VERSION "HNNBNNNYNNNNNNNNNNNNNNNNNNNNNNNNNNNNNNNNNN/4/%%%/4/'%**4NNN///"

NS_ :

BS_:

BU_: BAP_Tester ELV Gateway_Max HUD Kombi

BO_ 988 Gateway_73: 8 Gateway_Max
 SG_ Motor_12_alt : 0|1@1+ (1.0,0.0) [0.0|1] ""  Vector__XXX
 SG_ ESP_07_alt : 1|1@1+ (1.0,0.0) [0.0|1] ""  Kombi
 SG_ Getriebe_11_alt : 2|1@1+ (1.0,0.0) [0.0|1] ""  Vector__XXX
 SG_ Getriebe_13_alt : 3|1@1+ (1.0,0.0) [0.0|1] ""  Vector__XXX
 SG_ Getriebe_17_alt : 4|1@1+ (1.0,0.0) [0.0|1] ""  Vector__XXX
 SG_ TSK_06_alt : 5|1@1+ (1.0,0.0) [0.0|1] ""  Kombi
 SG_ Getriebe_14_alt : 6|1@1+ (1.0,0.0) [0.0|1] ""  Vector__XXX
 SG_ ESP_50_alt : 7|1@1+ (1.0,0.0) [0.0|1] ""  Vector__XXX
 SG_ MO_QBit_Drehzahl_01 : 8|1@1+ (1.0,0.0) [0.0|1] ""  Vector__XXX
 SG_ MKE_Texte : 9|2@1+ (1.0,0.0) [0.0|3] ""  Vector__XXX
 SG_ MKE_Stufe : 11|3@1+ (1.0,0.0) [0.0|7] ""  Vector__XXX
 SG_ TSK_Hauptschalter_GRA_ACC : 14|2@1+ (1.0,0.0) [0.0|3] ""  Kombi
 SG_ MO_Drehzahl_01 : 16|16@1+ (0.25,0) [0.00|16383.00] "Unit_MinutInver"  Vector__XXX
 SG_ TSK_Status : 32|3@1+ (1.0,0.0) [0.0|7] ""  Vector__XXX
 SG_ EPB_Schalterposition : 35|2@1+ (1.0,0.0) [0.0|3] ""  Vector__XXX
 SG_ GE_LaunchControl : 37|1@1+ (1.0,0.0) [0.0|1] ""  Vector__XXX
 SG_ GE_Fahrstufe : 40|4@1+ (1.0,0.0) [0.0|15] ""  Vector__XXX
 SG_ GE_Ursache_Fahrstufe_N : 44|1@1+ (1.0,0.0) [0.0|1] ""  Vector__XXX
 SG_ GE_Notlauf : 45|1@1+ (1.0,0.0) [0.0|1] ""  Vector__XXX
 SG_ ESP_Rollenmodus_Deaktivieren : 46|1@1+ (1.0,0.0) [0.0|1] ""  Kombi
 SG_ GE_Freilauf_Status : 47|3@1+ (1.0,0.0) [0.0|7] ""  Vector__XXX
 SG_ GE_Sperr_Info_WFS : 50|1@1+ (1.0,0.0) [0.0|1] ""  Vector__XXX
 SG_ TSK_Limiter_ausgewaehlt : 51|1@1+ (1.0,0.0) [0.0|1] ""  Vector__XXX
 SG_ GE_Veto_Rollfaehigkeit : 52|1@1+ (1.0,0.0) [0.0|1] ""  Vector__XXX
 SG_ EPB_Status_02 : 53|3@1+ (1.0,0.0) [0.0|7] ""  Vector__XXX
 SG_ ACC_Status_ACC : 56|3@1+ (1.0,0.0) [0.0|7] ""  Vector__XXX
 SG_ ACC_18_alt : 59|1@1+ (1.0,0.0) [0.0|1] ""  Vector__XXX
 SG_ Bel_DiETa_Mode2 : 60|2@1+ (1.0,0.0) [0.0|3] ""  Vector__XXX

BO_ 1002 Gateway_77: 8 Gateway_Max
 SG_ ESP_05_alt : 0|1@1+ (1.0,0.0) [0.0|1] ""  Vector__XXX
 SG_ Getriebe_14_alt : 1|1@1+ (1.0,0.0) [0.0|1] ""  Kombi
 SG_ Motor_11_alt : 2|1@1+ (1.0,0.0) [0.0|1] ""  Vector__XXX
 SG_ Motor_20_alt : 3|1@1+ (1.0,0.0) [0.0|1] ""  Vector__XXX
 SG_ EBKV_03_alt : 4|1@1+ (1.0,0.0) [0.0|1] ""  Vector__XXX
 SG_ AWV_03_alt : 5|1@1+ (1.0,0.0) [0.0|1] ""  Vector__XXX
 SG_ AWV_Verz_Freigabe : 6|1@1+ (1.0,0.0) [0.0|1] ""  Vector__XXX
 SG_ AWV_Verz_Anf : 7|10@1+ (0.024,-20.016) [-20.016|4.512] "Unit_MeterPerSeconSquar"  Vector__XXX
 SG_ Bel_DiETa_Mode : 17|2@1+ (1.0,0.0) [0.0|3] ""  Vector__XXX
 SG_ PaCo_DiETa_LED : 19|2@1+ (1.0,0.0) [0.0|3] ""  Vector__XXX
 SG_ RTM_Warnstatus : 21|2@1+ (1.0,0.0) [0.0|3] ""  Vector__XXX
 SG_ EBKV_Fahrer_bremst : 23|1@1+ (1.0,0.0) [0.0|1] ""  Vector__XXX
 SG_ AWV_Zielobjekttyp : 24|4@1+ (1.0,0.0) [0.0|15] ""  Vector__XXX
 SG_ ESP_Bremsdruck : 28|10@1+ (0.3,-30) [-30.0|276.6] "Unit_Bar"  Vector__XXX
 SG_ MO_Mom_Ist_Summe : 38|10@1+ (1,-509) [-509|509] ""  Vector__XXX
 SG_ MO_Fahrpedalrohwert_01 : 48|8@1+ (0.4,0) [0.0|101.6] "Unit_PerCent"  Vector__XXX
 SG_ GE_Sumpftemperatur : 56|8@1+ (1,-58) [-58|196] "Unit_DegreCelsi"  Kombi

BO_ 1003 Gateway_78: 8 Gateway_Max
 SG_ LH_EPS_02_alt : 0|1@1+ (1.0,0.0) [0.0|1] ""  Vector__XXX
 SG_ LIN_2_alt : 1|1@1+ (1.0,0.0) [0.0|1] ""  Vector__XXX
 SG_ Parkhilfe_01_alt : 2|1@1+ (1.0,0.0) [0.0|1] ""  Vector__XXX
 SG_ Motor_20_alt : 3|1@1+ (1.0,0.0) [0.0|1] ""  Vector__XXX
 SG_ LR_HZG_01_alt : 4|1@1+ (1.0,0.0) [0.0|1] ""  Vector__XXX
 SG_ Areaview_01_alt : 5|1@1+ (1.0,0.0) [0.0|1] ""  Vector__XXX
 SG_ EBKV_03_alt : 6|1@1+ (1.0,0.0) [0.0|1] ""  Vector__XXX
 SG_ ESP_50_alt : 7|1@1+ (1.0,0.0) [0.0|1] ""  Vector__XXX
 SG_ EPS_Lastinfo : 8|8@1+ (1,0) [0|253] "Unit_Amper"  Vector__XXX
 SG_ EFF_Verbrauch_STH : 16|7@1+ (0.01,0) [0.00|1.26] "Unit_LiterPerHour"  Kombi
 SG_ LR_HZG_Taster_on_off : 23|1@1+ (1.0,0.0) [0.0|1] ""  Vector__XXX
 SG_ LR_HZG_Temp_Sensor : 24|8@1+ (1,-50) [-50|104] "Unit_DegreCelsi"  Vector__XXX
 SG_ MFL_Signalhorn : 32|1@1+ (1.0,0.0) [0.0|1] ""  Vector__XXX
 SG_ EBKV_Fahrer_bremst : 33|1@1+ (1.0,0.0) [0.0|1] ""  Vector__XXX
 SG_ PH_Stoermeldung : 34|4@1+ (1.0,0.0) [0.0|15] ""  Vector__XXX
 SG_ MO_temporaere_Fahrerabwesenheit : 38|1@1+ (1.0,0.0) [0.0|1] ""  Vector__XXX
 SG_ AV_Umfeldbeleuchtung_Anf : 39|1@1+ (1.0,0.0) [0.0|1] ""  Vector__XXX
 SG_ MO_Fahrpedalrohwert_01 : 40|8@1+ (0.4,0) [0.0|101.6] "Unit_PerCent"  Vector__XXX
 SG_ LR_HZG_Konfiguration : 48|3@1+ (1.0,0.0) [0.0|7] ""  Vector__XXX
 SG_ EBKV_QBit_Fahrer_bremst : 51|1@1+ (1.0,0.0) [0.0|1] ""  Vector__XXX
 SG_ MO_QBit_Fahrpedalwerte_01 : 52|1@1+ (1.0,0.0) [0.0|1] ""  Vector__XXX
 SG_ ESP_QBit_Bremsdruck : 53|1@1+ (1.0,0.0) [0.0|1] ""  Vector__XXX
 SG_ ESP_Bremsdruck : 54|10@1+ (0.3,-30) [-30.0|276.6] "Unit_Bar"  Vector__XXX

BO_ 2583695384 Gateway_AuthTime_Req: 8 Gateway_Max
 SG_ Gateway_AuthTime_Req_Data : 0|64@1+ (1.0,0.0) [0.0|18446744073709551615] ""  Kombi

BO_ 2583826456 Gateway_AuthTime_Resp: 8 Kombi
 SG_ Gateway_AuthTime_Resp_Data : 0|64@1+ (1.0,0.0) [0.0|18446744073709551615] ""  Gateway_Max

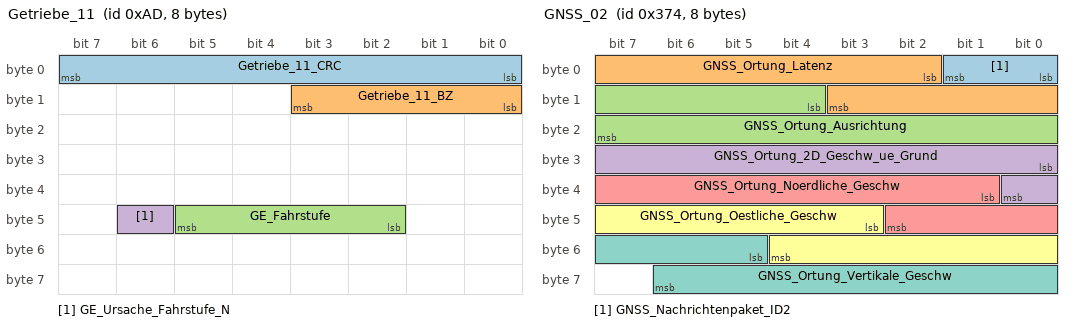
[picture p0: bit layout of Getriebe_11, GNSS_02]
BO_ 173 Getriebe_11: 8 Gateway_Max
 SG_ Getriebe_11_CRC : 0|8@1+ (1,0) [0|255] ""  Vector__XXX
 SG_ Getriebe_11_BZ : 8|4@1+ (1,0) [0|15] ""  Vector__XXX
 SG_ GE_Fahrstufe : 42|4@1+ (1.0,0.0) [0.0|15] ""  ELV
 SG_ GE_Ursache_Fahrstufe_N : 46|1@1+ (1.0,0.0) [0.0|1] ""  Vector__XXX

BO_ 884 GNSS_02: 8 Gateway_Max
 SG_ GNSS_Nachrichtenpaket_ID2 : 0|2@1+ (1,0) [0|3] "Unit_Bit"  Vector__XXX
 SG_ GNSS_Ortung_Latenz : 2|10@1+ (1,0) [0|1021] "Unit_MilliSecon"  Vector__XXX
 SG_ GNSS_Ortung_Ausrichtung : 12|12@1+ (0.1,0) [0.0|359.9] "Unit_DegreOfArc"  Vector__XXX
 SG_ GNSS_Ortung_2D_Geschw_ue_Grund : 24|9@1+ (0.25,0) [0.00|125.00] "Unit_MeterPerSecon"  Kombi
 SG_ GNSS_Ortung_Noerdliche_Geschw : 33|10@1+ (0.25,-125) [-125.00|125.00] "Unit_MeterPerSecon"  Vector__XXX
 SG_ GNSS_Ortung_Oestliche_Geschw : 43|10@1+ (0.25,-125) [-125.00|125.00] "Unit_MeterPerSecon"  Vector__XXX
 SG_ GNSS_Ortung_Vertikale_Geschw : 53|10@1+ (0.25,-125) [-125.00|125.00] "Unit_MeterPerSecon"  Vector__XXX

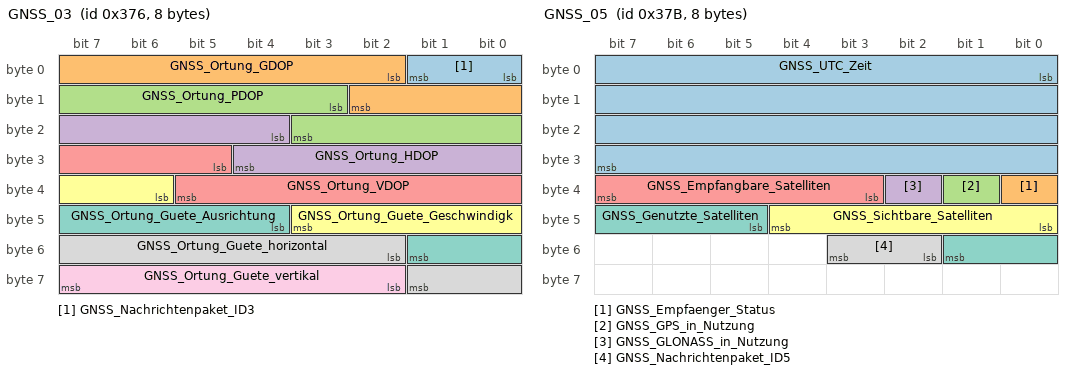
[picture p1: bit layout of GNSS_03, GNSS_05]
BO_ 886 GNSS_03: 8 Gateway_Max
 SG_ GNSS_Nachrichtenpaket_ID3 : 0|2@1+ (1,0) [0|3] "Unit_Bit"  Vector__XXX
 SG_ GNSS_Ortung_GDOP : 2|9@1+ (0.1,0) [0.0|50.0] "Unit_None"  Vector__XXX
 SG_ GNSS_Ortung_PDOP : 11|9@1+ (0.1,0) [0.0|50.0] "Unit_None"  Vector__XXX
 SG_ GNSS_Ortung_HDOP : 20|9@1+ (0.1,0) [0.0|50.0] "Unit_None"  Vector__XXX
 SG_ GNSS_Ortung_VDOP : 29|9@1+ (0.1,0) [0.0|50.0] "Unit_None"  Vector__XXX
 SG_ GNSS_Ortung_Guete_Geschwindigk : 38|6@1+ (0.05,0) [0.00|3.05] "Unit_MeterPerSecon"  Kombi
 SG_ GNSS_Ortung_Guete_Ausrichtung : 44|6@1+ (0.15,0) [0.00|9.15] "Unit_DegreOfArc"  Vector__XXX
 SG_ GNSS_Ortung_Guete_horizontal : 50|8@1+ (1,0) [0|250] "Unit_Meter"  Vector__XXX
 SG_ GNSS_Ortung_Guete_vertikal : 58|6@1+ (2,0) [0|122] "Unit_Meter"  Vector__XXX

BO_ 891 GNSS_05: 8 Gateway_Max
 SG_ GNSS_UTC_Zeit : 0|32@1+ (1,0) [1|4294967295] "Unit_Secon"  Kombi
 SG_ GNSS_Empfaenger_Status : 32|1@1+ (1.0,0.0) [0.0|1] ""  Vector__XXX
 SG_ GNSS_GPS_in_Nutzung : 33|1@1+ (1.0,0.0) [0.0|1] ""  Vector__XXX
 SG_ GNSS_GLONASS_in_Nutzung : 34|1@1+ (1.0,0.0) [0.0|1] ""  Vector__XXX
 SG_ GNSS_Empfangbare_Satelliten : 35|5@1+ (1,0) [1|30] "Unit_None"  Vector__XXX
 SG_ GNSS_Sichtbare_Satelliten : 40|5@1+ (1,0) [1|30] "Unit_None"  Vector__XXX
 SG_ GNSS_Genutzte_Satelliten : 45|5@1+ (1,0) [1|30] "Unit_None"  Vector__XXX
 SG_ GNSS_Nachrichtenpaket_ID5 : 50|2@1+ (1,0) [0|3] "Unit_Bit"  Kombi

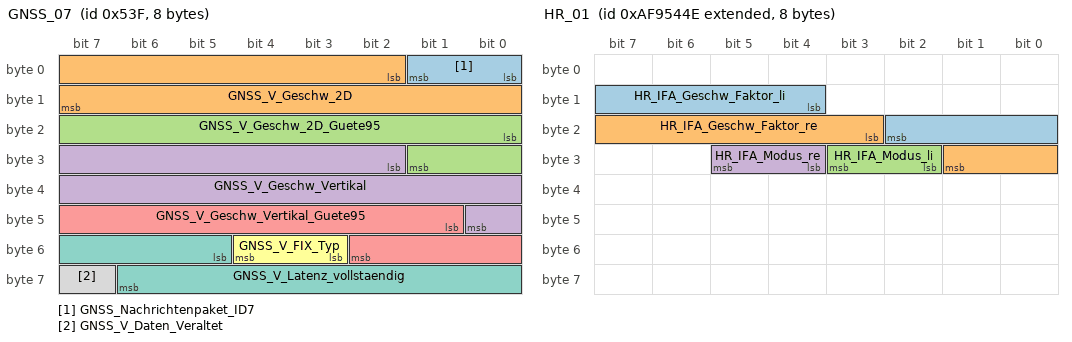
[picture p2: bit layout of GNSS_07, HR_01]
BO_ 1343 GNSS_07: 8 Gateway_Max
 SG_ GNSS_Nachrichtenpaket_ID7 : 0|2@1+ (1,0) [0|3] "Unit_None"  Kombi
 SG_ GNSS_V_Geschw_2D : 2|14@1+ (0.01,0) [0.00|163.00] "Unit_MeterPerSecon"  Kombi
 SG_ GNSS_V_Geschw_2D_Guete95 : 16|10@1+ (0.01,0) [0.00|10.00] "Unit_MeterPerSecon"  Kombi
 SG_ GNSS_V_Geschw_Vertikal : 26|15@1+ (0.01,-163) [-163.00|163.00] "Unit_MeterPerSecon"  Kombi
 SG_ GNSS_V_Geschw_Vertikal_Guete95 : 41|10@1+ (0.01,0) [0.00|10.00] "Unit_MeterPerSecon"  Kombi
 SG_ GNSS_V_FIX_Typ : 51|2@1+ (1.0,0.0) [0.0|3] ""  Kombi
 SG_ GNSS_V_Latenz_vollstaendig : 53|10@1+ (1,0) [0|1021] "Unit_MilliSecon"  Kombi
 SG_ GNSS_V_Daten_Veraltet : 63|1@1+ (1.0,0.0) [0.0|1] ""  Kombi

BO_ 299 GRA_ACC_01: 8 Gateway_Max
 SG_ GRA_ACC_01_CRC : 0|8@1+ (1,0) [0|255] ""  Vector__XXX
 SG_ GRA_ACC_01_BZ : 8|4@1+ (1,0) [0|15] ""  Vector__XXX
 SG_ GRA_Hauptschalter : 12|1@1+ (1.0,0.0) [0.0|1] ""  Vector__XXX
 SG_ GRA_Abbrechen : 13|1@1+ (1.0,0.0) [0.0|1] ""  Vector__XXX
 SG_ GRA_Typ_Hauptschalter : 14|1@1+ (1.0,0.0) [0.0|1] ""  Vector__XXX
 SG_ GRA_Limiter : 15|1@1+ (1.0,0.0) [0.0|1] ""  Vector__XXX
 SG_ GRA_Tip_Setzen : 16|1@1+ (1.0,0.0) [0.0|1] ""  HUD
 SG_ GRA_Tip_Hoch : 17|1@1+ (1.0,0.0) [0.0|1] ""  HUD
 SG_ GRA_Tip_Runter : 18|1@1+ (1.0,0.0) [0.0|1] ""  HUD
 SG_ GRA_Tip_Wiederaufnahme : 19|1@1+ (1.0,0.0) [0.0|1] ""  HUD
 SG_ GRA_Verstellung_Zeitluecke : 20|2@1+ (1.0,0.0) [0.0|3] ""  Vector__XXX
 SG_ GRA_Codierung : 22|2@1+ (1.0,0.0) [0.0|3] ""  Vector__XXX
 SG_ GRA_Fehler : 24|1@1+ (1.0,0.0) [0.0|1] ""  Vector__XXX
 SG_ GRA_LIM_Taste_verfuegbar : 25|1@1+ (1.0,0.0) [0.0|1] ""  Vector__XXX
 SG_ GRA_Tip_Stufe_2 : 26|1@1+ (1.0,0.0) [0.0|1] ""  Vector__XXX
 SG_ GRA_Typ_Bedienteil : 27|3@1+ (1.0,0.0) [0.0|7] ""  Vector__XXX
 SG_ GRA_TravelAssist : 30|1@1+ (1.0,0.0) [0.0|1] ""  Vector__XXX
 SG_ GRA_PIT_Limiter : 31|1@1+ (1.0,0.0) [0.0|1] ""  Vector__XXX
 SG_ GRA_reserveByte5 : 32|8@1+ (1.0,0.0) [0.0|255] ""  Vector__XXX
 SG_ GRA_reserveByte6 : 40|8@1+ (1.0,0.0) [0.0|255] ""  Vector__XXX
 SG_ GRA_reserveByte7 : 48|8@1+ (1.0,0.0) [0.0|255] ""  Vector__XXX
 SG_ GRA_reserveByte8 : 56|8@1+ (1.0,0.0) [0.0|255] ""  Vector__XXX

BO_ 1410 HDSG_01: 4 Gateway_Max
 SG_ HD_Endstellung_oben : 0|1@1+ (1.0,0.0) [0.0|1] ""  Vector__XXX
 SG_ HD_Endstellung_unten : 1|1@1+ (1.0,0.0) [0.0|1] ""  Vector__XXX
 SG_ HD_Bewegung_auf : 2|1@1+ (1.0,0.0) [0.0|1] ""  Vector__XXX
 SG_ HD_Bewegung_zu : 3|1@1+ (1.0,0.0) [0.0|1] ""  Vector__XXX
 SG_ HD_Innentaster_betaetigt : 4|1@1+ (1.0,0.0) [0.0|1] ""  Vector__XXX
 SG_ HD_Kupp_Ma_aktiv : 5|1@1+ (1.0,0.0) [0.0|1] ""  Vector__XXX
 SG_ HD_Kupp_Sl_aktiv : 6|1@1+ (1.0,0.0) [0.0|1] ""  Vector__XXX
 SG_ HD_UeKB_erkannt : 7|1@1+ (1.0,0.0) [0.0|1] ""  Vector__XXX
 SG_ HD_Position : 8|8@1+ (1,0) [0|100] "Unit_PerCent"  Vector__XXX
 SG_ HD_SG_MA_KD_Fehler : 16|1@1+ (1.0,0.0) [0.0|1] ""  Vector__XXX
 SG_ HD_SG_SL_KD_Fehler : 17|1@1+ (1.0,0.0) [0.0|1] ""  Vector__XXX
 SG_ HD_Taster_defekt : 18|1@1+ (1.0,0.0) [0.0|1] ""  Vector__XXX
 SG_ HD_Spannung : 19|1@1+ (1.0,0.0) [0.0|1] ""  Vector__XXX
 SG_ HD_Rueckmeld_prog : 20|1@1+ (1.0,0.0) [0.0|1] ""  Vector__XXX
 SG_ HD_Verriegelungstaster_betaetigt : 21|1@1+ (1.0,0.0) [0.0|1] ""  Vector__XXX
 SG_ HD_Verr_Taster_betaetigt_inv : 22|1@1+ (1.0,0.0) [0.0|1] ""  Vector__XXX
 SG_ HD_ZZH_Schalter_S3 : 23|1@1+ (1.0,0.0) [0.0|1] ""  Vector__XXX
 SG_ HDSG_Anf_Umluftklappe : 31|1@1+ (1.0,0.0) [0.0|1] ""  Vector__XXX

BO_ 588 Heckradar_01: 16 Gateway_Max
 SG_ SWA_LED_Hell_BFS : 12|7@1+ (1,0) [0|100] "Unit_PerCent"  Vector__XXX
 SG_ SWA_LED_Hell_FS : 19|7@1+ (1,0) [0|100] "Unit_PerCent"  Vector__XXX
 SG_ SWA_LED_Ausgabemodus_BFS : 26|3@1+ (1.0,0.0) [0.0|7] ""  Vector__XXX
 SG_ SWA_LED_Ausgabemodus_FS : 29|3@1+ (1.0,0.0) [0.0|7] ""  Vector__XXX
 SG_ SWA_Status : 32|2@1+ (1.0,0.0) [0.0|3] ""  Vector__XXX
 SG_ ASW_Ton_Richtung_VL : 34|1@1+ (1.0,0.0) [0.0|1] ""  Vector__XXX
 SG_ ASW_Ton_Richtung_VR : 35|1@1+ (1.0,0.0) [0.0|1] ""  Vector__XXX
 SG_ ASW_Ton_Richtung_HL : 36|1@1+ (1.0,0.0) [0.0|1] ""  HUD
 SG_ ASW_Ton_Richtung_HR : 37|1@1+ (1.0,0.0) [0.0|1] ""  HUD
 SG_ SWA_Status_System : 38|2@1+ (1.0,0.0) [0.0|3] ""  Vector__XXX
 SG_ SWA_Brightness_Mode_FPM : 40|4@1+ (1.0,0.0) [0.0|15] ""  Vector__XXX
 SG_ SWA_Status_KuFu : 44|2@1+ (1.0,0.0) [0.0|3] ""  Kombi
 SG_ SWA_Infostufe_Assist_li : 46|1@1+ (1.0,0.0) [0.0|1] ""  Vector__XXX
 SG_ SWA_Infostufe_Assist_re : 47|1@1+ (1.0,0.0) [0.0|1] ""  Vector__XXX
 SG_ SWA_Warnstufe_Assist_li : 48|1@1+ (1.0,0.0) [0.0|1] ""  Vector__XXX
 SG_ SWA_Warnstufe_Assist_re : 49|1@1+ (1.0,0.0) [0.0|1] ""  Vector__XXX
 SG_ SWA_Modus_System : 50|3@1+ (1.0,0.0) [0.0|7] ""  Vector__XXX
 SG_ SWA_Kombiausgabe : 53|3@1+ (1.0,0.0) [0.0|7] ""  Vector__XXX
 SG_ ASW_Kombiausgabe : 56|3@1+ (1.0,0.0) [0.0|7] ""  Vector__XXX
 SG_ SWA_Kombiwarnung : 59|1@1+ (1.0,0.0) [0.0|1] ""  Vector__XXX
 SG_ ASW_Ausgabemodus_HBFS : 64|3@1+ (1.0,0.0) [0.0|7] ""  Vector__XXX
 SG_ ASW_Ausgabemodus_HFS : 67|3@1+ (1.0,0.0) [0.0|7] ""  Vector__XXX
 SG_ ASW_Akustik_Einstellung : 70|1@1+ (1.0,0.0) [0.0|1] ""  Vector__XXX
 SG_ SWA_Anzeigen : 76|4@1+ (1.0,0.0) [0.0|15] ""  Kombi
 SG_ SWA_Blindheit_erkannt : 80|1@1+ (1.0,0.0) [0.0|1] ""  Vector__XXX
 SG_ SWA_rel_Nichtverf : 81|1@1+ (1.0,0.0) [0.0|1] ""  Vector__XXX
 SG_ SWA_rel_Fehler : 82|1@1+ (1.0,0.0) [0.0|1] ""  Vector__XXX
 SG_ SWA_Sta_aktiv : 83|1@1+ (1.0,0.0) [0.0|1] ""  Kombi
 SG_ SWA_Sta_passiv : 84|1@1+ (1.0,0.0) [0.0|1] ""  Kombi
 SG_ SWA_FT_RueckLED : 85|1@1+ (1.0,0.0) [0.0|1] ""  Vector__XXX
 SG_ ASW_Status : 86|2@1+ (1.0,0.0) [0.0|3] ""  Vector__XXX
 SG_ SWA_Standziele_li : 88|1@1+ (1.0,0.0) [0.0|1] ""  Vector__XXX
 SG_ ASW_Ausgabemodus_BFS : 89|3@1+ (1.0,0.0) [0.0|7] ""  Vector__XXX
 SG_ ASW_Warnung_FS : 92|1@1+ (1.0,0.0) [0.0|1] ""  Vector__XXX
 SG_ ASW_Warnung_BFS : 93|1@1+ (1.0,0.0) [0.0|1] ""  Vector__XXX
 SG_ ASW_Kombitexte : 94|3@1+ (1.0,0.0) [0.0|7] ""  Kombi
 SG_ ASW_Modus : 98|3@1+ (1.0,0.0) [0.0|7] ""  Vector__XXX
 SG_ SWA_Modus : 101|3@1+ (1.0,0.0) [0.0|7] ""  Vector__XXX
 SG_ SWA_Standziele_re : 104|1@1+ (1.0,0.0) [0.0|1] ""  Vector__XXX
 SG_ ASW_Ausgabemodus_FS : 105|3@1+ (1.0,0.0) [0.0|7] ""  Vector__XXX
 SG_ HRE_Anzeigetexte : 108|4@1+ (1.0,0.0) [0.0|15] ""  HUD,Kombi
 SG_ SWA_Gischtzaehler : 112|7@1+ (1,0) [0|100] "Unit_PerCent"  Vector__XXX
 SG_ SWA_Blindheitsverdacht : 119|1@1+ (1.0,0.0) [0.0|1] ""  Vector__XXX
 SG_ Heckradar_Kombitexte : 120|5@1+ (1.0,0.0) [0.0|31] ""  Kombi
 SG_ RCTA_Kombitexte : 125|3@1+ (1.0,0.0) [0.0|7] ""  Kombi

BO_ 589 Heckradar_02: 64 Gateway_Max
 SG_ SWA_StrukturLinks_querAbstand : 12|9@1+ (0.03125,0) [0.00000|15.93750] "Unit_Meter"  Vector__XXX
 SG_ SWA_StrukturLinks_Typ : 21|3@1+ (1.0,0.0) [0.0|7] ""  Vector__XXX
 SG_ SWA_Umfeld_Zeitstempel : 24|16@1+ (0.1,0) [0.0|6553.5] "Unit_MilliSecon"  Vector__XXX
 SG_ SWA_Umfeld_Zeitstempel_Status : 54|3@1+ (1.0,0.0) [0.0|7] ""  Vector__XXX
 SG_ SWA_Kolonne_li : 57|1@1+ (1.0,0.0) [0.0|1] ""  Vector__XXX
 SG_ SWA_Kolonne_mi : 58|1@1+ (1.0,0.0) [0.0|1] ""  Vector__XXX
 SG_ SWA_Kolonne_re : 59|1@1+ (1.0,0.0) [0.0|1] ""  Vector__XXX
 SG_ SWA_Infostufe_SWA_li : 60|1@1+ (1.0,0.0) [0.0|1] ""  Kombi
 SG_ SWA_Infostufe_SWA_re : 61|1@1+ (1.0,0.0) [0.0|1] ""  Kombi
 SG_ SWA_Warnung_SWA_li : 62|1@1+ (1.0,0.0) [0.0|1] ""  Kombi
 SG_ SWA_Warnung_SWA_re : 63|1@1+ (1.0,0.0) [0.0|1] ""  Kombi
 SG_ SWA_Obj_Kurvenradius : 64|16@1+ (1,-32767) [-32767|32767] "Unit_Meter"  Vector__XXX
 SG_ SWA_StrukturRechts_querAbstand : 80|9@1+ (0.03125,0) [0.00000|15.93750] "Unit_Meter"  Vector__XXX
 SG_ SWA_StrukturRechts_Typ : 89|3@1+ (1.0,0.0) [0.0|7] ""  Vector__XXX
 SG_ SWA_Obj_01_Gemessen : 92|1@1+ (1.0,0.0) [0.0|1] ""  Vector__XXX
 SG_ SWA_Obj_01_ID : 93|5@1+ (1,0) [1|30] ""  Vector__XXX
 SG_ SWA_Obj_02_Gemessen : 98|1@1+ (1.0,0.0) [0.0|1] ""  Vector__XXX
 SG_ SWA_Obj_02_ID : 99|5@1+ (1,0) [1|30] ""  Vector__XXX
 SG_ SWA_Obj_03_Gemessen : 104|1@1+ (1.0,0.0) [0.0|1] ""  Vector__XXX
 SG_ SWA_Obj_03_ID : 105|5@1+ (1,0) [1|30] ""  Vector__XXX
 SG_ SWA_Obj_04_Gemessen : 110|1@1+ (1.0,0.0) [0.0|1] ""  Vector__XXX
 SG_ SWA_Obj_04_ID : 111|5@1+ (1,0) [1|30] ""  Vector__XXX
 SG_ SWA_Obj_05_Gemessen : 116|1@1+ (1.0,0.0) [0.0|1] ""  Vector__XXX
 SG_ SWA_Obj_05_ID : 117|5@1+ (1,0) [1|30] ""  Vector__XXX
 SG_ SWA_Obj_06_Gemessen : 122|1@1+ (1.0,0.0) [0.0|1] ""  Vector__XXX
 SG_ SWA_Obj_06_ID : 123|5@1+ (1,0) [1|30] ""  Vector__XXX
 SG_ SWA_Obj_01_GeschwRelX : 128|9@1+ (0.25,-37.5) [-37.50|90.00] "Unit_MeterPerSecon"  Vector__XXX
 SG_ SWA_Obj_01_Breite : 137|7@1+ (0.03125,0) [0.00000|3.93750] "Unit_Meter"  Vector__XXX
 SG_ SWA_Obj_01_GeschwRelY : 144|9@1+ (0.03125,-7.9375) [-7.93750|8.00000] "Unit_MeterPerSecon"  Vector__XXX
 SG_ SWA_Obj_01_Existenzwahrsch : 153|7@1+ (1,0) [0|100] "Unit_PerCent"  Vector__XXX
 SG_ SWA_Obj_01_Objektklasse : 160|4@1+ (1.0,0.0) [0.0|15] ""  Vector__XXX
 SG_ SWA_Obj_01_ReferenzPkt : 164|4@1+ (1.0,0.0) [0.0|15] ""  Vector__XXX
 SG_ SWA_Obj_01_PositionX : 168|9@1+ (0.25,-102.5) [-102.50|25.00] "Unit_Meter"  Vector__XXX
 SG_ SWA_Obj_01_Laenge : 177|7@1+ (0.25,0) [0.00|31.50] "Unit_Meter"  Vector__XXX
 SG_ SWA_Obj_01_PositionY : 184|8@1+ (0.125,-16) [-16.000|15.750] "Unit_Meter"  Vector__XXX
 SG_ SWA_Obj_02_GeschwRelX : 192|9@1+ (0.25,-37.5) [-37.50|90.00] "Unit_MeterPerSecon"  Vector__XXX
 SG_ SWA_Obj_02_Breite : 201|7@1+ (0.03125,0) [0.00000|3.93750] "Unit_Meter"  Vector__XXX
 SG_ SWA_Obj_02_GeschwRelY : 208|9@1+ (0.03125,-7.9375) [-7.93750|8.00000] "Unit_MeterPerSecon"  Vector__XXX
 SG_ SWA_Obj_02_Existenzwahrsch : 217|7@1+ (1,0) [0|100] "Unit_PerCent"  Vector__XXX
 SG_ SWA_Obj_02_Objektklasse : 224|4@1+ (1.0,0.0) [0.0|15] ""  Vector__XXX
 SG_ SWA_Obj_02_ReferenzPkt : 228|4@1+ (1.0,0.0) [0.0|15] ""  Vector__XXX
 SG_ SWA_Obj_02_PositionX : 232|9@1+ (0.25,-102.5) [-102.50|25.00] "Unit_Meter"  Vector__XXX
 SG_ SWA_Obj_02_Laenge : 241|7@1+ (0.25,0) [0.00|31.50] "Unit_Meter"  Vector__XXX
 SG_ SWA_Obj_02_PositionY : 248|8@1+ (0.125,-16) [-16.000|15.750] "Unit_Meter"  Vector__XXX
 SG_ SWA_Obj_03_GeschwRelX : 256|9@1+ (0.25,-37.5) [-37.50|90.00] "Unit_MeterPerSecon"  Vector__XXX
 SG_ SWA_Obj_03_Breite : 265|7@1+ (0.03125,0) [0.00000|3.93750] "Unit_Meter"  Vector__XXX
 SG_ SWA_Obj_03_GeschwRelY : 272|9@1+ (0.03125,-7.9375) [-7.93750|8.00000] "Unit_MeterPerSecon"  Vector__XXX
 SG_ SWA_Obj_03_Existenzwahrsch : 281|7@1+ (1,0) [0|100] "Unit_PerCent"  Vector__XXX
 SG_ SWA_Obj_03_Objektklasse : 288|4@1+ (1.0,0.0) [0.0|15] ""  Vector__XXX
 SG_ SWA_Obj_03_ReferenzPkt : 292|4@1+ (1.0,0.0) [0.0|15] ""  Vector__XXX
 SG_ SWA_Obj_03_PositionX : 296|9@1+ (0.25,-102.5) [-102.50|25.00] "Unit_Meter"  Vector__XXX
 SG_ SWA_Obj_03_Laenge : 305|7@1+ (0.25,0) [0.00|31.50] "Unit_Meter"  Vector__XXX
 SG_ SWA_Obj_03_PositionY : 312|8@1+ (0.125,-16) [-16.000|15.750] "Unit_Meter"  Vector__XXX
 SG_ SWA_Obj_04_GeschwRelX : 320|9@1+ (0.25,-37.5) [-37.50|90.00] "Unit_MeterPerSecon"  Vector__XXX
 SG_ SWA_Obj_04_Breite : 329|7@1+ (0.03125,0) [0.00000|3.93750] "Unit_Meter"  Vector__XXX
 SG_ SWA_Obj_04_GeschwRelY : 336|9@1+ (0.03125,-7.9375) [-7.93750|8.00000] "Unit_MeterPerSecon"  Vector__XXX
 SG_ SWA_Obj_04_Existenzwahrsch : 345|7@1+ (1,0) [0|100] "Unit_PerCent"  Vector__XXX
 SG_ SWA_Obj_04_Objektklasse : 352|4@1+ (1.0,0.0) [0.0|15] ""  Vector__XXX
 SG_ SWA_Obj_04_ReferenzPkt : 356|4@1+ (1.0,0.0) [0.0|15] ""  Vector__XXX
 SG_ SWA_Obj_04_PositionX : 360|9@1+ (0.25,-102.5) [-102.50|25.00] "Unit_Meter"  Vector__XXX
 SG_ SWA_Obj_04_Laenge : 369|7@1+ (0.25,0) [0.00|31.50] "Unit_Meter"  Vector__XXX
 SG_ SWA_Obj_04_PositionY : 376|8@1+ (0.125,-16) [-16.000|15.750] "Unit_Meter"  Vector__XXX
 SG_ SWA_Obj_05_GeschwRelX : 384|9@1+ (0.25,-37.5) [-37.50|90.00] "Unit_MeterPerSecon"  Vector__XXX
 SG_ SWA_Obj_05_Breite : 393|7@1+ (0.03125,0) [0.00000|3.93750] "Unit_Meter"  Vector__XXX
 SG_ SWA_Obj_05_GeschwRelY : 400|9@1+ (0.03125,-7.9375) [-7.93750|8.00000] "Unit_MeterPerSecon"  Vector__XXX
 SG_ SWA_Obj_05_Existenzwahrsch : 409|7@1+ (1,0) [0|100] "Unit_PerCent"  Vector__XXX
 SG_ SWA_Obj_05_Objektklasse : 416|4@1+ (1.0,0.0) [0.0|15] ""  Vector__XXX
 SG_ SWA_Obj_05_ReferenzPkt : 420|4@1+ (1.0,0.0) [0.0|15] ""  Vector__XXX
 SG_ SWA_Obj_05_PositionX : 424|9@1+ (0.25,-102.5) [-102.50|25.00] "Unit_Meter"  Vector__XXX
 SG_ SWA_Obj_05_Laenge : 433|7@1+ (0.25,0) [0.00|31.50] "Unit_Meter"  Vector__XXX
 SG_ SWA_Obj_05_PositionY : 440|8@1+ (0.125,-16) [-16.000|15.750] "Unit_Meter"  Vector__XXX
 SG_ SWA_Obj_06_GeschwRelX : 448|9@1+ (0.25,-37.5) [-37.50|90.00] "Unit_MeterPerSecon"  Vector__XXX
 SG_ SWA_Obj_06_Breite : 457|7@1+ (0.03125,0) [0.00000|3.93750] "Unit_Meter"  Vector__XXX
 SG_ SWA_Obj_06_GeschwRelY : 464|9@1+ (0.03125,-7.9375) [-7.93750|8.00000] "Unit_MeterPerSecon"  Vector__XXX
 SG_ SWA_Obj_06_Existenzwahrsch : 473|7@1+ (1,0) [0|100] "Unit_PerCent"  Vector__XXX
 SG_ SWA_Obj_06_Objektklasse : 480|4@1+ (1.0,0.0) [0.0|15] ""  Vector__XXX
 SG_ SWA_Obj_06_ReferenzPkt : 484|4@1+ (1.0,0.0) [0.0|15] ""  Vector__XXX
 SG_ SWA_Obj_06_PositionX : 488|9@1+ (0.25,-102.5) [-102.50|25.00] "Unit_Meter"  Vector__XXX
 SG_ SWA_Obj_06_Laenge : 497|7@1+ (0.25,0) [0.00|31.50] "Unit_Meter"  Vector__XXX
 SG_ SWA_Obj_06_PositionY : 504|8@1+ (0.125,-16) [-16.000|15.750] "Unit_Meter"  Vector__XXX

BO_ 2331595854 HR_01: 8 Gateway_Max
 SG_ HR_IFA_Geschw_Faktor_li : 12|7@1+ (1,0) [0|100] "Unit_PerCent"  Kombi
 SG_ HR_IFA_Geschw_Faktor_re : 19|7@1+ (1,0) [0|100] "Unit_PerCent"  Kombi
 SG_ HR_IFA_Modus_li : 26|2@1+ (1.0,0.0) [0.0|3] ""  Kombi
 SG_ HR_IFA_Modus_re : 28|2@1+ (1.0,0.0) [0.0|3] ""  Kombi

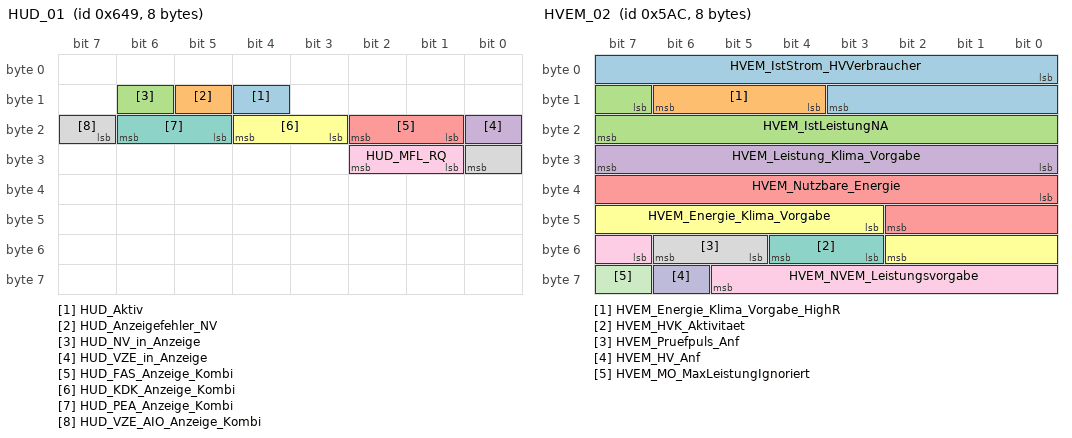
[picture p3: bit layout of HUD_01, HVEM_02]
BO_ 1609 HUD_01: 8 HUD
 SG_ HUD_Aktiv : 12|1@1+ (1.0,0.0) [0.0|1] ""  Vector__XXX
 SG_ HUD_Anzeigefehler_NV : 13|1@1+ (1.0,0.0) [0.0|1] ""  Vector__XXX
 SG_ HUD_NV_in_Anzeige : 14|1@1+ (1.0,0.0) [0.0|1] ""  Vector__XXX
 SG_ HUD_VZE_in_Anzeige : 16|1@1+ (1.0,0.0) [0.0|1] ""  Vector__XXX
 SG_ HUD_FAS_Anzeige_Kombi : 17|2@1+ (1.0,0.0) [0.0|3] ""  Vector__XXX
 SG_ HUD_KDK_Anzeige_Kombi : 19|2@1+ (1.0,0.0) [0.0|3] ""  Vector__XXX
 SG_ HUD_PEA_Anzeige_Kombi : 21|2@1+ (1.0,0.0) [0.0|3] ""  Vector__XXX
 SG_ HUD_VZE_AIO_Anzeige_Kombi : 23|2@1+ (1.0,0.0) [0.0|3] ""  Vector__XXX
 SG_ HUD_MFL_RQ : 25|2@1+ (1.0,0.0) [0.0|3] ""  Kombi

BO_ 1452 HVEM_02: 8 Gateway_Max
 SG_ HVEM_IstStrom_HVVerbraucher : 0|12@1+ (0.1,-204.7) [-204.7|204.6] "Unit_Amper"  Vector__XXX
 SG_ HVEM_Energie_Klima_Vorgabe_HighR : 12|3@1+ (10,0) [0|50] "Unit_WattHour"  Vector__XXX
 SG_ HVEM_IstLeistungNA : 15|9@1+ (50,0) [0|25450] "Unit_Watt"  Vector__XXX
 SG_ HVEM_Leistung_Klima_Vorgabe : 24|8@1+ (50,0) [0|12650] "Unit_Watt"  Vector__XXX
 SG_ HVEM_Nutzbare_Energie : 32|11@1+ (50,0) [0|102200] "Unit_WattHour"  Vector__XXX
 SG_ HVEM_Energie_Klima_Vorgabe : 43|8@1+ (50,0) [0|12650] "Unit_WattHour"  Vector__XXX
 SG_ HVEM_HVK_Aktivitaet : 51|2@1+ (1.0,0.0) [0.0|3] ""  Vector__XXX
 SG_ HVEM_Pruefpuls_Anf : 53|2@1+ (1.0,0.0) [0.0|3] ""  Vector__XXX
 SG_ HVEM_NVEM_Leistungsvorgabe : 55|7@1+ (50,0) [0|6250] "Unit_Watt"  Vector__XXX
 SG_ HVEM_HV_Anf : 62|1@1+ (1.0,0.0) [0.0|1] ""  Vector__XXX
 SG_ HVEM_MO_MaxLeistungIgnoriert : 63|1@1+ (1.0,0.0) [0.0|1] ""  Vector__XXX

BO_ 1283 HVK_01: 8 Gateway_Max
 SG_ HVK_01_CRC : 0|8@1+ (1,0) [0|255] ""  Vector__XXX
 SG_ HVK_01_BZ : 8|4@1+ (1,0) [0|15] ""  Vector__XXX
 SG_ HVK_Istmodus_Anf : 12|1@1+ (1.0,0.0) [0.0|1] ""  Vector__XXX
 SG_ HVK_TN1_Sollmodus : 13|2@1+ (1.0,0.0) [0.0|3] ""  Vector__XXX
 SG_ HVK_Vorladung_aktiv : 15|1@1+ (1.0,0.0) [0.0|1] ""  Vector__XXX
 SG_ HVK_BMS_Sollmodus : 24|3@1+ (1.0,0.0) [0.0|7] ""  Vector__XXX
 SG_ HVK_DCDC_Sollmodus : 27|3@1+ (1.0,0.0) [0.0|7] ""  Vector__XXX
 SG_ HVK_EKK_Sollmodus : 30|3@1+ (1.0,0.0) [0.0|7] ""  Vector__XXX
 SG_ HVK_HVPTC_Sollmodus : 33|3@1+ (1.0,0.0) [0.0|7] ""  Vector__XXX
 SG_ HVK_HVLM_Sollmodus : 36|3@1+ (1.0,0.0) [0.0|7] ""  Vector__XXX
 SG_ HVK_HV_Netz_Warnungen : 39|2@1+ (1.0,0.0) [0.0|3] ""  Kombi
 SG_ HV_Bordnetz_aktiv : 41|1@1+ (1.0,0.0) [0.0|1] ""  Vector__XXX
 SG_ HV_Bordnetz_Fehler : 42|1@1+ (1.0,0.0) [0.0|1] ""  Vector__XXX
 SG_ HVK_Gesamtst_Spgfreiheit : 43|2@1+ (1.0,0.0) [0.0|3] ""  Kombi
 SG_ HVK_AktiveEntladung_Anf : 45|1@1+ (1.0,0.0) [0.0|1] ""  Vector__XXX
 SG_ HVK_HVEM_Freigabe : 46|2@1+ (1.0,0.0) [0.0|3] ""  Vector__XXX
 SG_ HVK_Notabschaltung_Anf : 48|2@1+ (1.0,0.0) [0.0|3] ""  Vector__XXX
 SG_ HVK_Iso_Messung_Start : 50|3@1+ (1.0,0.0) [0.0|7] ""  Vector__XXX
 SG_ HVK_Ladebereit : 53|3@1+ (1.0,0.0) [0.0|7] ""  Vector__XXX
 SG_ HVK_PPulsFreigabe : 56|2@1+ (1.0,0.0) [0.0|3] ""  Vector__XXX

BO_ 1428 HVLM_05: 8 Gateway_Max
 SG_ HVLM_Warnmeldungen : 0|5@1+ (1.0,0.0) [0.0|31] ""  Kombi
 SG_ HVLM_Restladezeit_HV_Bat_02 : 12|9@1+ (5,0) [0|2545] "Unit_Minut"  Kombi
 SG_ HVLM_Lademodus_HV_Bat : 21|2@1+ (1.0,0.0) [0.0|3] ""  Vector__XXX
 SG_ HVLM_VK_STH_Einsatz : 23|3@1+ (1.0,0.0) [0.0|7] ""  Vector__XXX
 SG_ HVLM_Anzeigetexte : 26|3@1+ (1.0,0.0) [0.0|7] ""  Kombi
 SG_ HVLM_Bat_laden_aktiv : 29|1@1+ (1.0,0.0) [0.0|1] ""  Kombi
 SG_ HVLM_HVEM_MaxLeistung : 30|9@1+ (50,0) [0|25450] "Unit_Watt"  Vector__XXX
 SG_ HVLM_Standklima_Timer_Status : 39|1@1+ (1.0,0.0) [0.0|1] ""  Vector__XXX
 SG_ HVLM_Fehler_Ladestecker : 40|1@1+ (1.0,0.0) [0.0|1] ""  Vector__XXX
 SG_ HVLM_Fehler_Verriegelung : 41|1@1+ (1.0,0.0) [0.0|1] ""  Vector__XXX
 SG_ HVLM_Ladeart : 42|2@1+ (1.0,0.0) [0.0|3] ""  Kombi
 SG_ HVLM_Status_Netz : 44|1@1+ (1.0,0.0) [0.0|1] ""  Vector__XXX
 SG_ HVLM_HV_Anf : 45|2@1+ (1.0,0.0) [0.0|3] ""  Vector__XXX
 SG_ HVLM_VK_Anf : 47|1@1+ (1.0,0.0) [0.0|1] ""  Vector__XXX
 SG_ HVLM_Ladesystemhinweise : 48|2@1+ (1.0,0.0) [0.0|3] ""  Vector__XXX
 SG_ HVLM_VK_Modus : 50|2@1+ (1.0,0.0) [0.0|3] ""  Vector__XXX
 SG_ HVLM_Stecker_Status : 52|2@1+ (1.0,0.0) [0.0|3] ""  Kombi
 SG_ HVLM_Langzeit_Laden : 54|2@1+ (1.0,0.0) [0.0|3] ""  Vector__XXX
 SG_ HVLM_Klima_Temp : 56|5@1+ (0.5,15.5) [15.5|29.5] "Unit_DegreCelsi"  Vector__XXX
 SG_ HVLM_HSH_Anf : 61|1@1+ (1.0,0.0) [0.0|1] ""  Vector__XXX
 SG_ HVLM_Bat_Konditionierung_Anf : 62|1@1+ (1.0,0.0) [0.0|1] ""  Vector__XXX
 SG_ HVLM_FSH_Anf : 63|1@1+ (1.0,0.0) [0.0|1] ""  Vector__XXX

BO_ 27 IMMO_ELV_Antwort: 8 Gateway_Max
 SG_ WFS_IMMO_ELV_CRC : 0|32@1+ (1.0,0.0) [0.0|4294967295] ""  ELV
 SG_ WFS_IMMO_ELV_RND : 32|32@1+ (1.0,0.0) [0.0|4294967295] ""  ELV

BO_ 2583720728 Info_El_AuthTime_Req: 8 Gateway_Max
 SG_ Info_El_AuthTime_Req_Data : 0|64@1+ (1.0,0.0) [0.0|18446744073709551615] ""  Kombi

BO_ 2583851800 Info_El_AuthTime_Resp: 8 Kombi
 SG_ Info_El_AuthTime_Resp_Data : 0|64@1+ (1.0,0.0) [0.0|18446744073709551615] ""  Gateway_Max

BO_ 1524 Innenlicht_11: 8 Gateway_Max
 SG_ IL_Dimmung_V_Tuerkontur : 0|8@1+ (1,0) [0|100] "Unit_PerCent"  Vector__XXX
 SG_ IL_Dimmung_H_Tuerkontur : 8|8@1+ (1,0) [0|100] "Unit_PerCent"  Vector__XXX
 SG_ IL_Dimmung_Tuerinnengriff : 16|8@1+ (1,0) [0|100] "Unit_PerCent"  Vector__XXX
 SG_ IL_Dimmung_Umfeldbel : 24|8@1+ (1,0) [0|100] "Unit_PerCent"  Vector__XXX
 SG_ IL_Bel_FS_Ausstieg : 32|1@1+ (1.0,0.0) [0.0|1] ""  Vector__XXX
 SG_ IL_Bel_BFS_Ausstieg : 33|1@1+ (1.0,0.0) [0.0|1] ""  Vector__XXX
 SG_ IL_Bel_HFS_Ausstieg : 34|1@1+ (1.0,0.0) [0.0|1] ""  Vector__XXX
 SG_ IL_Bel_HBFS_Ausstieg : 35|1@1+ (1.0,0.0) [0.0|1] ""  Vector__XXX
 SG_ BCM1_Innenlicht_gedimmt_V : 36|1@1+ (1.0,0.0) [0.0|1] ""  Vector__XXX
 SG_ BCM1_Innenlicht_gedimmt_H : 37|1@1+ (1.0,0.0) [0.0|1] ""  Vector__XXX
 SG_ IL_Innenlicht_aktiv : 38|1@1+ (1.0,0.0) [0.0|1] ""  Vector__XXX
 SG_ IL_Klemme_30G_aktiv : 39|1@1+ (1.0,0.0) [0.0|1] ""  Vector__XXX
 SG_ BCM1_DI_Rampe_Innenlicht : 40|1@1+ (1.0,0.0) [0.0|1] ""  Vector__XXX
 SG_ BCM1_DI_Rampe_Leselicht : 41|1@1+ (1.0,0.0) [0.0|1] ""  Vector__XXX
 SG_ BCM1_Innenlicht_H : 42|1@1+ (1.0,0.0) [0.0|1] ""  Vector__XXX
 SG_ BCM1_Innenlicht_V : 43|1@1+ (1.0,0.0) [0.0|1] ""  Vector__XXX
 SG_ BCM1_Leselicht_Anf_hl : 44|1@1+ (1.0,0.0) [0.0|1] ""  Vector__XXX
 SG_ BCM1_Leselicht_Anf_hr : 45|1@1+ (1.0,0.0) [0.0|1] ""  Vector__XXX
 SG_ BCM1_Leselicht_Anf_vl : 46|1@1+ (1.0,0.0) [0.0|1] ""  Vector__XXX
 SG_ BCM1_Leselicht_Anf_vr : 47|1@1+ (1.0,0.0) [0.0|1] ""  Vector__XXX
 SG_ BCM1_Leuchten_Aus : 48|1@1+ (1.0,0.0) [0.0|1] ""  Vector__XXX
 SG_ AMB_Charisma_FahrPr : 49|4@1+ (1.0,0.0) [0.0|15] ""  Vector__XXX
 SG_ AMB_Charisma_Status : 53|2@1+ (1.0,0.0) [0.0|3] ""  Vector__XXX
 SG_ IL_Dimmung_Lautspr : 56|8@1+ (1,0) [0|100] "Unit_PerCent"  Vector__XXX

BO_ 2527679583 IPA_02: 8 Gateway_Max
 SG_ IPA_02_CRC : 0|8@1+ (1,0) [0|255] ""  Vector__XXX
 SG_ IPA_02_BZ : 8|4@1+ (1,0) [0|15] ""  Vector__XXX
 SG_ IPA_PL_Anzeige_links : 12|2@1+ (1.0,0.0) [0.0|3] ""  HUD,Kombi
 SG_ IPA_PL_Anzeige_rechts : 14|2@1+ (1.0,0.0) [0.0|3] ""  HUD,Kombi
 SG_ Parken_Seitenspiegel_Anf : 20|2@1+ (1.0,0.0) [0.0|3] ""  Vector__XXX
 SG_ Parken_ZV_Schliessen : 22|2@1+ (1.0,0.0) [0.0|3] ""  Vector__XXX
 SG_ Parken_aktives_System_02 : 24|5@1+ (1.0,0.0) [0.0|31] ""  Kombi
 SG_ Parken_ZR_Sondermodus_Anf : 29|2@1+ (1.0,0.0) [0.0|3] ""  Vector__XXX
 SG_ Parken_Schluesselsuche_Anf : 31|1@1+ (1.0,0.0) [0.0|1] ""  Vector__XXX
 SG_ Parken_FFB_LED_Anf : 32|2@1+ (1.0,0.0) [0.0|3] ""  Vector__XXX
 SG_ Parken_Wegfahrsperren_Anf : 34|2@1+ (1.0,0.0) [0.0|3] ""  Vector__XXX
 SG_ Parken_Aktivierungslicht_Anf : 36|1@1+ (1.0,0.0) [0.0|1] ""  Vector__XXX
 SG_ Parken_Fahrtrichtungslicht_Anf : 37|2@1+ (1.0,0.0) [0.0|3] ""  Vector__XXX
 SG_ Parken_Lichtnachlauf_Anf : 39|1@1+ (1.0,0.0) [0.0|1] ""  Vector__XXX
 SG_ IPA_Akustik_PL_gefunden : 45|1@1+ (1.0,0.0) [0.0|1] ""  Kombi
 SG_ Parken_Blinker_li_Anf : 46|1@1+ (1.0,0.0) [0.0|1] ""  Vector__XXX
 SG_ Parken_Blinker_re_Anf : 47|1@1+ (1.0,0.0) [0.0|1] ""  Vector__XXX
 SG_ Parken_Fahrerhinweise_Anf : 51|1@1+ (1.0,0.0) [0.0|1] ""  Vector__XXX
 SG_ Parken_Bestaetigungsblinken_Anf : 52|2@1+ (1.0,0.0) [0.0|3] ""  Vector__XXX
 SG_ Parken_Fahrbereitschaftlicht_Anf : 54|1@1+ (1.0,0.0) [0.0|1] ""  Vector__XXX
 SG_ Parken_Lichtsteuerung_Anf : 55|1@1+ (1.0,0.0) [0.0|1] ""  Vector__XXX
 SG_ IPA_Anf_Meldungen : 56|8@1+ (1.0,0.0) [0.0|255] ""  Kombi

BO_ 1841 ISO_ELV_Req: 8 Gateway_Max
 SG_ ISO_ELV_Req_Data : 0|64@1+ (1.0,0.0) [0.0|18446744073709551615] ""  ELV

BO_ 1947 ISO_ELV_Resp: 8 ELV
 SG_ ISO_ELV_Resp_Data : 0|64@1+ (1.0,0.0) [0.0|18446744073709551615] ""  Gateway_Max

BO_ 1792 ISO_Funktionaler_Req_All: 8 Gateway_Max
 SG_ ISO_ALL_01_Req_Data : 0|64@1+ (1.0,0.0) [0.0|18446744073709551615] ""  ELV,HUD,Kombi

BO_ 1819 ISO_HUD_Req: 8 Gateway_Max
 SG_ ISO_HUD_Req_Data : 0|64@1+ (1.0,0.0) [0.0|18446744073709551615] ""  HUD

BO_ 1925 ISO_HUD_Resp: 8 HUD
 SG_ ISO_HUD_Resp_Data : 0|64@1+ (1.0,0.0) [0.0|18446744073709551615] ""  Gateway_Max

BO_ 1812 ISO_Kombi_Req: 8 Gateway_Max
 SG_ ISO_Kombi_Req_Data : 0|64@1+ (1.0,0.0) [0.0|18446744073709551615] ""  Kombi

BO_ 1918 ISO_Kombi_Resp: 8 Kombi
 SG_ ISO_Kombi_Resp_Data : 0|64@1+ (1.0,0.0) [0.0|18446744073709551615] ""  Gateway_Max

BO_ 1836 ISO_MFG_Req: 8 Gateway_Max
 SG_ ISO_MFG_Req_Data : 0|64@1+ (1.0,0.0) [0.0|18446744073709551615] ""  Vector__XXX

BO_ 1942 ISO_MFG_Resp: 8 Vector__XXX
 SG_ ISO_MFG_Resp_Data : 0|64@1+ (1.0,0.0) [0.0|18446744073709551615] ""  Gateway_Max

BO_ 1839 ISO_SFA_Req: 8 Gateway_Max
 SG_ ISO_SFA_Req_Data : 0|64@1+ (1.0,0.0) [0.0|18446744073709551615] ""  Vector__XXX

BO_ 1945 ISO_SFA_Resp: 8 Vector__XXX
 SG_ ISO_SFA_Resp_Data : 0|64@1+ (1.0,0.0) [0.0|18446744073709551615] ""  Gateway_Max

BO_ 1905 ISO_TCO_Req: 8 Gateway_Max
 SG_ ISO_TCO_Req_Data : 0|64@1+ (1.0,0.0) [0.0|18446744073709551615] ""  Vector__XXX

BO_ 2011 ISO_TCO_Resp: 8 Vector__XXX
 SG_ ISO_TCO_Resp_Data : 0|64@1+ (1.0,0.0) [0.0|18446744073709551615] ""  Gateway_Max

BO_ 2549874849 ISOx_Bedienteil_Req: 8 Gateway_Max
 SG_ ISOx_Bedienteil_Req_Data : 0|64@1+ (1.0,0.0) [0.0|18446744073709551615] ""  Vector__XXX

BO_ 2550005921 ISOx_Bedienteil_Resp: 8 Vector__XXX
 SG_ ISOx_Bedienteil_Resp_Data : 0|64@1+ (1.0,0.0) [0.0|18446744073709551615] ""  Gateway_Max

BO_ 2621440049 ISOx_ELV_Req_FD: 64 Gateway_Max
 SG_ ISOx_ELV_Req_FD_Data : 0|512@1+ (1.0,0.0) [0.0|13407807929942597099574024998205846127479365820592393377723561443721764030073546976801874298166903427690031858186486050853753882811946569946433649006084095] ""  ELV

BO_ 2621571121 ISOx_ELV_Resp_FD: 64 ELV
 SG_ ISOx_ELV_Resp_FD_Data : 0|512@1+ (1.0,0.0) [0.0|13407807929942597099574024998205846127479365820592393377723561443721764030073546976801874298166903427690031858186486050853753882811946569946433649006084095] ""  Gateway_Max

BO_ 2621505536 ISOx_Funkt_Req_All_FD: 64 Gateway_Max
 SG_ ISOx_Funkt_Req_All_FD_Data : 0|512@1+ (1.0,0.0) [0.0|13407807929942597099574024998205846127479365820592393377723561443721764030073546976801874298166903427690031858186486050853753882811946569946433649006084095] ""  ELV,HUD,Kombi

BO_ 2621440027 ISOx_HUD_Req_FD: 64 Gateway_Max
 SG_ ISOx_HUD_Req_FD_Data : 0|512@1+ (1.0,0.0) [0.0|13407807929942597099574024998205846127479365820592393377723561443721764030073546976801874298166903427690031858186486050853753882811946569946433649006084095] ""  HUD

BO_ 2621571099 ISOx_HUD_Resp_FD: 64 HUD
 SG_ ISOx_HUD_Resp_FD_Data : 0|512@1+ (1.0,0.0) [0.0|13407807929942597099574024998205846127479365820592393377723561443721764030073546976801874298166903427690031858186486050853753882811946569946433649006084095] ""  Gateway_Max

BO_ 2621440020 ISOx_Kombi_Req_FD: 64 Gateway_Max
 SG_ ISOx_Kombi_Req_FD_Data : 0|512@1+ (1.0,0.0) [0.0|13407807929942597099574024998205846127479365820592393377723561443721764030073546976801874298166903427690031858186486050853753882811946569946433649006084095] ""  Kombi

BO_ 2621571092 ISOx_Kombi_Resp_FD: 64 Kombi
 SG_ ISOx_Kombi_Resp_FD_Data : 0|512@1+ (1.0,0.0) [0.0|13407807929942597099574024998205846127479365820592393377723561443721764030073546976801874298166903427690031858186486050853753882811946569946433649006084095] ""  Gateway_Max

BO_ 2549874852 ISOx_LSH_Req: 8 Gateway_Max
 SG_ ISOx_LSH_Req_Data : 0|64@1+ (1.0,0.0) [0.0|18446744073709551615] ""  Vector__XXX

BO_ 2550005924 ISOx_LSH_Resp: 8 Vector__XXX
 SG_ ISOx_LSH_Resp_Data : 0|64@1+ (1.0,0.0) [0.0|18446744073709551615] ""  Gateway_Max

BO_ 2621440044 ISOx_MFG_Req_FD: 64 Gateway_Max
 SG_ ISOx_MFG_Req_FD_Data : 0|512@1+ (1.0,0.0) [0.0|13407807929942597099574024998205846127479365820592393377723561443721764030073546976801874298166903427690031858186486050853753882811946569946433649006084095] ""  Vector__XXX

BO_ 2621571116 ISOx_MFG_Resp_FD: 64 Vector__XXX
 SG_ ISOx_MFG_Resp_FD_Data : 0|512@1+ (1.0,0.0) [0.0|13407807929942597099574024998205846127479365820592393377723561443721764030073546976801874298166903427690031858186486050853753882811946569946433649006084095] ""  Gateway_Max

BO_ 2621440113 ISOx_TCO_Req_FD: 64 Gateway_Max
 SG_ ISOx_TCO_Req_FD_Data : 0|512@1+ (1.0,0.0) [0.0|13407807929942597099574024998205846127479365820592393377723561443721764030073546976801874298166903427690031858186486050853753882811946569946433649006084095] ""  Vector__XXX

BO_ 2621571185 ISOx_TCO_Resp_FD: 64 Vector__XXX
 SG_ ISOx_TCO_Resp_FD_Data : 0|512@1+ (1.0,0.0) [0.0|13407807929942597099574024998205846127479365820592393377723561443721764030073546976801874298166903427690031858186486050853753882811946569946433649006084095] ""  Gateway_Max

BO_ 2550398990 ISOx_TRE_2_Req: 8 Gateway_Max
 SG_ ISOx_TRE_2_Req_Data : 0|64@1+ (1.0,0.0) [0.0|18446744073709551615] ""  Vector__XXX

BO_ 2550530062 ISOx_TRE_2_Resp: 8 Vector__XXX
 SG_ ISOx_TRE_2_Resp_Data : 0|64@1+ (1.0,0.0) [0.0|18446744073709551615] ""  Gateway_Max

CM_ BO_ 988 "Antrieb, Fahrwerk -> Extended, Infotainment, Komfort";
CM_ BO_ 1002 "ACAN, FCAN --> ICAN";
CM_ BO_ 1003 "Fahrwerk -> Komfort";
CM_ BO_ 884 "Nachricht 2 für Ortung:
Latenz, Geschwindigkeit und Richtung.";
CM_ BO_ 886 "Nachricht 3 für Ortung:
Qualität der Ortung.";
CM_ BO_ 891 "Nachricht 5:
Empfängerstatus und UTC.";
CM_ BO_ 1343 "Nachricht 7:
Ermittlung genaue Geschwindigkeiten EURO/NCAP";
CM_ BO_ 1609 "MLB_Evo ohne KD-Bit";
CM_ BO_ 2527679583 "ehemals ZFAS_01";
CM_ BO_ 2621505536 "VWAG Diagnose funktionaler Request auf CANFD";

CM_ SG_ 988 ACC_18_alt "Veraltet-Bit";
CM_ SG_ 988 ACC_Status_ACC "'ACC OFF' bedeutet ACC-Hauptschalter ist 'Gerastet Aus

'ACC Reversibler Fehler' bedeutet, daß das ACC aktuell einen 
reversiblen Fehler im ACC-SG selbst oder in einem zum 
ACC-System gehörenden SG erkennt.

'ACC irreversibler Fehler' bedeutet, daß ";
CM_ SG_ 988 Bel_DiETa_Mode2 "Statusanzeige FPA-Mode2 in den Direkteinstiegstasten (GTE-Taster im VW380 PHEV)";
CM_ SG_ 988 EPB_Schalterposition "Spiegelt die Schalterstellung wieder.

0x3 = Schalterfehler ";
CM_ SG_ 988 EPB_Status_02 "Erweiterung der Zustände um ein genaueres Bild des aktuellen Zustandes zu erhalten für weitergehende Funktionen ( Stillstandsmanager)
";
CM_ SG_ 988 ESP_50_alt "Veraltet-Bit";
CM_ SG_ 988 ESP_Rollenmodus_Deaktivieren "Zwang zum Abbruch des Rollenmodus mit anschließender ESP-Vollfunktion.
MQB: Zwang zum Abbruch des Rollenmodus in allen Funktionsteilnehmern (Empfänger) mit anschließender ESP-Vollfunktion (Sender).
Signal wird vom ESP dauerhaft mit gültigen Werten bedat";
CM_ SG_ 988 GE_Fahrstufe "Fahrprogramm des Getriebes

Hinweis: Zwischenstellung '0x0' darf nur für Zustandswechsel P/R, R/N, N/D ausgegeben werden, nicht für D/S oder D/Tippgasse wegen Abschaltkriterium GRA/ACC";
CM_ SG_ 988 GE_Freilauf_Status "Freilauf-Status-Signal vom Frailauf-Master an aktive Freilauf-Teilnehmer. In diesem Signal zeigt der Freilauf-Master an, welchen aktuellen Status die Freilauf-Betriebsstrategie hat.";
CM_ SG_ 988 GE_LaunchControl "Während einer LaunchControl-Anfahrt sendet das Getriebesteuergerät das Bit LaunchControl aktiv.
Die Bremse wertet dieses Bit aus, um während einer solchen Anfahrt die Regelgrenzen der Schlupfregelung zu erweitern.
Im Motor Nutzung zur Verbesserung des A";
CM_ SG_ 988 GE_Notlauf "AL/DL: Signalisiert wenn sich das Getriebe (bei DL ein Teilgetriebe) im Notlauf befindet.
VL: Wird gesetzt wenn kein Kraftschluss möglich ist.";
CM_ SG_ 988 GE_Sperr_Info_WFS "WFS-Sperrinformation";
CM_ SG_ 988 GE_Ursache_Fahrstufe_N "Zeigt an, warum Fahrstufe N angenommen wurde. So kann z.B. die Rollsicherung im Verlassenskonzept aktiv bleiben, wenn das Schalten nach N ohne Fahrerwunsch erfolgte (z.B. Fehlerreaktion).

ACHTUNG: Das Signal darf nur ausgewertet werden, wenn GE_Fahrstu";
CM_ SG_ 988 GE_Veto_Rollfaehigkeit "Der Schaltbetätigungsmaster kann mit diesem Signal die Rollfähigkeit bei Zündung aus ('N-Haltephase'/'Waschstraßenfunktion') situationsabhängig verhindern, z.B. bei einem Defekt der P-Taste.";
CM_ SG_ 988 MKE_Stufe "Das Signal bildet die Müdigkeitsstufe im Kombi ab:
0 - deaktiviert
1 - nicht_verfügbar
2 - Stufe_1
3 - Stufe_2
4 - Stufe_3
5 - Stufe_4
6 - reserviert
7 - reserviert";
CM_ SG_ 988 MKE_Texte "Systemhinweis und Sicherheitshinweis für Anzeige im Kombi";
CM_ SG_ 988 MO_Drehzahl_01 "Im Fehlerfall wird die Motordrehzahl über die Nockenwellendrehzahl als Ersatzgrösse ausgegeben

Bei Parallelhybrid: Getriebeeingangsdrehzahl (=E-Maschinen Drehzahl)

Hinweis: 
Ehemaliger Fehlerwert 0xFFFF wird senderseitig nicht unterstützt. 
Diesen";
CM_ SG_ 988 MO_QBit_Drehzahl_01 "AUDI D4: Zykluszeit: 10ms (siehe Zykluszeit schnell/Cycletime Fast)

Achtung:
Reduktion der Zykluszeit Motor_03 auf 10ms geplant.
Projektabhängig soll künftig mit 10ms gesendet werden.
Empfänger die in weiteren Konzern-Projekten eingesetzt werden müs";
CM_ SG_ 988 TSK_06_alt "Veraltet-Bit für die BotschaftTSK_06_alt";
CM_ SG_ 988 TSK_Hauptschalter_GRA_ACC "Stellung des GRA/ACC Hauptschalters. Das Signal wird auch bei Fehlerabschaltungen von GRA/ACC weiterhin bedient und ermöglicht für ACC die Steuerung der ACC-Anzeige auch in Fehlerfällen.";
CM_ SG_ 988 TSK_Limiter_ausgewaehlt "ACC/GRA-Betrieb nur bei nicht ausgewähltem Limiter möglich";
CM_ SG_ 988 TSK_Status "Betriebszustand des TSK-Reglers";

CM_ SG_ 1002 AWV_03_alt "Veraltet-Bit für die Signale:

Botschaft Gateway_77:
AWV_Zielobjekt";
CM_ SG_ 1002 AWV_Verz_Anf "Verzögerungsanforderung der Funktionen Zielbremsung und Teilbremsung an das VZM";
CM_ SG_ 1002 AWV_Verz_Freigabe "Freigabe-Bit der AWV Verzögerung an das VZM";
CM_ SG_ 1002 AWV_Zielobjekttyp "Definiert den Zielobjekttyp an VZM";
CM_ SG_ 1002 Bel_DiETa_Mode "Statusanzeige FPA-Mode in den Direkteinstiegstasten";
CM_ SG_ 1002 EBKV_03_alt "Veraltet Bit";
CM_ SG_ 1002 EBKV_Fahrer_bremst "Fahrer will bremsen (Eintreterkennung).
Wird benötigt, um ACC oder GRA abzuschalten.";
CM_ SG_ 1002 ESP_Bremsdruck "Rohwert des Bremsdrucks
Für Fahrzeuge mit elektrischem Bremskraftverstärker gilt: Aus dem Signal ESP_Bremsdruck lässt sich kein Fahrerbremswunsch ableiten. Das Signal bildet lediglich den hydraulischen Anteil der Fahrzeugverzögerung ab. Der Rohwert des S";
CM_ SG_ 1002 GE_Sumpftemperatur "Getriebesumpftemperatur wird über den Temperatursensor auf der Getriebeplatine ermittelt. Die absolute Sumpftemperatur wird vom Motor empfangen, um entsprechende Kühlleistung für das Getriebe einzustellen.";
CM_ SG_ 1002 MO_Fahrpedalrohwert_01 "AUDI D4: Zykluszeit: 10ms (siehe Zykluszeit schnell/Cycletime Fast)

Stellung des Fahrpedales (Rohwert, ohne Überlagerung durch GRA-Eingriffe etc.)

Die Funktionen zur Berechung des Fahrpedalrohwerts laufen im 10ms Raster. Der Fahrpedalwert berechnet ";
CM_ SG_ 1002 MO_Mom_Ist_Summe "Einheitenloser Wert! Faktor in MO_Faktor_Momente_02 in Motor_Code_01 beachten!

Ist-Moment als Summe aus Verbrennungsmotor und E-Motor (bei Hybrid-Konzepten) incl. allen Eingriffen und Korrekturen

In Fahrzeugen mit einer Antriebsachse bzw. mit mechan";
CM_ SG_ 1002 PaCo_DiETa_LED "Ansteuerung der Funktionsbeleuchtung im Direkteinstiegstaster ('DiETa') durch den Parking Coordinator ('PaCo').

0 LED_Inactive: Die Funktionsbeleuchtung im DiETa_Parken muss leuchten
1 LED_Active: Die Funktionsbeleuchtung im DiETa_Parken darf nicht le";
CM_ SG_ 1002 RTM_Warnstatus "Signalisiert die RTM-Warnstufe.";

CM_ SG_ 1003 AV_Umfeldbeleuchtung_Anf "Anforderung für die Aktivierung einer Umfeldbeleuchtung zur Unterstützung des Umfeldkamerasystems bei Dunkelheit";
CM_ SG_ 1003 EBKV_03_alt "Veraltet Bit";
CM_ SG_ 1003 EBKV_Fahrer_bremst "Fahrer will bremsen (Eintreterkennung).
Wird benötigt, um ACC oder GRA abzuschalten.";
CM_ SG_ 1003 EBKV_QBit_Fahrer_bremst "
";
CM_ SG_ 1003 EFF_Verbrauch_STH "Verbrauchsanteil der Standheizung im Komfortverbrauch (siehe EFF_Verbraucher_Balken)";
CM_ SG_ 1003 EPS_Lastinfo "entspricht Stromaufnahme des Lenkhilfe-SG, Auflösung = 1A";
CM_ SG_ 1003 ESP_50_alt "Veraltet-Bit";
CM_ SG_ 1003 ESP_Bremsdruck "Rohwert des Bremsdrucks
Für Fahrzeuge mit elektrischem Bremskraftverstärker gilt: Aus dem Signal ESP_Bremsdruck lässt sich kein Fahrerbremswunsch ableiten. Das Signal bildet lediglich den hydraulischen Anteil der Fahrzeugverzögerung ab. Der Rohwert des S";
CM_ SG_ 1003 ESP_QBit_Bremsdruck "QBit des Bremsdrucks. Gesetzt bei Ersatzwert, Init oder Fehler.";
CM_ SG_ 1003 LR_HZG_Konfiguration "Konfiguration der Heizmatte der Lenkradheizung";
CM_ SG_ 1003 LR_HZG_Taster_on_off "Anforderung des Schalters am MFL: Lenkradheizung aus/ein
(Regelung der LR_HZG ist im SMLS)";
CM_ SG_ 1003 LR_HZG_Temp_Sensor "Temperaturwert Lenkradheizung";
CM_ SG_ 1003 MFL_Signalhorn "Signalhorn nicht betaetigt/betaetigt";
CM_ SG_ 1003 MO_Fahrpedalrohwert_01 "AUDI D4: Zykluszeit: 10ms (siehe Zykluszeit schnell/Cycletime Fast)

Stellung des Fahrpedales (Rohwert, ohne Überlagerung durch GRA-Eingriffe etc.)

Die Funktionen zur Berechung des Fahrpedalrohwerts laufen im 10ms Raster. Der Fahrpedalwert berechnet ";
CM_ SG_ 1003 MO_QBit_Fahrpedalwerte_01 "AUDI D4: Zykluszeit: 10ms (siehe Zykluszeit schnell/Cycletime Fast)

QBit für beide Fahrpedalwerte des Motors (Fahrpedalrohsignal für ESP, EPB, ACC; Fahrpedalwert für Getriebe)

Achtung:
Reduktion der Zykluszeit Motor_03 auf 10ms geplant.
Projektabh";
CM_ SG_ 1003 MO_temporaere_Fahrerabwesenheit "Das Signal dient zur Signalisierung einer temporären Abwesenheit des Fahrers. In dieser Zeit ist es ihm möglich, sich durch gewisse ¿ im Verlassenskonzept definierte ¿ Fahreraktionen im aktuellen Fahrzyklus zurückzumelden.
Das Signal wird gesetzt, sobald";
CM_ SG_ 1003 PH_Stoermeldung "Meldung einer Störung der PDC an das Kombi";

CM_ SG_ 2583695384 Gateway_AuthTime_Req_Data "AuthTime - Authentische Zeit
ISO-TP Datenkanal - NA2FID
Request Knoten 0x10 Gateway

Gateway an Funktion Authentische Zeit (Request)";

CM_ SG_ 2583826456 Gateway_AuthTime_Resp_Data "AuthTime - Authentische Zeit
ISO-TP Datenkanal - NA2FID
Response Funktion 0x18 AuthTime

Funktion Authentische Zeit an Gateway (Response)";

CM_ SG_ 173 GE_Fahrstufe "Fahrprogramm des Getriebes

Hinweis: Zwischenstellung '0x0' darf nur für Zustandswechsel P/R, R/N, N/D ausgegeben werden, nicht für D/S oder D/Tippgasse wegen Abschaltkriterium GRA/ACC";
CM_ SG_ 173 GE_Ursache_Fahrstufe_N "Zeigt an, warum Fahrstufe N angenommen wurde. So kann z.B. die Rollsicherung im Verlassenskonzept aktiv bleiben, wenn das Schalten nach N ohne Fahrerwunsch erfolgte (z.B. Fehlerreaktion).

ACHTUNG: Das Signal darf nur ausgewertet werden, wenn GE_Fahrstu";
CM_ SG_ 173 Getriebe_11_BZ "Botschaftszähler";
CM_ SG_ 173 Getriebe_11_CRC "Für MLB:
'Berechnung siehe Lastenheft 'Kommunikationsabsicherung für FlexRay und CAN''

Ab MQB und MLBevo:
'Berechnung siehe Lastenheft 'End-to-End Kommunikationsabsicherung''

Endwerte siehe Begleitdokument 'S-PDU Kennungsfolgen'";

CM_ SG_ 884 GNSS_Nachrichtenpaket_ID2 "+1 für jedes neue Paket. Zyklische ID-Vergabe (Zähler). Zur Identifizierung zusammenhängender Nachrichten, die die Daten derselben GNSS-Ortung enthalten und somit zum selben Zyklus gehören. D.h. Daten in den Nachrichten wurden zur selben Zeit erzeugt. Der";
CM_ SG_ 884 GNSS_Ortung_2D_Geschw_ue_Grund "Geschwindigkeit in m pro Sekunde entsprechend dem GNSS-Empfänger";
CM_ SG_ 884 GNSS_Ortung_Ausrichtung "Ausrichtung (Kurswinkel) der GNSS-Messung";
CM_ SG_ 884 GNSS_Ortung_Latenz "Latenz zwischen GNSS-Messung und aktueller Verteilung über CAN-Bus.
Hinweis: Zur Stabilisierung der Latenz soll die GNSS-Zeit für die Bestimmung der CAN-Zyklendauer verwendet werden.";
CM_ SG_ 884 GNSS_Ortung_Noerdliche_Geschw "Geschwindigkeit in m pro Sekunde in Nordrichtung entsprechend dem GNSS-Empfänger";
CM_ SG_ 884 GNSS_Ortung_Oestliche_Geschw "Geschwindigkeit in m pro Sekunde in Ostrichtung entsprechend dem GNSS-Empfänger";
CM_ SG_ 884 GNSS_Ortung_Vertikale_Geschw "Geschwindigkeit  in m pro Sekunde in vertikaler Richtung (aufwärts) entsprechend dem GNSS-Empfänger";

CM_ SG_ 886 GNSS_Nachrichtenpaket_ID3 "+1 für jedes neue Paket. Zyklische ID-Vergabe (Zähler). Zur Identifizierung zusammenhängender Nachrichten, die die Daten derselben GNSS-Ortung enthalten und somit zum selben Zyklus gehören. D.h. Daten in den Nachrichten wurden zur selben Zeit erzeugt. Der";
CM_ SG_ 886 GNSS_Ortung_GDOP "Synthetischer Wert für den Verlust an Präzision der Postions- und Zeitmessung auf Grund der Satellitenkonstellation";
CM_ SG_ 886 GNSS_Ortung_Guete_Ausrichtung "Gesamtgenauigkeit bezüglich der Ausrichtung (Kurswinkel)";
CM_ SG_ 886 GNSS_Ortung_Guete_Geschwindigk "Gesamtgenauigkeit bezüglich Geschwindigkeit am Erdboden";
CM_ SG_ 886 GNSS_Ortung_Guete_horizontal "Gesamtgenauigkeit bezüglich der 2D-Position (horzontal)";
CM_ SG_ 886 GNSS_Ortung_Guete_vertikal "Gesamtgenauigkeit bezüglich der 1D-Position (vertikal)";
CM_ SG_ 886 GNSS_Ortung_HDOP "Synthetischer Wert für den Verlust an Präzision der 2D-Postionsmessung (horizontal) auf Grund der Satellitenkonstellation";
CM_ SG_ 886 GNSS_Ortung_PDOP "Synthetischer Wert für den Verlust an Präzision der Postionsmessung auf Grund der Satellitenkonstellation";
CM_ SG_ 886 GNSS_Ortung_VDOP "Synthetischer Wert für den Verlust an Präzision der 1D-Postionsmessung (vertikal) auf Grund der Satellitenkonstellation";

CM_ SG_ 891 GNSS_Empfaenger_Status "Im 'Backup Mode' wird z.B. die UTC Zeit durch eine gepufferte 'Realtime Clock' bereitgestellt.
Im 'Live Mode' wird die UTC Zeit durch das GNSS Modul bereitgestellt. ";
CM_ SG_ 891 GNSS_Empfangbare_Satelliten "Anzahl der Satelliten, welche bei der aktuellen Satellitenkonfiguration ptentiell verfügbar sind";
CM_ SG_ 891 GNSS_Genutzte_Satelliten "Anzahl der Satelliten, welche für die aktuelle Ortung verwendet werden";
CM_ SG_ 891 GNSS_GLONASS_in_Nutzung "1: das genannte GNSS wurde für die Ortung verwendet";
CM_ SG_ 891 GNSS_GPS_in_Nutzung "1: das genannte GNSS wurde für die Ortung verwendet";
CM_ SG_ 891 GNSS_Nachrichtenpaket_ID5 "+1 für jedes neue Paket. Zyklische ID-Vergabe (Zähler). Zur Identifizierung zusammenhängender Nachrichten, die die Daten derselben GNSS-Ortung enthalten und somit zum selben Zyklus gehören. D.h. Daten in den Nachrichten wurden zur selben Zeit erzeugt. Der";
CM_ SG_ 891 GNSS_Sichtbare_Satelliten "Anzahl der Satelliten, welche aktuell empfangen werden";
CM_ SG_ 891 GNSS_UTC_Zeit "UTC-Zeit, Sekunden seit dem 01.01.1970 00:00";

CM_ SG_ 1343 GNSS_Nachrichtenpaket_ID7 "+1 für jedes neue Paket. Zyklische ID-Vergabe (Zähler). Zur Identifizierung zusammenhängender Nachrichten, die die Daten derselben GNSS-Ortung enthalten und somit zum selben Zyklus gehören. D.h. Daten in den Nachrichten wurden zur selben Zeit erzeugt. Der";
CM_ SG_ 1343 GNSS_V_Daten_Veraltet "Gibt an, ob der Sendezyklus einen neuen Datensatz vom GNSS-Chip enthält. Das heißt, der Datensatz wurde noch nicht in einem Zyklus zuvor verwendet.
Veraltet = Datensatz ist veraltet
Neu = Datensatz ist neu";
CM_ SG_ 1343 GNSS_V_FIX_Typ "Art des 'GNSS-Fix' für die aktuelle Position.";
CM_ SG_ 1343 GNSS_V_Geschw_2D "2D-Geschwindigkeit in m pro Sekunde entsprechend dem GNSS-Empfänger (= 2D-Geschwindigkeit bzgl. WGS-Oberfläche, WGS Geschwindigkeit über Grund)";
CM_ SG_ 1343 GNSS_V_Geschw_2D_Guete95 "Geschätzte Genauigkeit der 2D-Geschwindigkeit vom GNSS-Empfänger
Geforderte Konfidenz = 95%.";
CM_ SG_ 1343 GNSS_V_Geschw_Vertikal "Geschwindigkeit  in m pro Sekunde in vertikaler Richtung (aufwärts, vertikal bzgl. WGS-Oberfläche) entsprechend dem GNSS-Empfänger";
CM_ SG_ 1343 GNSS_V_Geschw_Vertikal_Guete95 "Geschätzte Genauigkeit der vertikalen GNSS-Geschwindigkeit (vertikal bzgl. WGS-Oberfläche). 
Geforderte Konfidenz = 95%.";
CM_ SG_ 1343 GNSS_V_Latenz_vollstaendig "Vollständige Latenz zwischen GNSS-Messung und aktueller Verteilung über CAN-Bus.
Wert = Latenz 1 + Latenz2; 
Latenz1 = interne Chip-Latenz (Zeidbedarf der GNSS-Messung; =Alter des GNSS-Zeitstempels beim Empfang am GNSS-Chip); 
Latenz2 =  Restzeit (Zeit";

CM_ SG_ 299 GRA_Abbrechen "GRA : aus mit speichern
ACC : Soft aus";
CM_ SG_ 299 GRA_ACC_01_BZ "4bit Botschaftszaehler, wird mit jeder Sendebotschaft inkrementiert";
CM_ SG_ 299 GRA_ACC_01_CRC "Für MLB:
'Berechnung siehe Lastenheft 'Kommunikationsabsicherung für FlexRay und CAN''

Ab MQB und MLBevo:
'Berechnung siehe Lastenheft 'End-to-End Kommunikationsabsicherung''

Endwerte siehe Begleitdokument 'S-PDU Kennungsfolgen'";
CM_ SG_ 299 GRA_Codierung "Das Signal zeigt an, ob das Sende-SG (SMLS/MFL) auf GRA- oder ACC-Bedienteil codiert ist:
0: kein GRA- oder ACC Bedienteil
1: GRA-Bedienteil
2: ACC-Bedienteil
3: Limiter_Only-Bedienteil";
CM_ SG_ 299 GRA_Fehler "Das Signal zeigt an, dass das Sende-SG (SMLS/MFG) einen Defekt des GRA-Bedienteils erkannt hat und hierzu ein FSPE abgelegt wurde.";
CM_ SG_ 299 GRA_Hauptschalter "Stellung des GRA/ACC-Hauptschalters: 
Bei gerastetem Hauptschalter:
0: Hauptschalter aus
1: Hauptschalter ein
Bei getastetem Hauptschalter:
0: Taster nicht betätigt
1: Taster betätigt";
CM_ SG_ 299 GRA_LIM_Taste_verfuegbar "Das Signal zeigt an, ob eine Limiter-Umschalttaste am jeweiligen GRA/ACC-Bedienelement vorhanden ist.";
CM_ SG_ 299 GRA_Limiter "Stellung des Limiter-Tasters";
CM_ SG_ 299 GRA_PIT_Limiter "Stellung der Taste PIT-Speed-Limiter";
CM_ SG_ 299 GRA_reserveByte5 "Zweck: Befüllen der reservierten Bitpositionen mit 0 (wg. LIN-Teilnehmer MFL)";
CM_ SG_ 299 GRA_reserveByte6 "Zweck: Befüllen der reservierten Bitpositionen mit 0 (wg. LIN-Teilnehmer MFL)";
CM_ SG_ 299 GRA_reserveByte7 "Zweck: Befüllen der reservierten Bitpositionen mit 0 (wg. LIN-Teilnehmer MFL)";
CM_ SG_ 299 GRA_reserveByte8 "Zweck: Befüllen der reservierten Bitpositionen mit 0 (wg. LIN-Teilnehmer MFL)";
CM_ SG_ 299 GRA_Tip_Hoch "Tippschalter Tip Up / Geschwindigkeit erhöhen";
CM_ SG_ 299 GRA_Tip_Runter "Tippschalter Tip Down / Geschwindigkeit reduzieren";
CM_ SG_ 299 GRA_Tip_Setzen "Tippschalter Set";
CM_ SG_ 299 GRA_Tip_Stufe_2 "Signal zeigt an, dass der zweistufige GRA/ACC-Hebel (8_Positions_Bedienteil) in der 2. Tip-Stufe betätigt wird. Das Signal wird nur gleichzeitig mit dem Signal GRA_Tip_Hoch oder GRA_Tip_Runter gesetzt, wobei die Bits GRA_Tip_Hoch bzw. GRA_Tip_Runter die R";
CM_ SG_ 299 GRA_Tip_Wiederaufnahme "Tippschalter Wiederaufnahme";
CM_ SG_ 299 GRA_TravelAssist "Taste für TravelAssist";
CM_ SG_ 299 GRA_Typ_Bedienteil "Das Signal kennzeichnet die Variante des GRA/ACC-Bedienteils:
0: Init
1: 4-Positionen-Bedienteil (z.B. GRA im Blinkerhebel)
2: 6-Positionen-Bedienteil (GRA/ACC-Bedienteil mit separaten Stellungen für Set/Resume/TipUp/TipDown) 
3: 8-Positionen-Bediente";
CM_ SG_ 299 GRA_Typ_Hauptschalter "Variante des GRA/ACC-Hauptschalters:
0: gerasteter Hauptschalter (bzw. Taster mit Speicherung des Status im SMLS (PAG))
1: getasteter Hauptschalter, keine Speicherung des Status im SMLS";
CM_ SG_ 299 GRA_Verstellung_Zeitluecke "Verstellung der Zeitlücke für ACC

DIST -1 = Zeitluecke um 1 Stufe kleiner
DIST +1 = Zeitluecke um 1 Stufe groeßer
DIST Toggle = Zeitlücke um 1 Stufe kleiner, von kleinster Stufe auf größte Stufe";

CM_ SG_ 1410 HD_Bewegung_auf "Bewegung HD (öffnen)";
CM_ SG_ 1410 HD_Bewegung_zu "Bewegung HD (schließen)";
CM_ SG_ 1410 HD_Endstellung_oben "obere Endstellung HD
";
CM_ SG_ 1410 HD_Endstellung_unten "untere Endstellung HD";
CM_ SG_ 1410 HD_Innentaster_betaetigt "Betätigung Innentaster HD
";
CM_ SG_ 1410 HD_Position "HD Position von 0 bis 100 %";
CM_ SG_ 1410 HD_Rueckmeld_prog "Programmierung Endstellung HD 
";
CM_ SG_ 1410 HD_Taster_defekt "Anzeige ob Heckdeckeltaster defekt ist";
CM_ SG_ 1410 HD_UeKB_erkannt "Erkennung Einklemmschutz";
CM_ SG_ 1410 HD_Verr_Taster_betaetigt_inv "Inverses Bit (Fusi-Anforderung) Betätigung des Verriegelungstaster für Heckdeckel";
CM_ SG_ 1410 HD_Verriegelungstaster_betaetigt "Betätigung des Verriegelungstaster für Heckdeckel";
CM_ SG_ 1410 HD_ZZH_Schalter_S3 "Teilt den Zustand des Statusschalters in einer unidirektionalen ZZH mit.";
CM_ SG_ 1410 HDSG_Anf_Umluftklappe "Signal zur Ansteuerung der Umluftklappe Klima.";

CM_ SG_ 588 ASW_Akustik_Einstellung "Einstellung der Akustik der Funktion ASW.";
CM_ SG_ 588 ASW_Ausgabemodus_BFS "Ansteuerinformationen der ASW Aktoren";
CM_ SG_ 588 ASW_Ausgabemodus_FS "Ansteuerinformationen der ASW Aktoren";
CM_ SG_ 588 ASW_Ausgabemodus_HBFS "Ansteuerinformationen der ASW Aktoren";
CM_ SG_ 588 ASW_Ausgabemodus_HFS "Ansteuerinformationen der ASW Aktoren";
CM_ SG_ 588 ASW_Kombiausgabe "ASW_Kombiausgabe bestimmt, welcher Text im Kombi angezeigt wird. Darüber hinaus werden auch Kombi-Akkustik durch dieses Signal ausgelöst.";
CM_ SG_ 588 ASW_Kombitexte "ASW_Kombitexte bestimmt welcher Text im Kombi angezeigt wird. Darüber hinaus werden auch Kombi-Akkustik durch dieses Signal ausgelöst.

Dieses Signal ersetzt SWA_Anzeigen für den ASW-Anteil. Der SWA-Anteil des alten Signals findet sich in SWA-Kombitexte";
CM_ SG_ 588 ASW_Modus "gibt die Verfügbarkeit der ASW Modus an";
CM_ SG_ 588 ASW_Status "Funktionsstatus Ausstiegswarnung (ASW)";
CM_ SG_ 588 ASW_Ton_Richtung_HL "ASW-Warntonausgabe hinten links";
CM_ SG_ 588 ASW_Ton_Richtung_HR "ASW_Warntonausgabe hinten rechts";
CM_ SG_ 588 ASW_Ton_Richtung_VL "ASW-Warntonausgabe vorne links";
CM_ SG_ 588 ASW_Ton_Richtung_VR "ASW-Warntonausgabe vorne rechts";
CM_ SG_ 588 ASW_Warnung_BFS "Modus Beifahrerseite der Funktion Ausstiegswarnung (ASW)";
CM_ SG_ 588 ASW_Warnung_FS "Modus Beifahrerseite der Funktion Ausstiegswarnung (ASW)";
CM_ SG_ 588 Heckradar_Kombitexte "Heckradar_Kombitexte bestimmt welcher Text im Kombi angezeigt wird. Darüber hinaus werden auch Kombi-Akkustik durch dieses Signal ausgelöst.

Dieses Signal ersetzt SWA_Anzeigen und deckt alle Kombinationsmöglichkeiten der Heckradarfunktionen ab. Die Fun";
CM_ SG_ 588 HRE_Anzeigetexte "HRE-Texte und -Akustik zur Anzeige im Kombiinstrument";
CM_ SG_ 588 RCTA_Kombitexte "RCTA_Kombitexte bestimmt welcher Text im Kombi angezeigt wird. Darüber hinaus werden auch Kombi-Akkustik durch dieses Signal ausgelöst.";
CM_ SG_ 588 SWA_Anzeigen "SWA- Texte und -Akustik zur Anzeige im Kombiinstrument
0x7-0xF = reserviert";
CM_ SG_ 588 SWA_Blindheit_erkannt "SWA erkennt selbständig eigene Blindheit durch äußere Einflüsse.";
CM_ SG_ 588 SWA_Blindheitsverdacht "Signalwert wird auf Blindheitsverdacht_erkannt gesetzt, wenn ein im Datensatz parametrierbarer Schwellwert überschritten wurde.
Das Signal dient als Vorstufe zur SWA Blindheit und schaltet nicht die SWA Funktion ab.";
CM_ SG_ 588 SWA_Brightness_Mode_FPM "Actual mode for brightness settings of function Spurwechselassistent";
CM_ SG_ 588 SWA_FT_RueckLED "SWA/ASW Rückmelde-LED. Zeigt den Aktivierungszustand der Funktionen SWA/ASW";
CM_ SG_ 588 SWA_Gischtzaehler "Zähler, der die eigene Gischt bei nasser Fahrbahn misst (Kennwert)";
CM_ SG_ 588 SWA_Infostufe_Assist_li "Aktion der SWA-Funktion auf der entsprechenden Fahrzeugseite";
CM_ SG_ 588 SWA_Infostufe_Assist_re "Aktion der SWA-Funktion auf der entsprechenden Fahrzeugseite";
CM_ SG_ 588 SWA_Kombiausgabe "SWA_Kombiausgabe bestimmt, welcher Text im Kombi angezeigt wird.";
CM_ SG_ 588 SWA_Kombiwarnung "SWA_Kombiwarnung löst (akustische) Warnungen an den Fahrer aus";
CM_ SG_ 588 SWA_LED_Ausgabemodus_BFS "Ansteuerung SWA LED Beifahrerseite";
CM_ SG_ 588 SWA_LED_Ausgabemodus_FS "Ansteuerung SWA LED Fahrerseite";
CM_ SG_ 588 SWA_LED_Hell_BFS "Helligkeitswert SWA LED Beifahrerseite";
CM_ SG_ 588 SWA_LED_Hell_FS "Helligkeitswert SWA LED Fahrerseite";
CM_ SG_ 588 SWA_Modus "gibt die Verfügbarkeit der SWA Modus an";
CM_ SG_ 588 SWA_Modus_System "Gibt Zusatzinformationen zum SWA System Status an";
CM_ SG_ 588 SWA_rel_Fehler "Hinweis: In Zukunft das Signal SWA_Modus anstatt SWA_rel_Fehler verwenden!

SWA erkennt einen Fehler, die Objektdetektion betreffend, mit FSP-Eintrag.";
CM_ SG_ 588 SWA_rel_Nichtverf "Hinweis: In Zukunft das Signal SWA_Modus anstatt SWA_rel_Nichtverf verwenden!

SWA erkennt eine Nichtverfuegbarkeit, die Objektdetektion betreffend, ohne FSP-Eintrag";
CM_ SG_ 588 SWA_Sta_aktiv "SWA Status aktiv; Lampenansteuerung im Kombi";
CM_ SG_ 588 SWA_Sta_passiv "Hinweis: In Zukunft das Signal SWA_Status anstatt SWA_Sta_passiv verwenden!

SWA Status passiv; Lampenansteuerung im Kombi";
CM_ SG_ 588 SWA_Standziele_li "Hinweis: In Zukunft das Signal SWA_StrukturLinks_querAbstand anstatt SWA_Standziele_li verwenden!

Abstand zwischen Fahrzeug und Standziele links geringer als ein applizierbarer Wert.";
CM_ SG_ 588 SWA_Standziele_re "Hinweis: In Zukunft das Signal SWA_StrukturRechts_querAbstand anstatt SWA_Standziele_re verwenden!

Abstand zwischen Fahrzeug und Standziele links geringer als ein applizierbarer Wert.";
CM_ SG_ 588 SWA_Status "gibt die Verfügbarkeit der SWA_Status an";
CM_ SG_ 588 SWA_Status_KuFu "Gibt den Status der Kundenfunktion SWA an";
CM_ SG_ 588 SWA_Status_System "Gibt den Status des Systems SWA an";
CM_ SG_ 588 SWA_Warnstufe_Assist_li "Aktion der SWA-Funktion auf der entsprechenden Fahrzeugseite";
CM_ SG_ 588 SWA_Warnstufe_Assist_re "Aktion der SWA-Funktion auf der entsprechenden Fahrzeugseite";

CM_ SG_ 589 SWA_Infostufe_SWA_li "Aktion der SWA-Funktion auf der entsprechenden Fahrzeugseite";
CM_ SG_ 589 SWA_Infostufe_SWA_re "Aktion der SWA-Funktion auf der entsprechenden Fahrzeugseite";
CM_ SG_ 589 SWA_Kolonne_li "Info, dass auf der entspr. Spur mehr als zwei Fahrzeuge zu finden sind. ";
CM_ SG_ 589 SWA_Kolonne_mi "Info, dass auf der entspr. Spur mehr als zwei Fahrzeuge zu finden sind. ";
CM_ SG_ 589 SWA_Kolonne_re "Info, dass auf der entspr. Spur mehr als zwei Fahrzeuge zu finden sind. ";
CM_ SG_ 589 SWA_Obj_01_Breite "Breite des Objektes in Metern";
CM_ SG_ 589 SWA_Obj_01_Existenzwahrsch "Existenzwahrscheinlichkeit des Objektes in Prozent";
CM_ SG_ 589 SWA_Obj_01_Gemessen "Status Objekt gemessen/getrackt";
CM_ SG_ 589 SWA_Obj_01_GeschwRelX "Relative Geschwindigkeit in x (m/s)
Geschwindigkeiten beziehen sich immer auf den Objektmittelpunkt
Messung in Radialrichtung";
CM_ SG_ 589 SWA_Obj_01_GeschwRelY "Relative Geschwindigkeit in y (m/s)
Geschwindigkeiten beziehen sich immer auf den Objektmittelpunkt";
CM_ SG_ 589 SWA_Obj_01_ID "ID des Objektes";
CM_ SG_ 589 SWA_Obj_01_Laenge "Länge des Objektes in Metern";
CM_ SG_ 589 SWA_Obj_01_Objektklasse "Gibt die Objektklasse an.
Unbekannt: dynamisches oder statisches Objekt; alle nicht zu klassifizierenden nicht über- oder unterfahrbaren Objekte, wie Spielzeug (z.B. Trettraktor) oder Sonderfahrzeuge (u.a. Trike, Quad, Straßenbahn, Rikschas, Kutschen)
D";
CM_ SG_ 589 SWA_Obj_01_PositionX "Position des Objektes in x-Richtung (Referenzpunkt der 3D-Objektbox)";
CM_ SG_ 589 SWA_Obj_01_PositionY "Position des Objektes in y-Richtung (Referenzpunkt der 3D-Objektbox)";
CM_ SG_ 589 SWA_Obj_01_ReferenzPkt "Der Bezugspunkt eines detektierten Objektes zeigt den kürzesten direkten Abstand zur Mitte der EGO-Vorderkante";
CM_ SG_ 589 SWA_Obj_02_Breite "Breite des Objektes in Metern";
CM_ SG_ 589 SWA_Obj_02_Existenzwahrsch "Existenzwahrscheinlichkeit des Objektes in Prozent";
CM_ SG_ 589 SWA_Obj_02_Gemessen "Status der PositionY des Objektes 
0 - ObjektpositionY_geschaetzt (Kalibrierung nicht abgeschlossen, hohe Entfernung, etc.)
1 - ObjektpositionY_bestaetigt (Messung hinreichend genau)";
CM_ SG_ 589 SWA_Obj_02_GeschwRelX "Relative Geschwindigkeit in x (m/s)
Geschwindigkeiten beziehen sich immer auf den Objektmittelpunkt
Messung in Radialrichtung";
CM_ SG_ 589 SWA_Obj_02_GeschwRelY "Relative Geschwindigkeit in y (m/s)
Geschwindigkeiten beziehen sich immer auf den Objektmittelpunkt";
CM_ SG_ 589 SWA_Obj_02_ID "ID des Objektes";
CM_ SG_ 589 SWA_Obj_02_Laenge "Länge des Objektes in Metern";
CM_ SG_ 589 SWA_Obj_02_Objektklasse "Gibt die Objektklasse an.
Unbekannt: dynamisches oder statisches Objekt; alle nicht zu klassifizierenden nicht über- oder unterfahrbaren Objekte, wie Spielzeug (z.B. Trettraktor) oder Sonderfahrzeuge (u.a. Trike, Quad, Straßenbahn, Rikschas, Kutschen)
D";
CM_ SG_ 589 SWA_Obj_02_PositionX "Position des Objektes in x-Richtung (Referenzpunkt der 3D-Objektbox)";
CM_ SG_ 589 SWA_Obj_02_PositionY "Position des Objektes in y-Richtung (Referenzpunkt der 3D-Objektbox)";
CM_ SG_ 589 SWA_Obj_02_ReferenzPkt "Der Bezugspunkt eines detektierten Objektes zeigt den kürzesten direkten Abstand zur Mitte der EGO-Vorderkante";
CM_ SG_ 589 SWA_Obj_03_Breite "Breite des Objektes in Metern";
CM_ SG_ 589 SWA_Obj_03_Existenzwahrsch "Existenzwahrscheinlichkeit des Objektes in Prozent";
CM_ SG_ 589 SWA_Obj_03_Gemessen "Status der PositionY des Objektes 
0 - ObjektpositionY_geschaetzt (Kalibrierung nicht abgeschlossen, hohe Entfernung, etc.)
1 - ObjektpositionY_bestaetigt (Messung hinreichend genau)";
CM_ SG_ 589 SWA_Obj_03_GeschwRelX "Relative Geschwindigkeit in x (m/s)
Geschwindigkeiten beziehen sich immer auf den Objektmittelpunkt
Messung in Radialrichtung";
CM_ SG_ 589 SWA_Obj_03_GeschwRelY "Relative Geschwindigkeit in y (m/s)
Geschwindigkeiten beziehen sich immer auf den Objektmittelpunkt";
CM_ SG_ 589 SWA_Obj_03_ID "ID des Objektes";
CM_ SG_ 589 SWA_Obj_03_Laenge "Länge des Objektes in Metern";
CM_ SG_ 589 SWA_Obj_03_Objektklasse "Gibt die Objektklasse an.
Unbekannt: dynamisches oder statisches Objekt; alle nicht zu klassifizierenden nicht über- oder unterfahrbaren Objekte, wie Spielzeug (z.B. Trettraktor) oder Sonderfahrzeuge (u.a. Trike, Quad, Straßenbahn, Rikschas, Kutschen)
D";
CM_ SG_ 589 SWA_Obj_03_PositionX "Position des Objektes in x-Richtung (Referenzpunkt der 3D-Objektbox)";
CM_ SG_ 589 SWA_Obj_03_PositionY "Position des Objektes in y-Richtung (Referenzpunkt der 3D-Objektbox)";
CM_ SG_ 589 SWA_Obj_03_ReferenzPkt "Der Bezugspunkt eines detektierten Objektes zeigt den kürzesten direkten Abstand zur Mitte der EGO-Vorderkante";
CM_ SG_ 589 SWA_Obj_04_Breite "Breite des Objektes in Metern";
CM_ SG_ 589 SWA_Obj_04_Existenzwahrsch "Existenzwahrscheinlichkeit des Objektes in Prozent";
CM_ SG_ 589 SWA_Obj_04_Gemessen "Status der PositionY des Objektes 
0 - ObjektpositionY_geschaetzt (Kalibrierung nicht abgeschlossen, hohe Entfernung, etc.)
1 - ObjektpositionY_bestaetigt (Messung hinreichend genau)";
CM_ SG_ 589 SWA_Obj_04_GeschwRelX "Relative Geschwindigkeit in x (m/s)
Geschwindigkeiten beziehen sich immer auf den Objektmittelpunkt
Messung in Radialrichtung";
CM_ SG_ 589 SWA_Obj_04_GeschwRelY "Relative Geschwindigkeit in y (m/s)
Geschwindigkeiten beziehen sich immer auf den Objektmittelpunkt";
CM_ SG_ 589 SWA_Obj_04_ID "ID des Objektes";
CM_ SG_ 589 SWA_Obj_04_Laenge "Länge des Objektes in Metern";
CM_ SG_ 589 SWA_Obj_04_Objektklasse "Gibt die Objektklasse an.
Unbekannt: dynamisches oder statisches Objekt; alle nicht zu klassifizierenden nicht über- oder unterfahrbaren Objekte, wie Spielzeug (z.B. Trettraktor) oder Sonderfahrzeuge (u.a. Trike, Quad, Straßenbahn, Rikschas, Kutschen)
D";
CM_ SG_ 589 SWA_Obj_04_PositionX "Position des Objektes in x-Richtung (Referenzpunkt der 3D-Objektbox)";
CM_ SG_ 589 SWA_Obj_04_PositionY "Position des Objektes in y-Richtung (Referenzpunkt der 3D-Objektbox)";
CM_ SG_ 589 SWA_Obj_04_ReferenzPkt "Der Bezugspunkt eines detektierten Objektes zeigt den kürzesten direkten Abstand zur Mitte der EGO-Vorderkante";
CM_ SG_ 589 SWA_Obj_05_Breite "Breite des Objektes in Metern";
CM_ SG_ 589 SWA_Obj_05_Existenzwahrsch "Existenzwahrscheinlichkeit des Objektes in Prozent";
CM_ SG_ 589 SWA_Obj_05_Gemessen "Status der PositionY des Objektes 
0 - ObjektpositionY_geschaetzt (Kalibrierung nicht abgeschlossen, hohe Entfernung, etc.)
1 - ObjektpositionY_bestaetigt (Messung hinreichend genau)";
CM_ SG_ 589 SWA_Obj_05_GeschwRelX "Relative Geschwindigkeit in x (m/s)
Geschwindigkeiten beziehen sich immer auf den Objektmittelpunkt
Messung in Radialrichtung";
CM_ SG_ 589 SWA_Obj_05_GeschwRelY "Relative Geschwindigkeit in y (m/s)
Geschwindigkeiten beziehen sich immer auf den Objektmittelpunkt";
CM_ SG_ 589 SWA_Obj_05_ID "ID des Objektes";
CM_ SG_ 589 SWA_Obj_05_Laenge "Länge des Objektes in Metern";
CM_ SG_ 589 SWA_Obj_05_Objektklasse "Gibt die Objektklasse an.
Unbekannt: dynamisches oder statisches Objekt; alle nicht zu klassifizierenden nicht über- oder unterfahrbaren Objekte, wie Spielzeug (z.B. Trettraktor) oder Sonderfahrzeuge (u.a. Trike, Quad, Straßenbahn, Rikschas, Kutschen)
D";
CM_ SG_ 589 SWA_Obj_05_PositionX "Position des Objektes in x-Richtung (Referenzpunkt der 3D-Objektbox)";
CM_ SG_ 589 SWA_Obj_05_PositionY "Position des Objektes in y-Richtung (Referenzpunkt der 3D-Objektbox)";
CM_ SG_ 589 SWA_Obj_05_ReferenzPkt "Der Bezugspunkt eines detektierten Objektes zeigt den kürzesten direkten Abstand zur Mitte der EGO-Vorderkante";
CM_ SG_ 589 SWA_Obj_06_Breite "Breite des Objektes in Metern";
CM_ SG_ 589 SWA_Obj_06_Existenzwahrsch "Existenzwahrscheinlichkeit des Objektes in Prozent";
CM_ SG_ 589 SWA_Obj_06_Gemessen "Status der PositionY des Objektes 
0 - ObjektpositionY_geschaetzt (Kalibrierung nicht abgeschlossen, hohe Entfernung, etc.)
1 - ObjektpositionY_bestaetigt (Messung hinreichend genau)";
CM_ SG_ 589 SWA_Obj_06_GeschwRelX "Relative Geschwindigkeit in x (m/s)
Geschwindigkeiten beziehen sich immer auf den Objektmittelpunkt
Messung in Radialrichtung";
CM_ SG_ 589 SWA_Obj_06_GeschwRelY "Relative Geschwindigkeit in y (m/s)
Geschwindigkeiten beziehen sich immer auf den Objektmittelpunkt";
CM_ SG_ 589 SWA_Obj_06_ID "ID des Objektes";
CM_ SG_ 589 SWA_Obj_06_Laenge "Länge des Objektes in Metern";
CM_ SG_ 589 SWA_Obj_06_Objektklasse "Gibt die Objektklasse an.
Unbekannt: dynamisches oder statisches Objekt; alle nicht zu klassifizierenden nicht über- oder unterfahrbaren Objekte, wie Spielzeug (z.B. Trettraktor) oder Sonderfahrzeuge (u.a. Trike, Quad, Straßenbahn, Rikschas, Kutschen)
D";
CM_ SG_ 589 SWA_Obj_06_PositionX "Position des Objektes in x-Richtung (Referenzpunkt der 3D-Objektbox)";
CM_ SG_ 589 SWA_Obj_06_PositionY "Position des Objektes in y-Richtung (Referenzpunkt der 3D-Objektbox)";
CM_ SG_ 589 SWA_Obj_06_ReferenzPkt "Der Bezugspunkt eines detektierten Objektes zeigt den kürzesten direkten Abstand zur Mitte der EGO-Vorderkante";
CM_ SG_ 589 SWA_Obj_Kurvenradius "Kurvenradius ermittelt aus dem zurückgelegten Streckenverlauf in Metern. Die aktuelle Berechnungsgrundlage für die kurvenbereinigte PositionY der ausgegebenen Objekte.";
CM_ SG_ 589 SWA_StrukturLinks_querAbstand "Abstand zur Randbebauung auf der entsprechenden Fahrzeugseite bezogen auf die Mitte der Hinterachse von dem Ego-Fahrzeug.";
CM_ SG_ 589 SWA_StrukturLinks_Typ "Typ der vom Heckradar erkannten Randbebauung";
CM_ SG_ 589 SWA_StrukturRechts_querAbstand "Abstand zur Randbebauung auf der entsprechenden Fahrzeugseite bezogen auf die Mitte der Hinterachse von dem Ego-Fahrzeug.";
CM_ SG_ 589 SWA_StrukturRechts_Typ "Typ der vom Heckradar erkannten Randbebauung";
CM_ SG_ 589 SWA_Umfeld_Zeitstempel "Das Signal beschreibt den Messzeitpunkt zu dem die Messdaten erfasst worden sind in Sekunden.";
CM_ SG_ 589 SWA_Umfeld_Zeitstempel_Status "Das Signal beschreibt die Art der Zeitsynchonisierung und ggf. die Fehlerursache bei fehlender Zeitstempelausgabe.";
CM_ SG_ 589 SWA_Warnung_SWA_li "Aktion der SWA-Funktion auf der entsprechenden Fahrzeugseite";
CM_ SG_ 589 SWA_Warnung_SWA_re "Aktion der SWA-Funktion auf der entsprechenden Fahrzeugseite";

CM_ SG_ 2331595854 HR_IFA_Geschw_Faktor_li "Geschwindigkeitsfaktor des kritischen Objekts auf der entsprechenden Fahrzeugseite";
CM_ SG_ 2331595854 HR_IFA_Geschw_Faktor_re "Geschwindigkeitsfaktor des kritischen Objekts auf der entsprechenden Fahrzeugseite";
CM_ SG_ 2331595854 HR_IFA_Modus_li "Aktion auf der entsprechenden Fahrzeugseite";
CM_ SG_ 2331595854 HR_IFA_Modus_re "Aktion auf der entsprechenden Fahrzeugseite";

CM_ SG_ 1609 HUD_Aktiv "Zeigt an ob das HUD eingeschaltet und anzeigebereit oder ausgeschaltet ist. ";
CM_ SG_ 1609 HUD_Anzeigefehler_NV "Nightvisionbild kann im HUD aufgrund eines Fehlers nicht angezeigt werden";
CM_ SG_ 1609 HUD_FAS_Anzeige_Kombi "Zeigt an ob die FAS Inhalte im Kombi oder im HUD angezeigt werden sollen.";
CM_ SG_ 1609 HUD_KDK_Anzeige_Kombi "Zeigt an ob die KDK im Kombi oder im HUD angezeigt werden sollen.";
CM_ SG_ 1609 HUD_MFL_RQ "Anfrage des MFL Fokus an das Kombiinstrument vom HUD.";
CM_ SG_ 1609 HUD_NV_in_Anzeige "Rueckmeldung,ob NV-Inhalte im HUD angezeigt werden.";
CM_ SG_ 1609 HUD_PEA_Anzeige_Kombi "Zeigt an ob die PEA Inhalte im Kombi oder im HUD angezeigt werden sollen.";
CM_ SG_ 1609 HUD_VZE_AIO_Anzeige_Kombi "Zeigt an ob die VZE und AIO Inhalte im Kombi oder im HUD angezeigt werden sollen.";
CM_ SG_ 1609 HUD_VZE_in_Anzeige "Rückmeldung,ob VZE-Inhalte im HUD angezeigt werden.";

CM_ SG_ 1452 HVEM_Energie_Klima_Vorgabe "HVEM-Energievorgabe für Klima-Vorkonditionierung";
CM_ SG_ 1452 HVEM_Energie_Klima_Vorgabe_HighR "Erweiterte Auflösung von 10Wh für Signal HVEM_Energie_Klima_Vorgabe.
Signalwert wird zu HVEM_Energie_Klima_Vorgabe Addiert";
CM_ SG_ 1452 HVEM_HV_Anf "HV Anforderung des HV Energiemanagements an das MSG";
CM_ SG_ 1452 HVEM_HVK_Aktivitaet "Dem HVEM sind HV-Komponenten zugeordnet.  Das HVEM übermittelt an den HVK ein 
Hochvolt –Aktivitätsstatus dieser HV-Komponenten.";
CM_ SG_ 1452 HVEM_IstLeistungNA "aktuelle Leistungsaufnahme der Nebenaggregate";
CM_ SG_ 1452 HVEM_IstStrom_HVVerbraucher "Iststromaufnahme der elektrischen Nebenaggregate aus dem HV Zwischenkreis";
CM_ SG_ 1452 HVEM_Leistung_Klima_Vorgabe "Leistungsvorgabe Thermo (für Kühlen und Heizen)";
CM_ SG_ 1452 HVEM_MO_MaxLeistungIgnoriert "Rueckmeldung des HVEM ob die vorgegebene MaxLeistung vom MSG eingehalten wird.";
CM_ SG_ 1452 HVEM_Nutzbare_Energie "Nutzbare Energie welche für Komfortfunktionen vom HVEM freigegeben wird.";
CM_ SG_ 1452 HVEM_NVEM_Leistungsvorgabe "Leistungsvorgabe des HVEM an das NVEM";
CM_ SG_ 1452 HVEM_Pruefpuls_Anf "Prüfpulsanforderung an den HV-Koordinator";

CM_ SG_ 1283 HV_Bordnetz_aktiv "Signalisiert ein aktives Hochvoltbordnetz. Für die Belastbarkeit des HV-Netzes müssen Strom- bzw. Leistungsgrenzen eingehalten werden";
CM_ SG_ 1283 HV_Bordnetz_Fehler "Status ob im  HV-Netz ein Fehler detektiert wurde.";
CM_ SG_ 1283 HVK_01_CRC "Für MLB:
'Berechnung siehe Lastenheft 'Kommunikationsabsicherung für FlexRay und CAN''

Ab MQB und MLBevo:
'Berechnung siehe Lastenheft 'End-to-End Kommunikationsabsicherung''

Endwerte siehe Begleitdokument 'S-PDU Kennungsfolgen'";
CM_ SG_ 1283 HVK_AktiveEntladung_Anf "Anforderung zum aktiven Entladen des HV-Netzes, während der Abschaltung des HV-Netz.";
CM_ SG_ 1283 HVK_BMS_Sollmodus "Angeforderter Sollmodus der HV-Batterie:
0 : HV_Off                                
1 : HV_On (HS geschlossen)                
2 : nicht belegbar                        
3 : AC-Laden_erw (HS +AC_2-Schütze geschlossen)                         
4 : AC-";
CM_ SG_ 1283 HVK_DCDC_Sollmodus "angeforderte Soll-Betriebsart des DC/DC-Wandlers: 
0: Standby; Kommunikation aktiv
1: Zwischenkreis des HV-Netzes wird vorgeladen; HV-Netz wird aktiviert und darf nicht  
    belastet werden.
2: Tiefsetzen (HV --> BN 14,4V)
    Sollwertvorgabe projek";
CM_ SG_ 1283 HVK_EKK_Sollmodus "Sollmodus elektrischer Klimakompressor";
CM_ SG_ 1283 HVK_Gesamtst_Spgfreiheit "Status des HV-Systems";
CM_ SG_ 1283 HVK_HV_Netz_Warnungen "Anforderung Warnung/Fehler HV-System im Kombi
0: Keine Warnung/Init
1:Anforderung_Anzeige_Warnung_HV-Netz (gelbes Symbol)
2:Anforderung_Anzeige_Fehler_HV-Netz (rotes Symbol)
3:Anforderung_Anzeige_Warnung_Kein_Wiederstart_möglich";
CM_ SG_ 1283 HVK_HVEM_Freigabe "Der HVK gibt das HVEM frei, um das HV-Netz unter Einhaltung von Leistungsgrenzen in Anspruch zu nehmen.";
CM_ SG_ 1283 HVK_HVLM_Sollmodus "Angeforderter Sollmodus des Lademanagers.";
CM_ SG_ 1283 HVK_HVPTC_Sollmodus "Sollmodus HV-PTC
0 : keine Freigabe
1 : Freigabe
2 : Freigabe_ausgesetzt
3 : nicht belegbar
4 : nicht belegbar
5 : nicht belegbar
6 : nicht belegbar
7 : Init   (CAN-Initialisierung)   

Info: 'nicht belegbar' d.h. Sollmodus nicht relevant für HV";
CM_ SG_ 1283 HVK_Iso_Messung_Start "Anforderung an die isolationswiderstandsüberwachenden HV-Komponenten zur Durchführung der Isolations-Widerstandsmessung.";
CM_ SG_ 1283 HVK_Istmodus_Anf "HVK-Anforderung an alle HV-Komponenten deren Istmodus im schnellen Zyklus (Inhibitzeit) zu senden.";
CM_ SG_ 1283 HVK_Ladebereit "Information an das Lademanagement, dass das HV-System aus Sicht des HVKs bereitgestellt werden kann.";
CM_ SG_ 1283 HVK_Notabschaltung_Anf "Aufforderung zur schnellstmöglichen Abschaltung des HV-Netzes aufgrund HV-Sicherheit";
CM_ SG_ 1283 HVK_PPulsFreigabe "Prüfpuls-Freigabe seitens Hochvoltkoordinator";
CM_ SG_ 1283 HVK_TN1_Sollmodus "Angeforderter Sollmodus der Steuereinheit für das Schütze des Teilnetz1 'Ladepfad':
0 : HV_Off                                
1 : HV_On (Schütz geschlossen)                
2 : reserviert
3 : Init   (CAN-Initialisierung)";
CM_ SG_ 1283 HVK_Vorladung_aktiv "Systeminformation, dass aktiv vorgeladen wird";

CM_ SG_ 1428 HVLM_Anzeigetexte "Anzeige einer offenen Ladedosenklappe";
CM_ SG_ 1428 HVLM_Bat_Konditionierung_Anf "Anforderung HV-Netz für Batteriekonditionierung (Motorsteuergerät aktiviert HV-Netz).";
CM_ SG_ 1428 HVLM_Bat_laden_aktiv "Anzeige ob die HV-Batterie geladen wird.";
CM_ SG_ 1428 HVLM_Fehler_Ladestecker "Fehler am Ladestecker erkannt";
CM_ SG_ 1428 HVLM_Fehler_Verriegelung "Fehler bei der Steckerverriegelung erkannt";
CM_ SG_ 1428 HVLM_FSH_Anf "Frontscheibenheizung anfordern";
CM_ SG_ 1428 HVLM_HSH_Anf "Heckscheibenheizung anfordern";
CM_ SG_ 1428 HVLM_HV_Anf "HV-Aktivierung Anforderung und Grund der Anforderung";
CM_ SG_ 1428 HVLM_HVEM_MaxLeistung "Maximal zulässige Leistung, die das HVEM vom Lader nutzen darf. Wenn das Fzg nicht über einen Lader mit dem AC Netz verbunden ist ist dieser Wert 0.";
CM_ SG_ 1428 HVLM_Klima_Temp "MLBevo: Gewünschte Innenraumtemperatur, auf die bei der Standklimatisierung geregelt werden soll.
MQB: Temperatur die vom Nutzer vorgewählt wurde (VW: low=15,5 °C/ high=30,0°C)";
CM_ SG_ 1428 HVLM_Ladeart "Anzeige, ob Strom in das Fzg. fließt und wofür er verwendet wird.";
CM_ SG_ 1428 HVLM_Lademodus_HV_Bat "Gibt den aktuell eingestellten Lademodus an.";
CM_ SG_ 1428 HVLM_Ladesystemhinweise "Anzeigen von Hinweisen zum Ladesystem.
Anzeigen, dass das Ladesystem defekt ist.";
CM_ SG_ 1428 HVLM_Langzeit_Laden "Anforderung den Ladezustand der HV-Batterie bis langen Standzeiten zu reduzieren";
CM_ SG_ 1428 HVLM_Restladezeit_HV_Bat_02 "Zeit, bis HV-Batterie vollständig geladen ist. Angabe in 5 Minuten Schritten. Maximum 42h 25Min";
CM_ SG_ 1428 HVLM_Standklima_Timer_Status "Signalisierung an das KBT ob mind. ein Timer zur Standklimatisierung programmiert ist";
CM_ SG_ 1428 HVLM_Status_Netz "Information, ob das Fahrzeug mit einem Stromnetz verbunden ist.";
CM_ SG_ 1428 HVLM_Stecker_Status "Status der Steckererkennung unabhängig vom Lademodus (AC oder DC)";
CM_ SG_ 1428 HVLM_VK_Anf "Anforderung des Konditionierungsmanagers (im Lademanager) zur Aktivierung der Vorkonditionierung Innenraum";
CM_ SG_ 1428 HVLM_VK_Modus "Übermittlung des aktuellen Konditionierungs-Status für HMI, Mobile Online Dienste";
CM_ SG_ 1428 HVLM_VK_STH_Einsatz "Auswahl der PHEV Standheizung";
CM_ SG_ 1428 HVLM_Warnmeldungen "Dieses Signal übermittelt Kundeninformationen vom HV-Laden zur Kombianzeige";

CM_ SG_ 27 WFS_IMMO_ELV_RND "WFS_IMMO_ELV_RND";

CM_ SG_ 2583720728 Info_El_AuthTime_Req_Data "AuthTime - Authentische Zeit
ISO-TP Datenkanal - NA2FID
Request Knoten 0x73 Info_El (Zentralrechner)

Zentralrechner an Funktion Authentische Zeit (Request)";

CM_ SG_ 2583851800 Info_El_AuthTime_Resp_Data "AuthTime - Authentische Zeit
ISO-TP Datenkanal - NA2FID
Response Funktion 0x18 AuthTime

Funktion Authentische Zeit an Zentralrechner (Response)";

CM_ SG_ 1524 AMB_Charisma_FahrPr "MLBevo: Aktuelles Fahrprogramm des Charisma-Teilnehmers (siehe Systemlastenheft Drive Select)
MQB: Istwert der Kennlinie (siehe Systemlastenheft MQB FPA)";
CM_ SG_ 1524 AMB_Charisma_Status "Systemstatus des Charismateilnehmers

Wert 0x3 ist nur für Fahrzeuge ab MQB relevant";
CM_ SG_ 1524 BCM1_DI_Rampe_Innenlicht "Dimmrampe Innenlicht";
CM_ SG_ 1524 BCM1_DI_Rampe_Leselicht "Dimmrampe Leselicht";
CM_ SG_ 1524 BCM1_Innenlicht_gedimmt_H "Steuerung von BCM_Innenlicht_H";
CM_ SG_ 1524 BCM1_Innenlicht_gedimmt_V "Steuerung von BCM_Innenlicht_V";
CM_ SG_ 1524 BCM1_Innenlicht_H "Anforderung Innenlicht hinten";
CM_ SG_ 1524 BCM1_Innenlicht_V "Anforderung Innenlicht vorne";
CM_ SG_ 1524 BCM1_Leselicht_Anf_hl " Leselicht hinten links Anforderung";
CM_ SG_ 1524 BCM1_Leselicht_Anf_hr "Leselicht hinten rechts Anforderung";
CM_ SG_ 1524 BCM1_Leselicht_Anf_vl "Leselicht vorne links Anforderung";
CM_ SG_ 1524 BCM1_Leselicht_Anf_vr "Leselicht vorne rechts Anforderung";
CM_ SG_ 1524 BCM1_Leuchten_Aus "Innenbeleuchtung ausschalten (keine Änderung / ausschalten)";
CM_ SG_ 1524 IL_Bel_BFS_Ausstieg "Einschalten der Ausstiegsleuchten oder Türwarnleuchten in Tür oder im Schweller";
CM_ SG_ 1524 IL_Bel_FS_Ausstieg "Einschalten der Ausstiegsleuchten oder Türwarnleuchten in Tür oder im Schweller";
CM_ SG_ 1524 IL_Bel_HBFS_Ausstieg "Einschalten der Ausstiegsleuchten oder Türwarnleuchten in Tür oder im Schweller";
CM_ SG_ 1524 IL_Bel_HFS_Ausstieg "Einschalten der Ausstiegsleuchten oder Türwarnleuchten in Tür oder im Schweller";
CM_ SG_ 1524 IL_Dimmung_H_Tuerkontur "Dimmung Türkontur hinten (bei Änderung im 30 ms Raster)";
CM_ SG_ 1524 IL_Dimmung_Lautspr "Dimmung Umfeldbeleuchtung an Türaußenseite oder Außenspiegel";
CM_ SG_ 1524 IL_Dimmung_Tuerinnengriff "Dimmung Türinnengriff";
CM_ SG_ 1524 IL_Dimmung_Umfeldbel "Dimmung Umfeldbeleuchtung an Türaußenseite oder Außenspiegel";
CM_ SG_ 1524 IL_Dimmung_V_Tuerkontur "Dimmung Türkontur vorne (bei Änderung im 30 ms Raster)";
CM_ SG_ 1524 IL_Innenlicht_aktiv "Status Innenlicht";
CM_ SG_ 1524 IL_Klemme_30G_aktiv "Synchrones Abschalten";

CM_ SG_ 2527679583 IPA_02_BZ "4bit Botschaftszähler, wird mit jeder Sendebotschaft inkrementiert";
CM_ SG_ 2527679583 IPA_02_CRC "Für MLB:
Berechnung siehe Lastenheft 'Kommunikationsabsicherung für FlexRay und CAN'
Ab MQB und MLBevo:
Berechnung siehe Lastenheft 'End-to-End Kommunikationsabsicherung'

Endwerte siehe Begleitdokument 'S-PDU Kennungsfolgen'";
CM_ SG_ 2527679583 IPA_Akustik_PL_gefunden "Signalisiert ein akustische Benachrichtigung, dass Parklücken gefunden wurden.";
CM_ SG_ 2527679583 IPA_Anf_Meldungen "Das Signal fordert die Anzeige einer Meldung an. Jedem Signalwert ist eine Meldung zugeordnet. Das Signal ist derzeit für die Funktionen IPA/RPA und TPA implementiert.";
CM_ SG_ 2527679583 IPA_PL_Anzeige_links "Zeigt an, ob auf der linken Seite eine Parklücke erkannt wurde.";
CM_ SG_ 2527679583 IPA_PL_Anzeige_rechts "Zeigt an, ob auf der rechten Seite eine Parklücke erkannt wurde.";
CM_ SG_ 2527679583 Parken_aktives_System_02 "zeigt an welches parkendes System aktiv ist";
CM_ SG_ 2527679583 Parken_Aktivierungslicht_Anf "Anforderung des Aktivierungslichts nach erfolgreicher Aktivierungshandlung seitens Pilotiertem Parken.";
CM_ SG_ 2527679583 Parken_Bestaetigungsblinken_Anf "Anforderung seitens Pilotiertem Parken für ein Erfolgsblinken nach dem Erreichen der Zielposition bzw. für ein Abbruchsblinken bei Eintreten einer Abbruchsbedingung.";
CM_ SG_ 2527679583 Parken_Blinker_li_Anf "Anforderung seitens Parkens für 'Links blinken'";
CM_ SG_ 2527679583 Parken_Blinker_re_Anf "Anforderung seitens Parken für 'Rechts blinken'";
CM_ SG_ 2527679583 Parken_Fahrbereitschaftlicht_Anf "Anforderung des Fahrbereitschaftslichts";
CM_ SG_ 2527679583 Parken_Fahrerhinweise_Anf "Anforderung zur erneuten Lampenaufprüfung und Anzeige von Warnhinweisen nach einem pilotierten Ausparkvorgang.";
CM_ SG_ 2527679583 Parken_Fahrtrichtungslicht_Anf "Anforderung seitens Pilotiertem Parken für die Anzeige der initialen Fahrtrichtung nach Systemaktivierung.";
CM_ SG_ 2527679583 Parken_FFB_LED_Anf "Statusinformation des Pilotierten Parkens für die Ansteuerung der LED auf der Funkfernbedienung.";
CM_ SG_ 2527679583 Parken_Lichtnachlauf_Anf "Anforderung des Lichtnachlaufs beim BCM1 (analog Verlassenskonzept) für das Pilotierte Parken. ";
CM_ SG_ 2527679583 Parken_Lichtsteuerung_Anf "Anforderung zum Setzen des Lichtmodus des Fahrzeuges von der Parkfunktion";
CM_ SG_ 2527679583 Parken_Schluesselsuche_Anf "Ansteuerung der Schlüsselsuche für das pilotierte Parken.";
CM_ SG_ 2527679583 Parken_Seitenspiegel_Anf "Anforderung für Seitenspiegel an- oder abklappen beim PiloPa";
CM_ SG_ 2527679583 Parken_Wegfahrsperren_Anf "Ansteuerung der Wegfahrsperren Komponenten für das pilotierte Parken.  ";
CM_ SG_ 2527679583 Parken_ZR_Sondermodus_Anf "Anforderung Sondermodus, um beim „pilotierten Parken“ spezielle Funktionsanpassungen im Infotainment-Bereich zu ermöglichen (u.a. schnellerer Startup, Abschaltung BT)";
CM_ SG_ 2527679583 Parken_ZV_Schliessen "Anforderung für Zentralverriegelung verriegeln oder safen beim PiloPa";

CM_ SG_ 1841 ISO_ELV_Req_Data "OffBoard Tester Diagnose Request ELV";

CM_ SG_ 1947 ISO_ELV_Resp_Data "OffBoard Tester Diagnose Response ELV";

CM_ SG_ 1792 ISO_ALL_01_Req_Data "Funktionaler Request ALL";

CM_ SG_ 1819 ISO_HUD_Req_Data "OffBoard Tester Diagnose Request HUD";

CM_ SG_ 1925 ISO_HUD_Resp_Data "OffBoard Tester Diagnose Response HUD";

CM_ SG_ 1812 ISO_Kombi_Req_Data "Diagnose Request Kombiinstrument";

CM_ SG_ 1918 ISO_Kombi_Resp_Data "Diagnose Response Kombiinstrument";

CM_ SG_ 1836 ISO_MFG_Req_Data "OffBoard Tester Diagnose Request MFG";

CM_ SG_ 1942 ISO_MFG_Resp_Data "OffBoard Tester Diagnose Response MFG";

CM_ SG_ 1839 ISO_SFA_Req_Data "Diagnose Request SFA";

CM_ SG_ 1945 ISO_SFA_Resp_Data "Diagnose Response SFA";

CM_ SG_ 1905 ISO_TCO_Req_Data "Diagnose Request TCO";

CM_ SG_ 2011 ISO_TCO_Resp_Data "Diagnose Response Fahrtenschreiber";

CM_ SG_ 2549874849 ISOx_Bedienteil_Req_Data "Diagnose Request Bedienteil";

CM_ SG_ 2550005921 ISOx_Bedienteil_Resp_Data "Diagnose Response Bedienteil";

CM_ SG_ 2621440049 ISOx_ELV_Req_FD_Data "OffBoard Tester Diagnose Response ELV";

CM_ SG_ 2621571121 ISOx_ELV_Resp_FD_Data "OffBoard Tester Diagnose Response ELV";

CM_ SG_ 2621505536 ISOx_Funkt_Req_All_FD_Data "OffBoard Tester funktionaler Diagnose Request ALL CANFD";

CM_ SG_ 2621440027 ISOx_HUD_Req_FD_Data "OffBoard Tester Diagnose Response HUD";

CM_ SG_ 2621571099 ISOx_HUD_Resp_FD_Data "OffBoard Tester Diagnose Response HUD";

CM_ SG_ 2621440020 ISOx_Kombi_Req_FD_Data "Diagnose Request FD Kombi";

CM_ SG_ 2621571092 ISOx_Kombi_Resp_FD_Data "Diagnose Response FD Kombi";

CM_ SG_ 2549874852 ISOx_LSH_Req_Data "VWAG Diagnose";

CM_ SG_ 2550005924 ISOx_LSH_Resp_Data "VWAG Diagnose";

CM_ SG_ 2621440044 ISOx_MFG_Req_FD_Data "OffBoard Tester Diagnose Response MFG";

CM_ SG_ 2621571116 ISOx_MFG_Resp_FD_Data "OffBoard Tester Diagnose Response MFG";

CM_ SG_ 2621440113 ISOx_TCO_Req_FD_Data "Diagnose Request FD TCO";

CM_ SG_ 2621571185 ISOx_TCO_Resp_FD_Data "Diagnose Response FD TCO";

CM_ SG_ 2550398990 ISOx_TRE_2_Req_Data "OffBoard Tester Diagnose Request TRE_2";

CM_ SG_ 2550530062 ISOx_TRE_2_Resp_Data "OffBoard Tester Diagnose Response TRE_2";
BA_DEF_REL_ BU_SG_REL_  "GenSigTimeoutTime" INT 0 65535;
BA_DEF_ BO_  "DiagRequest" ENUM "No", "Yes";
BA_DEF_ BO_  "DiagResponse" ENUM "No", "Yes";
BA_DEF_ BO_  "DiagState" ENUM "No", "Yes";
BA_DEF_ BO_  "GenMsgChkConstant" HEX 0 4095;
BA_DEF_ BO_  "GenMsgCycleTime" INT 0 65535;
BA_DEF_ BO_  "GenMsgCycleTimeFast" INT 0 65535;
BA_DEF_ BO_  "GenMsgDelayTime" INT 0 100000;
BA_DEF_ BO_  "GenMsgILSupport" ENUM "No", "Yes";
BA_DEF_ BO_  "GenMsgNrOfRepetition" INT 0 100;
BA_DEF_ BO_  "GenMsgPDUConstants" STRING;
BA_DEF_ BO_  "GenMsgSendType" ENUM "Cyclic", "not_used", "not_used", "not_used", "not_used", "not_used", "not_used", "IfActive", "NoMsgSendType";
BA_DEF_ BO_  "GenMsgStartDelayTime" INT 0 100000;
BA_DEF_ BO_  "NmMessage" ENUM "No", "Yes";
BA_DEF_ BO_  "NmhMessage" ENUM "No", "Yes";
BA_DEF_ BO_  "MsgType" ENUM "Application", "NM ", "NMH", "TP2.0", "ISO-TP ", "BAP", "EID", "KS", "XCP_PRE_CONFIGURED", "XCP_RUNTIME_CONFIGURED";
BA_DEF_ BO_  "VAGTP20_API" HEX 0 255;
BA_DEF_ BO_  "VAGTP20_DynConnection" ENUM "No", "Yes";
BA_DEF_ BO_  "VAGTP20_DynSetup" ENUM "No", "Yes";
BA_DEF_ BO_  "VAGTP20_StatConnection" ENUM "No", "Yes";
BA_DEF_ BO_  "CANFD_BRS" ENUM "0", "1";
BA_DEF_ BO_  "VFrameFormat" ENUM "StandardCAN", "ExtendedCAN", "reserved", "reserved", "reserved", "reserved", "reserved", "reserved", "reserved", "reserved", "reserved", "reserved", "reserved", "reserved", "StandardCAN_FD", "ExtendedCAN_FD";
BA_DEF_ SG_  "GenSigActiveRepetitions" INT -2147483648 2147483647;
BA_DEF_ SG_  "GenSigInactiveValue" INT -2147483648 2147483647;
BA_DEF_ SG_  "GenSigSendType" ENUM "Cyclic", "OnWrite", "OnWriteWithRepetition", "OnChange", "OnChangeWithRepetition", "IfActive", "IfActiveWithRepetition", "NoSigSendType", "OnChangeAndIfActive", "OnChangeAndIfActiveWithRepetition";
BA_DEF_ SG_  "GenSigStartValue" INT -2147483648 2147483647;
BA_DEF_ SG_  "NWM-WakeupAllowed" ENUM "No", "Yes";
BA_DEF_ SG_  "GenSigFuncType" ENUM "NoFunction", "MsgCounter", "CRC-8", "XOR", "XOR-2", "DatedBit", "SW-Kl15", "CHK", "Constant", "Protocol", "CRC-8-SAE_J1850", "CRC-32", "DataLength", "DataID", "MsgCounter16", "SOK-Signatur", "Cluster";
BA_DEF_ SG_  "GenSigSwitchedByIgnition" ENUM "No", "Yes";
BA_DEF_ SG_  "Fehlerwert" HEX 0 2147483647;
BA_DEF_ SG_  "GenSigMissingSourceValue" HEX 0 2147483647;
BA_DEF_DEF_REL_  "GenSigTimeoutTime" 0;
BA_DEF_DEF_  "DiagRequest" "No";
BA_DEF_DEF_  "DiagResponse" "No";
BA_DEF_DEF_  "DiagState" "No";
BA_DEF_DEF_  "GenMsgChkConstant" 0;
BA_DEF_DEF_  "GenMsgCycleTime" 0;
BA_DEF_DEF_  "GenMsgCycleTimeFast" 0;
BA_DEF_DEF_  "GenMsgDelayTime" 0;
BA_DEF_DEF_  "GenMsgILSupport" "No";
BA_DEF_DEF_  "GenMsgNrOfRepetition" 0;
BA_DEF_DEF_  "GenMsgPDUConstants" "";
BA_DEF_DEF_  "GenMsgSendType" "NoMsgSendType";
BA_DEF_DEF_  "GenMsgStartDelayTime" 0;
BA_DEF_DEF_  "NmMessage" "No";
BA_DEF_DEF_  "NmhMessage" "No";
BA_DEF_DEF_  "MsgType" "Application";
BA_DEF_DEF_  "VAGTP20_API" 0;
BA_DEF_DEF_  "VAGTP20_DynConnection" "No";
BA_DEF_DEF_  "VAGTP20_DynSetup" "No";
BA_DEF_DEF_  "VAGTP20_StatConnection" "No";
BA_DEF_DEF_  "CANFD_BRS" "1";
BA_DEF_DEF_  "VFrameFormat" "StandardCAN";
BA_DEF_DEF_  "GenSigActiveRepetitions" 0;
BA_DEF_DEF_  "GenSigInactiveValue" 0;
BA_DEF_DEF_  "GenSigSendType" "NoSigSendType";
BA_DEF_DEF_  "GenSigStartValue" 0;
BA_DEF_DEF_  "NWM-WakeupAllowed" "No";
BA_DEF_DEF_  "GenSigFuncType" "NoFunction";
BA_DEF_DEF_  "GenSigSwitchedByIgnition" "Yes";
BA_DEF_DEF_  "Fehlerwert" 0;
BA_DEF_DEF_  "GenSigMissingSourceValue" 0;
BA_ "GenMsgCycleTime" BO_ 988 50;
BA_ "GenMsgDelayTime" BO_ 988 10;
BA_ "GenMsgILSupport" BO_ 988 1;
BA_ "GenMsgSendType" BO_ 988 0;
BA_ "VFrameFormat" BO_ 988 14;
BA_ "GenMsgCycleTime" BO_ 1002 200;
BA_ "GenMsgDelayTime" BO_ 1002 20;
BA_ "GenMsgILSupport" BO_ 1002 1;
BA_ "GenMsgSendType" BO_ 1002 0;
BA_ "VFrameFormat" BO_ 1002 14;
BA_ "GenMsgCycleTime" BO_ 1003 100;
BA_ "GenMsgDelayTime" BO_ 1003 50;
BA_ "GenMsgILSupport" BO_ 1003 1;
BA_ "GenMsgPDUConstants" BO_ 1003 "0x58,0xc7,0x6d,0xd6,0x2f,0x26,0xf7,0x3d,0x31,0x0c,0x75,0xdb,0x92,0x53,0x87,0x09";
BA_ "GenMsgSendType" BO_ 1003 0;
BA_ "VFrameFormat" BO_ 1003 14;
BA_ "MsgType" BO_ 2583695384 4;
BA_ "VFrameFormat" BO_ 2583695384 15;
BA_ "MsgType" BO_ 2583826456 4;
BA_ "VFrameFormat" BO_ 2583826456 15;
BA_ "GenMsgCycleTime" BO_ 173 50;
BA_ "GenMsgILSupport" BO_ 173 1;
BA_ "GenMsgPDUConstants" BO_ 173 "0x3f,0x69,0x39,0xdc,0x94,0xf9,0x14,0x64,0xd8,0x6a,0x34,0xce,0xa2,0x55,0xb5,0x2c";
BA_ "GenMsgSendType" BO_ 173 0;
BA_ "VFrameFormat" BO_ 173 14;
BA_ "GenMsgCycleTime" BO_ 884 1000;
BA_ "GenMsgILSupport" BO_ 884 1;
BA_ "GenMsgSendType" BO_ 884 0;
BA_ "VFrameFormat" BO_ 884 14;
BA_ "GenMsgCycleTime" BO_ 886 1000;
BA_ "GenMsgILSupport" BO_ 886 1;
BA_ "GenMsgSendType" BO_ 886 0;
BA_ "VFrameFormat" BO_ 886 14;
BA_ "GenMsgCycleTime" BO_ 891 1000;
BA_ "GenMsgILSupport" BO_ 891 1;
BA_ "GenMsgSendType" BO_ 891 0;
BA_ "VFrameFormat" BO_ 891 14;
BA_ "GenMsgCycleTime" BO_ 1343 1000;
BA_ "GenMsgILSupport" BO_ 1343 1;
BA_ "GenMsgSendType" BO_ 1343 0;
BA_ "VFrameFormat" BO_ 1343 14;
BA_ "GenMsgCycleTime" BO_ 299 30;
BA_ "GenMsgILSupport" BO_ 299 1;
BA_ "GenMsgPDUConstants" BO_ 299 "0x6a,0x38,0xb4,0x27,0x22,0xef,0xe1,0xbb,0xf8,0x80,0x84,0x49,0xc7,0x9e,0x1e,0x2b";
BA_ "GenMsgSendType" BO_ 299 0;
BA_ "VFrameFormat" BO_ 299 14;
BA_ "GenMsgCycleTime" BO_ 1410 200;
BA_ "GenMsgDelayTime" BO_ 1410 20;
BA_ "GenMsgILSupport" BO_ 1410 1;
BA_ "GenMsgSendType" BO_ 1410 0;
BA_ "VFrameFormat" BO_ 1410 14;
BA_ "GenMsgCycleTime" BO_ 588 50;
BA_ "GenMsgILSupport" BO_ 588 1;
BA_ "GenMsgSendType" BO_ 588 0;
BA_ "VFrameFormat" BO_ 588 14;
BA_ "GenMsgCycleTime" BO_ 589 50;
BA_ "GenMsgILSupport" BO_ 589 1;
BA_ "GenMsgSendType" BO_ 589 0;
BA_ "VFrameFormat" BO_ 589 14;
BA_ "GenMsgCycleTime" BO_ 2331595854 50;
BA_ "GenMsgILSupport" BO_ 2331595854 1;
BA_ "GenMsgSendType" BO_ 2331595854 0;
BA_ "VFrameFormat" BO_ 2331595854 15;
BA_ "GenMsgCycleTime" BO_ 1609 1000;
BA_ "GenMsgDelayTime" BO_ 1609 100;
BA_ "GenMsgILSupport" BO_ 1609 1;
BA_ "GenMsgSendType" BO_ 1609 0;
BA_ "VFrameFormat" BO_ 1609 14;
BA_ "GenMsgCycleTime" BO_ 1452 100;
BA_ "GenMsgILSupport" BO_ 1452 1;
BA_ "GenMsgSendType" BO_ 1452 0;
BA_ "VFrameFormat" BO_ 1452 14;
BA_ "GenMsgCycleTime" BO_ 1283 100;
BA_ "GenMsgDelayTime" BO_ 1283 10;
BA_ "GenMsgILSupport" BO_ 1283 1;
BA_ "GenMsgPDUConstants" BO_ 1283 "0xed,0xd6,0x96,0x63,0xa5,0x12,0xd5,0x9a,0x1e,0x0d,0x24,0xcd,0x8c,0xa6,0x2f,0x41";
BA_ "GenMsgSendType" BO_ 1283 0;
BA_ "VFrameFormat" BO_ 1283 14;
BA_ "GenMsgCycleTime" BO_ 1428 500;
BA_ "GenMsgDelayTime" BO_ 1428 50;
BA_ "GenMsgILSupport" BO_ 1428 1;
BA_ "GenMsgSendType" BO_ 1428 0;
BA_ "VFrameFormat" BO_ 1428 14;
BA_ "VFrameFormat" BO_ 27 14;
BA_ "MsgType" BO_ 2583720728 4;
BA_ "VFrameFormat" BO_ 2583720728 15;
BA_ "MsgType" BO_ 2583851800 4;
BA_ "VFrameFormat" BO_ 2583851800 15;
BA_ "GenMsgCycleTime" BO_ 1524 500;
BA_ "GenMsgDelayTime" BO_ 1524 50;
BA_ "GenMsgILSupport" BO_ 1524 1;
BA_ "GenMsgSendType" BO_ 1524 0;
BA_ "VFrameFormat" BO_ 1524 14;
BA_ "GenMsgCycleTime" BO_ 2527679583 1000;
BA_ "GenMsgCycleTimeFast" BO_ 2527679583 100;
BA_ "GenMsgDelayTime" BO_ 2527679583 50;
BA_ "GenMsgILSupport" BO_ 2527679583 1;
BA_ "GenMsgNrOfRepetition" BO_ 2527679583 5;
BA_ "GenMsgPDUConstants" BO_ 2527679583 "0xc6,0x7f,0x85,0xb6,0xe6,0xae,0xf8,0x26,0xb0,0x8c,0x19,0x10,0x5b,0x33,0x64,0x6c";
BA_ "GenMsgSendType" BO_ 2527679583 0;
BA_ "VFrameFormat" BO_ 2527679583 15;
BA_ "DiagRequest" BO_ 1841 1;
BA_ "MsgType" BO_ 1841 4;
BA_ "VFrameFormat" BO_ 1841 14;
BA_ "DiagResponse" BO_ 1947 1;
BA_ "MsgType" BO_ 1947 4;
BA_ "VFrameFormat" BO_ 1947 14;
BA_ "DiagState" BO_ 1792 1;
BA_ "MsgType" BO_ 1792 4;
BA_ "VFrameFormat" BO_ 1792 14;
BA_ "DiagRequest" BO_ 1819 1;
BA_ "MsgType" BO_ 1819 4;
BA_ "VFrameFormat" BO_ 1819 14;
BA_ "DiagResponse" BO_ 1925 1;
BA_ "MsgType" BO_ 1925 4;
BA_ "VFrameFormat" BO_ 1925 14;
BA_ "DiagRequest" BO_ 1812 1;
BA_ "MsgType" BO_ 1812 4;
BA_ "VFrameFormat" BO_ 1812 14;
BA_ "DiagResponse" BO_ 1918 1;
BA_ "MsgType" BO_ 1918 4;
BA_ "VFrameFormat" BO_ 1918 14;
BA_ "DiagRequest" BO_ 1836 1;
BA_ "MsgType" BO_ 1836 4;
BA_ "VFrameFormat" BO_ 1836 14;
BA_ "DiagResponse" BO_ 1942 1;
BA_ "MsgType" BO_ 1942 4;
BA_ "VFrameFormat" BO_ 1942 14;
BA_ "DiagRequest" BO_ 1839 1;
BA_ "MsgType" BO_ 1839 4;
BA_ "VFrameFormat" BO_ 1839 14;
BA_ "DiagResponse" BO_ 1945 1;
BA_ "MsgType" BO_ 1945 4;
BA_ "VFrameFormat" BO_ 1945 14;
BA_ "DiagRequest" BO_ 1905 1;
BA_ "MsgType" BO_ 1905 4;
BA_ "VFrameFormat" BO_ 1905 14;
BA_ "DiagResponse" BO_ 2011 1;
BA_ "MsgType" BO_ 2011 4;
BA_ "VFrameFormat" BO_ 2011 14;
BA_ "DiagRequest" BO_ 2549874849 1;
BA_ "MsgType" BO_ 2549874849 4;
BA_ "VFrameFormat" BO_ 2549874849 15;
BA_ "DiagResponse" BO_ 2550005921 1;
BA_ "MsgType" BO_ 2550005921 4;
BA_ "VFrameFormat" BO_ 2550005921 15;
BA_ "DiagRequest" BO_ 2621440049 1;
BA_ "MsgType" BO_ 2621440049 4;
BA_ "VFrameFormat" BO_ 2621440049 15;
BA_ "DiagResponse" BO_ 2621571121 1;
BA_ "MsgType" BO_ 2621571121 4;
BA_ "VFrameFormat" BO_ 2621571121 15;
BA_ "DiagState" BO_ 2621505536 1;
BA_ "MsgType" BO_ 2621505536 4;
BA_ "VFrameFormat" BO_ 2621505536 15;
BA_ "DiagRequest" BO_ 2621440027 1;
BA_ "MsgType" BO_ 2621440027 4;
BA_ "VFrameFormat" BO_ 2621440027 15;
BA_ "DiagResponse" BO_ 2621571099 1;
BA_ "MsgType" BO_ 2621571099 4;
BA_ "VFrameFormat" BO_ 2621571099 15;
BA_ "DiagRequest" BO_ 2621440020 1;
BA_ "MsgType" BO_ 2621440020 4;
BA_ "VFrameFormat" BO_ 2621440020 15;
BA_ "DiagResponse" BO_ 2621571092 1;
BA_ "MsgType" BO_ 2621571092 4;
BA_ "VFrameFormat" BO_ 2621571092 15;
BA_ "DiagRequest" BO_ 2549874852 1;
BA_ "MsgType" BO_ 2549874852 4;
BA_ "VFrameFormat" BO_ 2549874852 15;
BA_ "DiagResponse" BO_ 2550005924 1;
BA_ "MsgType" BO_ 2550005924 4;
BA_ "VFrameFormat" BO_ 2550005924 15;
BA_ "DiagRequest" BO_ 2621440044 1;
BA_ "MsgType" BO_ 2621440044 4;
BA_ "VFrameFormat" BO_ 2621440044 15;
BA_ "DiagResponse" BO_ 2621571116 1;
BA_ "MsgType" BO_ 2621571116 4;
BA_ "VFrameFormat" BO_ 2621571116 15;
BA_ "DiagRequest" BO_ 2621440113 1;
BA_ "MsgType" BO_ 2621440113 4;
BA_ "VFrameFormat" BO_ 2621440113 15;
BA_ "DiagResponse" BO_ 2621571185 1;
BA_ "MsgType" BO_ 2621571185 4;
BA_ "VFrameFormat" BO_ 2621571185 15;
BA_ "DiagRequest" BO_ 2550398990 1;
BA_ "MsgType" BO_ 2550398990 4;
BA_ "VFrameFormat" BO_ 2550398990 15;
BA_ "DiagResponse" BO_ 2550530062 1;
BA_ "MsgType" BO_ 2550530062 4;
BA_ "VFrameFormat" BO_ 2550530062 15;
BA_ "GenSigSendType" SG_ 988 ACC_18_alt 0;
BA_ "GenSigStartValue" SG_ 988 ACC_18_alt 1;
BA_ "GenSigFuncType" SG_ 988 ACC_18_alt 5;
BA_ "GenSigSwitchedByIgnition" SG_ 988 ACC_18_alt 0;
BA_ "GenSigSendType" SG_ 988 ACC_Status_ACC 0;
BA_ "GenSigSendType" SG_ 988 Bel_DiETa_Mode2 3;
BA_ "GenSigSwitchedByIgnition" SG_ 988 Bel_DiETa_Mode2 0;
BA_ "Fehlerwert" SG_ 988 Bel_DiETa_Mode2 3;
BA_ "GenSigSendType" SG_ 988 EPB_Schalterposition 0;
BA_ "GenSigSwitchedByIgnition" SG_ 988 EPB_Schalterposition 0;
BA_ "Fehlerwert" SG_ 988 EPB_Schalterposition 3;
BA_ "GenSigSendType" SG_ 988 EPB_Status_02 0;
BA_ "GenSigStartValue" SG_ 988 EPB_Status_02 6;
BA_ "GenSigSwitchedByIgnition" SG_ 988 EPB_Status_02 0;
BA_ "GenSigSendType" SG_ 988 ESP_07_alt 0;
BA_ "GenSigStartValue" SG_ 988 ESP_07_alt 1;
BA_ "GenSigFuncType" SG_ 988 ESP_07_alt 5;
BA_ "GenSigSwitchedByIgnition" SG_ 988 ESP_07_alt 0;
BA_ "GenSigSendType" SG_ 988 ESP_50_alt 0;
BA_ "GenSigStartValue" SG_ 988 ESP_50_alt 1;
BA_ "GenSigFuncType" SG_ 988 ESP_50_alt 5;
BA_ "GenSigSwitchedByIgnition" SG_ 988 ESP_50_alt 0;
BA_ "GenSigSendType" SG_ 988 ESP_Rollenmodus_Deaktivieren 0;
BA_ "GenSigSwitchedByIgnition" SG_ 988 ESP_Rollenmodus_Deaktivieren 0;
BA_ "GenSigSendType" SG_ 988 GE_Fahrstufe 3;
BA_ "GenSigStartValue" SG_ 988 GE_Fahrstufe 1;
BA_ "GenSigSwitchedByIgnition" SG_ 988 GE_Fahrstufe 0;
BA_ "Fehlerwert" SG_ 988 GE_Fahrstufe 15;
BA_ "GenSigSendType" SG_ 988 GE_Freilauf_Status 0;
BA_ "GenSigSwitchedByIgnition" SG_ 988 GE_Freilauf_Status 0;
BA_ "Fehlerwert" SG_ 988 GE_Freilauf_Status 7;
BA_ "GenSigSendType" SG_ 988 GE_LaunchControl 3;
BA_ "GenSigSwitchedByIgnition" SG_ 988 GE_LaunchControl 0;
BA_ "GenSigSendType" SG_ 988 GE_Notlauf 3;
BA_ "GenSigSwitchedByIgnition" SG_ 988 GE_Notlauf 0;
BA_ "GenSigSendType" SG_ 988 GE_Sperr_Info_WFS 3;
BA_ "GenSigSwitchedByIgnition" SG_ 988 GE_Sperr_Info_WFS 0;
BA_ "GenSigSendType" SG_ 988 GE_Ursache_Fahrstufe_N 0;
BA_ "GenSigSwitchedByIgnition" SG_ 988 GE_Ursache_Fahrstufe_N 0;
BA_ "GenSigSendType" SG_ 988 GE_Veto_Rollfaehigkeit 0;
BA_ "GenSigSwitchedByIgnition" SG_ 988 GE_Veto_Rollfaehigkeit 0;
BA_ "GenSigSendType" SG_ 988 Getriebe_11_alt 0;
BA_ "GenSigStartValue" SG_ 988 Getriebe_11_alt 1;
BA_ "GenSigFuncType" SG_ 988 Getriebe_11_alt 5;
BA_ "GenSigSwitchedByIgnition" SG_ 988 Getriebe_11_alt 0;
BA_ "GenSigSendType" SG_ 988 Getriebe_13_alt 0;
BA_ "GenSigStartValue" SG_ 988 Getriebe_13_alt 1;
BA_ "GenSigFuncType" SG_ 988 Getriebe_13_alt 5;
BA_ "GenSigSwitchedByIgnition" SG_ 988 Getriebe_13_alt 0;
BA_ "GenSigSendType" SG_ 988 Getriebe_14_alt 0;
BA_ "GenSigStartValue" SG_ 988 Getriebe_14_alt 1;
BA_ "GenSigFuncType" SG_ 988 Getriebe_14_alt 5;
BA_ "GenSigSwitchedByIgnition" SG_ 988 Getriebe_14_alt 0;
BA_ "GenSigSendType" SG_ 988 Getriebe_17_alt 0;
BA_ "GenSigStartValue" SG_ 988 Getriebe_17_alt 1;
BA_ "GenSigFuncType" SG_ 988 Getriebe_17_alt 5;
BA_ "GenSigSwitchedByIgnition" SG_ 988 Getriebe_17_alt 0;
BA_ "GenSigSendType" SG_ 988 MKE_Stufe 0;
BA_ "GenSigSwitchedByIgnition" SG_ 988 MKE_Stufe 0;
BA_ "GenSigSendType" SG_ 988 MKE_Texte 0;
BA_ "GenSigSwitchedByIgnition" SG_ 988 MKE_Texte 0;
BA_ "GenSigSendType" SG_ 988 MO_Drehzahl_01 0;
BA_ "GenSigSwitchedByIgnition" SG_ 988 MO_Drehzahl_01 0;
BA_ "GenSigSendType" SG_ 988 MO_QBit_Drehzahl_01 0;
BA_ "GenSigStartValue" SG_ 988 MO_QBit_Drehzahl_01 1;
BA_ "GenSigSwitchedByIgnition" SG_ 988 MO_QBit_Drehzahl_01 0;
BA_ "GenSigSendType" SG_ 988 Motor_12_alt 0;
BA_ "GenSigStartValue" SG_ 988 Motor_12_alt 1;
BA_ "GenSigFuncType" SG_ 988 Motor_12_alt 5;
BA_ "GenSigSwitchedByIgnition" SG_ 988 Motor_12_alt 0;
BA_ "GenSigSendType" SG_ 988 TSK_06_alt 0;
BA_ "GenSigStartValue" SG_ 988 TSK_06_alt 1;
BA_ "GenSigSwitchedByIgnition" SG_ 988 TSK_06_alt 0;
BA_ "GenSigSendType" SG_ 988 TSK_Hauptschalter_GRA_ACC 0;
BA_ "GenSigSwitchedByIgnition" SG_ 988 TSK_Hauptschalter_GRA_ACC 0;
BA_ "Fehlerwert" SG_ 988 TSK_Hauptschalter_GRA_ACC 3;
BA_ "GenSigSendType" SG_ 988 TSK_Limiter_ausgewaehlt 0;
BA_ "GenSigSwitchedByIgnition" SG_ 988 TSK_Limiter_ausgewaehlt 0;
BA_ "GenSigSendType" SG_ 988 TSK_Status 0;
BA_ "GenSigStartValue" SG_ 988 TSK_Status 1;
BA_ "GenSigSwitchedByIgnition" SG_ 988 TSK_Status 0;
BA_ "GenSigSendType" SG_ 1002 AWV_03_alt 0;
BA_ "GenSigStartValue" SG_ 1002 AWV_03_alt 1;
BA_ "GenSigFuncType" SG_ 1002 AWV_03_alt 5;
BA_ "GenSigSwitchedByIgnition" SG_ 1002 AWV_03_alt 0;
BA_ "GenSigSendType" SG_ 1002 AWV_Verz_Anf 3;
BA_ "GenSigStartValue" SG_ 1002 AWV_Verz_Anf 1023;
BA_ "GenSigSendType" SG_ 1002 AWV_Verz_Freigabe 3;
BA_ "GenSigSendType" SG_ 1002 AWV_Zielobjekttyp 3;
BA_ "GenSigStartValue" SG_ 1002 AWV_Zielobjekttyp 15;
BA_ "GenSigSendType" SG_ 1002 Bel_DiETa_Mode 3;
BA_ "GenSigSwitchedByIgnition" SG_ 1002 Bel_DiETa_Mode 0;
BA_ "Fehlerwert" SG_ 1002 Bel_DiETa_Mode 3;
BA_ "GenSigSendType" SG_ 1002 EBKV_03_alt 0;
BA_ "GenSigStartValue" SG_ 1002 EBKV_03_alt 1;
BA_ "GenSigFuncType" SG_ 1002 EBKV_03_alt 5;
BA_ "GenSigSwitchedByIgnition" SG_ 1002 EBKV_03_alt 0;
BA_ "GenSigSendType" SG_ 1002 EBKV_Fahrer_bremst 3;
BA_ "GenSigSwitchedByIgnition" SG_ 1002 EBKV_Fahrer_bremst 0;
BA_ "GenSigSendType" SG_ 1002 ESP_05_alt 0;
BA_ "GenSigStartValue" SG_ 1002 ESP_05_alt 1;
BA_ "GenSigFuncType" SG_ 1002 ESP_05_alt 5;
BA_ "GenSigSwitchedByIgnition" SG_ 1002 ESP_05_alt 0;
BA_ "GenSigSendType" SG_ 1002 ESP_Bremsdruck 0;
BA_ "GenSigStartValue" SG_ 1002 ESP_Bremsdruck 100;
BA_ "GenSigSwitchedByIgnition" SG_ 1002 ESP_Bremsdruck 0;
BA_ "Fehlerwert" SG_ 1002 ESP_Bremsdruck 1023;
BA_ "GenSigSendType" SG_ 1002 GE_Sumpftemperatur 0;
BA_ "GenSigSwitchedByIgnition" SG_ 1002 GE_Sumpftemperatur 0;
BA_ "Fehlerwert" SG_ 1002 GE_Sumpftemperatur 255;
BA_ "GenSigSendType" SG_ 1002 Getriebe_14_alt 0;
BA_ "GenSigStartValue" SG_ 1002 Getriebe_14_alt 1;
BA_ "GenSigFuncType" SG_ 1002 Getriebe_14_alt 5;
BA_ "GenSigSwitchedByIgnition" SG_ 1002 Getriebe_14_alt 0;
BA_ "GenSigSendType" SG_ 1002 MO_Fahrpedalrohwert_01 0;
BA_ "GenSigSwitchedByIgnition" SG_ 1002 MO_Fahrpedalrohwert_01 0;
BA_ "Fehlerwert" SG_ 1002 MO_Fahrpedalrohwert_01 255;
BA_ "GenSigSendType" SG_ 1002 MO_Mom_Ist_Summe 0;
BA_ "GenSigStartValue" SG_ 1002 MO_Mom_Ist_Summe 1022;
BA_ "GenSigSwitchedByIgnition" SG_ 1002 MO_Mom_Ist_Summe 0;
BA_ "GenSigSendType" SG_ 1002 Motor_11_alt 0;
BA_ "GenSigStartValue" SG_ 1002 Motor_11_alt 1;
BA_ "GenSigFuncType" SG_ 1002 Motor_11_alt 5;
BA_ "GenSigSwitchedByIgnition" SG_ 1002 Motor_11_alt 0;
BA_ "GenSigSendType" SG_ 1002 Motor_20_alt 0;
BA_ "GenSigStartValue" SG_ 1002 Motor_20_alt 1;
BA_ "GenSigFuncType" SG_ 1002 Motor_20_alt 5;
BA_ "GenSigSwitchedByIgnition" SG_ 1002 Motor_20_alt 0;
BA_ "GenSigSendType" SG_ 1002 PaCo_DiETa_LED 3;
BA_ "GenSigSwitchedByIgnition" SG_ 1002 PaCo_DiETa_LED 0;
BA_ "GenSigSendType" SG_ 1002 RTM_Warnstatus 3;
BA_ "GenSigSwitchedByIgnition" SG_ 1002 RTM_Warnstatus 0;
BA_ "GenSigSendType" SG_ 1003 Areaview_01_alt 0;
BA_ "GenSigStartValue" SG_ 1003 Areaview_01_alt 1;
BA_ "GenSigFuncType" SG_ 1003 Areaview_01_alt 5;
BA_ "GenSigSwitchedByIgnition" SG_ 1003 Areaview_01_alt 0;
BA_ "GenSigSendType" SG_ 1003 AV_Umfeldbeleuchtung_Anf 0;
BA_ "GenSigSwitchedByIgnition" SG_ 1003 AV_Umfeldbeleuchtung_Anf 0;
BA_ "GenSigSendType" SG_ 1003 EBKV_03_alt 0;
BA_ "GenSigStartValue" SG_ 1003 EBKV_03_alt 1;
BA_ "GenSigFuncType" SG_ 1003 EBKV_03_alt 5;
BA_ "GenSigSwitchedByIgnition" SG_ 1003 EBKV_03_alt 0;
BA_ "GenSigSendType" SG_ 1003 EBKV_Fahrer_bremst 3;
BA_ "GenSigSwitchedByIgnition" SG_ 1003 EBKV_Fahrer_bremst 0;
BA_ "GenSigSendType" SG_ 1003 EBKV_QBit_Fahrer_bremst 3;
BA_ "GenSigStartValue" SG_ 1003 EBKV_QBit_Fahrer_bremst 1;
BA_ "GenSigSwitchedByIgnition" SG_ 1003 EBKV_QBit_Fahrer_bremst 0;
BA_ "GenSigSendType" SG_ 1003 EFF_Verbrauch_STH 3;
BA_ "GenSigSwitchedByIgnition" SG_ 1003 EFF_Verbrauch_STH 0;
BA_ "Fehlerwert" SG_ 1003 EFF_Verbrauch_STH 127;
BA_ "GenSigSendType" SG_ 1003 EPS_Lastinfo 0;
BA_ "GenSigStartValue" SG_ 1003 EPS_Lastinfo 254;
BA_ "GenSigSwitchedByIgnition" SG_ 1003 EPS_Lastinfo 0;
BA_ "Fehlerwert" SG_ 1003 EPS_Lastinfo 255;
BA_ "GenSigSendType" SG_ 1003 ESP_50_alt 0;
BA_ "GenSigStartValue" SG_ 1003 ESP_50_alt 1;
BA_ "GenSigFuncType" SG_ 1003 ESP_50_alt 5;
BA_ "GenSigSwitchedByIgnition" SG_ 1003 ESP_50_alt 0;
BA_ "GenSigSendType" SG_ 1003 ESP_Bremsdruck 0;
BA_ "GenSigStartValue" SG_ 1003 ESP_Bremsdruck 100;
BA_ "GenSigSwitchedByIgnition" SG_ 1003 ESP_Bremsdruck 0;
BA_ "Fehlerwert" SG_ 1003 ESP_Bremsdruck 1023;
BA_ "GenSigSendType" SG_ 1003 ESP_QBit_Bremsdruck 0;
BA_ "GenSigStartValue" SG_ 1003 ESP_QBit_Bremsdruck 1;
BA_ "GenSigSwitchedByIgnition" SG_ 1003 ESP_QBit_Bremsdruck 0;
BA_ "GenSigSendType" SG_ 1003 LH_EPS_02_alt 0;
BA_ "GenSigStartValue" SG_ 1003 LH_EPS_02_alt 1;
BA_ "GenSigFuncType" SG_ 1003 LH_EPS_02_alt 5;
BA_ "GenSigSwitchedByIgnition" SG_ 1003 LH_EPS_02_alt 0;
BA_ "GenSigSendType" SG_ 1003 LIN_2_alt 0;
BA_ "GenSigStartValue" SG_ 1003 LIN_2_alt 1;
BA_ "GenSigFuncType" SG_ 1003 LIN_2_alt 5;
BA_ "GenSigSwitchedByIgnition" SG_ 1003 LIN_2_alt 0;
BA_ "GenSigSendType" SG_ 1003 LR_HZG_01_alt 0;
BA_ "GenSigStartValue" SG_ 1003 LR_HZG_01_alt 1;
BA_ "GenSigFuncType" SG_ 1003 LR_HZG_01_alt 5;
BA_ "GenSigSwitchedByIgnition" SG_ 1003 LR_HZG_01_alt 0;
BA_ "GenSigSendType" SG_ 1003 LR_HZG_Konfiguration 0;
BA_ "GenSigSwitchedByIgnition" SG_ 1003 LR_HZG_Konfiguration 0;
BA_ "GenSigSendType" SG_ 1003 LR_HZG_Taster_on_off 0;
BA_ "GenSigSwitchedByIgnition" SG_ 1003 LR_HZG_Taster_on_off 0;
BA_ "GenSigSendType" SG_ 1003 LR_HZG_Temp_Sensor 0;
BA_ "GenSigStartValue" SG_ 1003 LR_HZG_Temp_Sensor 254;
BA_ "GenSigSwitchedByIgnition" SG_ 1003 LR_HZG_Temp_Sensor 0;
BA_ "GenSigSendType" SG_ 1003 MFL_Signalhorn 3;
BA_ "GenSigSwitchedByIgnition" SG_ 1003 MFL_Signalhorn 0;
BA_ "GenSigSendType" SG_ 1003 MO_Fahrpedalrohwert_01 0;
BA_ "GenSigSwitchedByIgnition" SG_ 1003 MO_Fahrpedalrohwert_01 0;
BA_ "Fehlerwert" SG_ 1003 MO_Fahrpedalrohwert_01 255;
BA_ "GenSigSendType" SG_ 1003 MO_QBit_Fahrpedalwerte_01 0;
BA_ "GenSigStartValue" SG_ 1003 MO_QBit_Fahrpedalwerte_01 1;
BA_ "GenSigSwitchedByIgnition" SG_ 1003 MO_QBit_Fahrpedalwerte_01 0;
BA_ "GenSigSendType" SG_ 1003 MO_temporaere_Fahrerabwesenheit 3;
BA_ "GenSigSwitchedByIgnition" SG_ 1003 MO_temporaere_Fahrerabwesenheit 0;
BA_ "GenSigSendType" SG_ 1003 Motor_20_alt 0;
BA_ "GenSigStartValue" SG_ 1003 Motor_20_alt 1;
BA_ "GenSigFuncType" SG_ 1003 Motor_20_alt 5;
BA_ "GenSigSwitchedByIgnition" SG_ 1003 Motor_20_alt 0;
BA_ "GenSigSendType" SG_ 1003 Parkhilfe_01_alt 0;
BA_ "GenSigStartValue" SG_ 1003 Parkhilfe_01_alt 1;
BA_ "GenSigFuncType" SG_ 1003 Parkhilfe_01_alt 5;
BA_ "GenSigSwitchedByIgnition" SG_ 1003 Parkhilfe_01_alt 0;
BA_ "GenSigSendType" SG_ 1003 PH_Stoermeldung 3;
BA_ "GenSigSendType" SG_ 2583695384 Gateway_AuthTime_Req_Data 3;
BA_ "GenSigFuncType" SG_ 2583695384 Gateway_AuthTime_Req_Data 9;
BA_ "GenSigSwitchedByIgnition" SG_ 2583695384 Gateway_AuthTime_Req_Data 0;
BA_ "GenSigSendType" SG_ 2583826456 Gateway_AuthTime_Resp_Data 3;
BA_ "GenSigFuncType" SG_ 2583826456 Gateway_AuthTime_Resp_Data 9;
BA_ "GenSigSwitchedByIgnition" SG_ 2583826456 Gateway_AuthTime_Resp_Data 0;
BA_ "GenSigSendType" SG_ 173 GE_Fahrstufe 0;
BA_ "GenSigStartValue" SG_ 173 GE_Fahrstufe 1;
BA_ "GenSigSwitchedByIgnition" SG_ 173 GE_Fahrstufe 0;
BA_ "Fehlerwert" SG_ 173 GE_Fahrstufe 15;
BA_ "GenSigSendType" SG_ 173 GE_Ursache_Fahrstufe_N 0;
BA_ "GenSigSwitchedByIgnition" SG_ 173 GE_Ursache_Fahrstufe_N 0;
BA_ "GenSigSendType" SG_ 173 Getriebe_11_BZ 0;
BA_ "GenSigFuncType" SG_ 173 Getriebe_11_BZ 1;
BA_ "GenSigSwitchedByIgnition" SG_ 173 Getriebe_11_BZ 0;
BA_ "GenSigSendType" SG_ 173 Getriebe_11_CRC 0;
BA_ "GenSigFuncType" SG_ 173 Getriebe_11_CRC 2;
BA_ "GenSigSwitchedByIgnition" SG_ 173 Getriebe_11_CRC 0;
BA_ "GenSigSendType" SG_ 884 GNSS_Nachrichtenpaket_ID2 0;
BA_ "GenSigSwitchedByIgnition" SG_ 884 GNSS_Nachrichtenpaket_ID2 0;
BA_ "GenSigSendType" SG_ 884 GNSS_Ortung_2D_Geschw_ue_Grund 0;
BA_ "GenSigStartValue" SG_ 884 GNSS_Ortung_2D_Geschw_ue_Grund 510;
BA_ "GenSigSwitchedByIgnition" SG_ 884 GNSS_Ortung_2D_Geschw_ue_Grund 0;
BA_ "Fehlerwert" SG_ 884 GNSS_Ortung_2D_Geschw_ue_Grund 511;
BA_ "GenSigSendType" SG_ 884 GNSS_Ortung_Ausrichtung 0;
BA_ "GenSigStartValue" SG_ 884 GNSS_Ortung_Ausrichtung 4094;
BA_ "GenSigSwitchedByIgnition" SG_ 884 GNSS_Ortung_Ausrichtung 0;
BA_ "Fehlerwert" SG_ 884 GNSS_Ortung_Ausrichtung 4095;
BA_ "GenSigSendType" SG_ 884 GNSS_Ortung_Latenz 0;
BA_ "GenSigStartValue" SG_ 884 GNSS_Ortung_Latenz 1022;
BA_ "GenSigSwitchedByIgnition" SG_ 884 GNSS_Ortung_Latenz 0;
BA_ "Fehlerwert" SG_ 884 GNSS_Ortung_Latenz 1023;
BA_ "GenSigSendType" SG_ 884 GNSS_Ortung_Noerdliche_Geschw 0;
BA_ "GenSigStartValue" SG_ 884 GNSS_Ortung_Noerdliche_Geschw 1022;
BA_ "GenSigSwitchedByIgnition" SG_ 884 GNSS_Ortung_Noerdliche_Geschw 0;
BA_ "Fehlerwert" SG_ 884 GNSS_Ortung_Noerdliche_Geschw 1023;
BA_ "GenSigSendType" SG_ 884 GNSS_Ortung_Oestliche_Geschw 0;
BA_ "GenSigStartValue" SG_ 884 GNSS_Ortung_Oestliche_Geschw 1022;
BA_ "GenSigSwitchedByIgnition" SG_ 884 GNSS_Ortung_Oestliche_Geschw 0;
BA_ "Fehlerwert" SG_ 884 GNSS_Ortung_Oestliche_Geschw 1023;
BA_ "GenSigSendType" SG_ 884 GNSS_Ortung_Vertikale_Geschw 0;
BA_ "GenSigStartValue" SG_ 884 GNSS_Ortung_Vertikale_Geschw 1022;
BA_ "GenSigSwitchedByIgnition" SG_ 884 GNSS_Ortung_Vertikale_Geschw 0;
BA_ "Fehlerwert" SG_ 884 GNSS_Ortung_Vertikale_Geschw 1023;
BA_ "GenSigSendType" SG_ 886 GNSS_Nachrichtenpaket_ID3 0;
BA_ "GenSigSwitchedByIgnition" SG_ 886 GNSS_Nachrichtenpaket_ID3 0;
BA_ "GenSigSendType" SG_ 886 GNSS_Ortung_GDOP 0;
BA_ "GenSigStartValue" SG_ 886 GNSS_Ortung_GDOP 510;
BA_ "GenSigSwitchedByIgnition" SG_ 886 GNSS_Ortung_GDOP 0;
BA_ "Fehlerwert" SG_ 886 GNSS_Ortung_GDOP 511;
BA_ "GenSigSendType" SG_ 886 GNSS_Ortung_Guete_Ausrichtung 0;
BA_ "GenSigStartValue" SG_ 886 GNSS_Ortung_Guete_Ausrichtung 62;
BA_ "GenSigSwitchedByIgnition" SG_ 886 GNSS_Ortung_Guete_Ausrichtung 0;
BA_ "Fehlerwert" SG_ 886 GNSS_Ortung_Guete_Ausrichtung 63;
BA_ "GenSigSendType" SG_ 886 GNSS_Ortung_Guete_Geschwindigk 0;
BA_ "GenSigStartValue" SG_ 886 GNSS_Ortung_Guete_Geschwindigk 62;
BA_ "GenSigSwitchedByIgnition" SG_ 886 GNSS_Ortung_Guete_Geschwindigk 0;
BA_ "Fehlerwert" SG_ 886 GNSS_Ortung_Guete_Geschwindigk 63;
BA_ "GenSigSendType" SG_ 886 GNSS_Ortung_Guete_horizontal 0;
BA_ "GenSigStartValue" SG_ 886 GNSS_Ortung_Guete_horizontal 254;
BA_ "GenSigSwitchedByIgnition" SG_ 886 GNSS_Ortung_Guete_horizontal 0;
BA_ "Fehlerwert" SG_ 886 GNSS_Ortung_Guete_horizontal 255;
BA_ "GenSigSendType" SG_ 886 GNSS_Ortung_Guete_vertikal 0;
BA_ "GenSigStartValue" SG_ 886 GNSS_Ortung_Guete_vertikal 62;
BA_ "GenSigSwitchedByIgnition" SG_ 886 GNSS_Ortung_Guete_vertikal 0;
BA_ "Fehlerwert" SG_ 886 GNSS_Ortung_Guete_vertikal 63;
BA_ "GenSigSendType" SG_ 886 GNSS_Ortung_HDOP 0;
BA_ "GenSigStartValue" SG_ 886 GNSS_Ortung_HDOP 510;
BA_ "GenSigSwitchedByIgnition" SG_ 886 GNSS_Ortung_HDOP 0;
BA_ "Fehlerwert" SG_ 886 GNSS_Ortung_HDOP 511;
BA_ "GenSigSendType" SG_ 886 GNSS_Ortung_PDOP 0;
BA_ "GenSigStartValue" SG_ 886 GNSS_Ortung_PDOP 510;
BA_ "GenSigSwitchedByIgnition" SG_ 886 GNSS_Ortung_PDOP 0;
BA_ "Fehlerwert" SG_ 886 GNSS_Ortung_PDOP 511;
BA_ "GenSigSendType" SG_ 886 GNSS_Ortung_VDOP 0;
BA_ "GenSigStartValue" SG_ 886 GNSS_Ortung_VDOP 510;
BA_ "GenSigSwitchedByIgnition" SG_ 886 GNSS_Ortung_VDOP 0;
BA_ "Fehlerwert" SG_ 886 GNSS_Ortung_VDOP 511;
BA_ "GenSigSendType" SG_ 891 GNSS_Empfaenger_Status 0;
BA_ "GenSigSwitchedByIgnition" SG_ 891 GNSS_Empfaenger_Status 0;
BA_ "GenSigSendType" SG_ 891 GNSS_Empfangbare_Satelliten 0;
BA_ "GenSigSwitchedByIgnition" SG_ 891 GNSS_Empfangbare_Satelliten 0;
BA_ "GenSigSendType" SG_ 891 GNSS_Genutzte_Satelliten 0;
BA_ "GenSigSwitchedByIgnition" SG_ 891 GNSS_Genutzte_Satelliten 0;
BA_ "GenSigSendType" SG_ 891 GNSS_GLONASS_in_Nutzung 0;
BA_ "GenSigSwitchedByIgnition" SG_ 891 GNSS_GLONASS_in_Nutzung 0;
BA_ "GenSigSendType" SG_ 891 GNSS_GPS_in_Nutzung 0;
BA_ "GenSigSwitchedByIgnition" SG_ 891 GNSS_GPS_in_Nutzung 0;
BA_ "GenSigSendType" SG_ 891 GNSS_Nachrichtenpaket_ID5 0;
BA_ "GenSigSwitchedByIgnition" SG_ 891 GNSS_Nachrichtenpaket_ID5 0;
BA_ "GenSigSendType" SG_ 891 GNSS_Sichtbare_Satelliten 0;
BA_ "GenSigSwitchedByIgnition" SG_ 891 GNSS_Sichtbare_Satelliten 0;
BA_ "GenSigSendType" SG_ 891 GNSS_UTC_Zeit 0;
BA_ "GenSigSwitchedByIgnition" SG_ 891 GNSS_UTC_Zeit 0;
BA_ "GenSigSendType" SG_ 1343 GNSS_Nachrichtenpaket_ID7 0;
BA_ "GenSigSwitchedByIgnition" SG_ 1343 GNSS_Nachrichtenpaket_ID7 0;
BA_ "GenSigSendType" SG_ 1343 GNSS_V_Daten_Veraltet 0;
BA_ "GenSigSwitchedByIgnition" SG_ 1343 GNSS_V_Daten_Veraltet 0;
BA_ "GenSigSendType" SG_ 1343 GNSS_V_FIX_Typ 0;
BA_ "GenSigSwitchedByIgnition" SG_ 1343 GNSS_V_FIX_Typ 0;
BA_ "GenSigSendType" SG_ 1343 GNSS_V_Geschw_2D 0;
BA_ "GenSigStartValue" SG_ 1343 GNSS_V_Geschw_2D 16382;
BA_ "GenSigSwitchedByIgnition" SG_ 1343 GNSS_V_Geschw_2D 0;
BA_ "Fehlerwert" SG_ 1343 GNSS_V_Geschw_2D 16383;
BA_ "GenSigSendType" SG_ 1343 GNSS_V_Geschw_2D_Guete95 0;
BA_ "GenSigStartValue" SG_ 1343 GNSS_V_Geschw_2D_Guete95 1022;
BA_ "GenSigSwitchedByIgnition" SG_ 1343 GNSS_V_Geschw_2D_Guete95 0;
BA_ "Fehlerwert" SG_ 1343 GNSS_V_Geschw_2D_Guete95 1023;
BA_ "GenSigSendType" SG_ 1343 GNSS_V_Geschw_Vertikal 0;
BA_ "GenSigStartValue" SG_ 1343 GNSS_V_Geschw_Vertikal 32766;
BA_ "GenSigSwitchedByIgnition" SG_ 1343 GNSS_V_Geschw_Vertikal 0;
BA_ "Fehlerwert" SG_ 1343 GNSS_V_Geschw_Vertikal 32767;
BA_ "GenSigSendType" SG_ 1343 GNSS_V_Geschw_Vertikal_Guete95 0;
BA_ "GenSigStartValue" SG_ 1343 GNSS_V_Geschw_Vertikal_Guete95 1022;
BA_ "GenSigSwitchedByIgnition" SG_ 1343 GNSS_V_Geschw_Vertikal_Guete95 0;
BA_ "Fehlerwert" SG_ 1343 GNSS_V_Geschw_Vertikal_Guete95 1023;
BA_ "GenSigSendType" SG_ 1343 GNSS_V_Latenz_vollstaendig 0;
BA_ "GenSigStartValue" SG_ 1343 GNSS_V_Latenz_vollstaendig 1022;
BA_ "GenSigSwitchedByIgnition" SG_ 1343 GNSS_V_Latenz_vollstaendig 0;
BA_ "Fehlerwert" SG_ 1343 GNSS_V_Latenz_vollstaendig 1023;
BA_ "GenSigSendType" SG_ 299 GRA_Abbrechen 0;
BA_ "GenSigSendType" SG_ 299 GRA_ACC_01_BZ 0;
BA_ "GenSigFuncType" SG_ 299 GRA_ACC_01_BZ 1;
BA_ "GenSigSendType" SG_ 299 GRA_ACC_01_CRC 0;
BA_ "GenSigFuncType" SG_ 299 GRA_ACC_01_CRC 2;
BA_ "GenSigSendType" SG_ 299 GRA_Codierung 0;
BA_ "GenSigSendType" SG_ 299 GRA_Fehler 0;
BA_ "Fehlerwert" SG_ 299 GRA_Fehler 1;
BA_ "GenSigSendType" SG_ 299 GRA_Hauptschalter 0;
BA_ "GenSigSendType" SG_ 299 GRA_LIM_Taste_verfuegbar 0;
BA_ "GenSigFuncType" SG_ 299 GRA_LIM_Taste_verfuegbar 8;
BA_ "GenSigSendType" SG_ 299 GRA_Limiter 0;
BA_ "GenSigSendType" SG_ 299 GRA_PIT_Limiter 0;
BA_ "GenSigSwitchedByIgnition" SG_ 299 GRA_PIT_Limiter 0;
BA_ "GenSigSendType" SG_ 299 GRA_reserveByte5 0;
BA_ "GenSigSendType" SG_ 299 GRA_reserveByte6 0;
BA_ "GenSigSendType" SG_ 299 GRA_reserveByte7 0;
BA_ "GenSigSendType" SG_ 299 GRA_reserveByte8 0;
BA_ "GenSigSendType" SG_ 299 GRA_Tip_Hoch 0;
BA_ "GenSigSendType" SG_ 299 GRA_Tip_Runter 0;
BA_ "GenSigSendType" SG_ 299 GRA_Tip_Setzen 0;
BA_ "GenSigSendType" SG_ 299 GRA_Tip_Stufe_2 0;
BA_ "GenSigSendType" SG_ 299 GRA_Tip_Wiederaufnahme 0;
BA_ "GenSigSendType" SG_ 299 GRA_TravelAssist 0;
BA_ "GenSigSwitchedByIgnition" SG_ 299 GRA_TravelAssist 0;
BA_ "GenSigSendType" SG_ 299 GRA_Typ_Bedienteil 0;
BA_ "GenSigSendType" SG_ 299 GRA_Typ_Hauptschalter 0;
BA_ "GenSigSendType" SG_ 299 GRA_Verstellung_Zeitluecke 0;
BA_ "GenSigSendType" SG_ 1410 HD_Bewegung_auf 0;
BA_ "GenSigSwitchedByIgnition" SG_ 1410 HD_Bewegung_auf 0;
BA_ "GenSigSendType" SG_ 1410 HD_Bewegung_zu 0;
BA_ "GenSigSwitchedByIgnition" SG_ 1410 HD_Bewegung_zu 0;
BA_ "GenSigSendType" SG_ 1410 HD_Endstellung_oben 0;
BA_ "GenSigSwitchedByIgnition" SG_ 1410 HD_Endstellung_oben 0;
BA_ "GenSigSendType" SG_ 1410 HD_Endstellung_unten 0;
BA_ "GenSigSwitchedByIgnition" SG_ 1410 HD_Endstellung_unten 0;
BA_ "GenSigSendType" SG_ 1410 HD_Innentaster_betaetigt 0;
BA_ "GenSigSwitchedByIgnition" SG_ 1410 HD_Innentaster_betaetigt 0;
BA_ "GenSigSendType" SG_ 1410 HD_Kupp_Ma_aktiv 0;
BA_ "GenSigSwitchedByIgnition" SG_ 1410 HD_Kupp_Ma_aktiv 0;
BA_ "GenSigSendType" SG_ 1410 HD_Kupp_Sl_aktiv 0;
BA_ "GenSigSwitchedByIgnition" SG_ 1410 HD_Kupp_Sl_aktiv 0;
BA_ "GenSigSendType" SG_ 1410 HD_Position 0;
BA_ "GenSigSwitchedByIgnition" SG_ 1410 HD_Position 0;
BA_ "GenSigSendType" SG_ 1410 HD_Rueckmeld_prog 0;
BA_ "GenSigSwitchedByIgnition" SG_ 1410 HD_Rueckmeld_prog 0;
BA_ "GenSigSendType" SG_ 1410 HD_SG_MA_KD_Fehler 0;
BA_ "GenSigSwitchedByIgnition" SG_ 1410 HD_SG_MA_KD_Fehler 0;
BA_ "GenSigSendType" SG_ 1410 HD_SG_SL_KD_Fehler 0;
BA_ "GenSigSwitchedByIgnition" SG_ 1410 HD_SG_SL_KD_Fehler 0;
BA_ "GenSigSendType" SG_ 1410 HD_Spannung 0;
BA_ "GenSigSwitchedByIgnition" SG_ 1410 HD_Spannung 0;
BA_ "GenSigSendType" SG_ 1410 HD_Taster_defekt 0;
BA_ "GenSigSwitchedByIgnition" SG_ 1410 HD_Taster_defekt 0;
BA_ "GenSigSendType" SG_ 1410 HD_UeKB_erkannt 0;
BA_ "GenSigSwitchedByIgnition" SG_ 1410 HD_UeKB_erkannt 0;
BA_ "GenSigSendType" SG_ 1410 HD_Verr_Taster_betaetigt_inv 0;
BA_ "GenSigSwitchedByIgnition" SG_ 1410 HD_Verr_Taster_betaetigt_inv 0;
BA_ "GenSigSendType" SG_ 1410 HD_Verriegelungstaster_betaetigt 0;
BA_ "GenSigSwitchedByIgnition" SG_ 1410 HD_Verriegelungstaster_betaetigt 0;
BA_ "GenSigSendType" SG_ 1410 HD_ZZH_Schalter_S3 3;
BA_ "GenSigSwitchedByIgnition" SG_ 1410 HD_ZZH_Schalter_S3 0;
BA_ "GenSigSendType" SG_ 1410 HDSG_Anf_Umluftklappe 3;
BA_ "GenSigSwitchedByIgnition" SG_ 1410 HDSG_Anf_Umluftklappe 0;
BA_ "GenSigSendType" SG_ 588 ASW_Akustik_Einstellung 0;
BA_ "GenSigSendType" SG_ 588 ASW_Ausgabemodus_BFS 0;
BA_ "GenSigSwitchedByIgnition" SG_ 588 ASW_Ausgabemodus_BFS 0;
BA_ "GenSigSendType" SG_ 588 ASW_Ausgabemodus_FS 0;
BA_ "GenSigSwitchedByIgnition" SG_ 588 ASW_Ausgabemodus_FS 0;
BA_ "GenSigSendType" SG_ 588 ASW_Ausgabemodus_HBFS 0;
BA_ "GenSigSwitchedByIgnition" SG_ 588 ASW_Ausgabemodus_HBFS 0;
BA_ "GenSigSendType" SG_ 588 ASW_Ausgabemodus_HFS 0;
BA_ "GenSigSwitchedByIgnition" SG_ 588 ASW_Ausgabemodus_HFS 0;
BA_ "GenSigSendType" SG_ 588 ASW_Kombiausgabe 0;
BA_ "GenSigSendType" SG_ 588 ASW_Kombitexte 0;
BA_ "GenSigSwitchedByIgnition" SG_ 588 ASW_Kombitexte 0;
BA_ "GenSigSendType" SG_ 588 ASW_Modus 0;
BA_ "GenSigStartValue" SG_ 588 ASW_Modus 4;
BA_ "GenSigSendType" SG_ 588 ASW_Status 0;
BA_ "GenSigSwitchedByIgnition" SG_ 588 ASW_Status 0;
BA_ "Fehlerwert" SG_ 588 ASW_Status 2;
BA_ "GenSigSendType" SG_ 588 ASW_Ton_Richtung_HL 0;
BA_ "GenSigSwitchedByIgnition" SG_ 588 ASW_Ton_Richtung_HL 0;
BA_ "GenSigSendType" SG_ 588 ASW_Ton_Richtung_HR 0;
BA_ "GenSigSwitchedByIgnition" SG_ 588 ASW_Ton_Richtung_HR 0;
BA_ "GenSigSendType" SG_ 588 ASW_Ton_Richtung_VL 0;
BA_ "GenSigSwitchedByIgnition" SG_ 588 ASW_Ton_Richtung_VL 0;
BA_ "GenSigSendType" SG_ 588 ASW_Ton_Richtung_VR 0;
BA_ "GenSigSwitchedByIgnition" SG_ 588 ASW_Ton_Richtung_VR 0;
BA_ "GenSigSendType" SG_ 588 ASW_Warnung_BFS 0;
BA_ "GenSigSwitchedByIgnition" SG_ 588 ASW_Warnung_BFS 0;
BA_ "GenSigSendType" SG_ 588 ASW_Warnung_FS 0;
BA_ "GenSigSwitchedByIgnition" SG_ 588 ASW_Warnung_FS 0;
BA_ "GenSigSendType" SG_ 588 Heckradar_Kombitexte 0;
BA_ "GenSigSwitchedByIgnition" SG_ 588 Heckradar_Kombitexte 0;
BA_ "GenSigSendType" SG_ 588 HRE_Anzeigetexte 0;
BA_ "GenSigSwitchedByIgnition" SG_ 588 HRE_Anzeigetexte 0;
BA_ "GenSigSendType" SG_ 588 RCTA_Kombitexte 0;
BA_ "GenSigSwitchedByIgnition" SG_ 588 RCTA_Kombitexte 0;
BA_ "GenSigSendType" SG_ 588 SWA_Anzeigen 0;
BA_ "GenSigSwitchedByIgnition" SG_ 588 SWA_Anzeigen 0;
BA_ "GenSigSendType" SG_ 588 SWA_Blindheit_erkannt 0;
BA_ "GenSigSendType" SG_ 588 SWA_Blindheitsverdacht 0;
BA_ "GenSigSendType" SG_ 588 SWA_Brightness_Mode_FPM 0;
BA_ "GenSigSwitchedByIgnition" SG_ 588 SWA_Brightness_Mode_FPM 0;
BA_ "Fehlerwert" SG_ 588 SWA_Brightness_Mode_FPM 15;
BA_ "GenSigSendType" SG_ 588 SWA_FT_RueckLED 0;
BA_ "GenSigSwitchedByIgnition" SG_ 588 SWA_FT_RueckLED 0;
BA_ "GenSigSendType" SG_ 588 SWA_Gischtzaehler 0;
BA_ "GenSigSendType" SG_ 588 SWA_Infostufe_Assist_li 0;
BA_ "GenSigSendType" SG_ 588 SWA_Infostufe_Assist_re 0;
BA_ "GenSigSendType" SG_ 588 SWA_Kombiausgabe 0;
BA_ "GenSigSendType" SG_ 588 SWA_Kombiwarnung 0;
BA_ "GenSigSwitchedByIgnition" SG_ 588 SWA_Kombiwarnung 0;
BA_ "GenSigSendType" SG_ 588 SWA_LED_Ausgabemodus_BFS 0;
BA_ "GenSigSendType" SG_ 588 SWA_LED_Ausgabemodus_FS 0;
BA_ "GenSigSendType" SG_ 588 SWA_LED_Hell_BFS 0;
BA_ "GenSigStartValue" SG_ 588 SWA_LED_Hell_BFS 126;
BA_ "Fehlerwert" SG_ 588 SWA_LED_Hell_BFS 127;
BA_ "GenSigSendType" SG_ 588 SWA_LED_Hell_FS 0;
BA_ "GenSigStartValue" SG_ 588 SWA_LED_Hell_FS 126;
BA_ "Fehlerwert" SG_ 588 SWA_LED_Hell_FS 127;
BA_ "GenSigSendType" SG_ 588 SWA_Modus 0;
BA_ "GenSigSendType" SG_ 588 SWA_Modus_System 0;
BA_ "GenSigSendType" SG_ 588 SWA_rel_Fehler 0;
BA_ "Fehlerwert" SG_ 588 SWA_rel_Fehler 1;
BA_ "GenSigSendType" SG_ 588 SWA_rel_Nichtverf 0;
BA_ "GenSigSendType" SG_ 588 SWA_Sta_aktiv 0;
BA_ "GenSigSendType" SG_ 588 SWA_Sta_passiv 0;
BA_ "GenSigSendType" SG_ 588 SWA_Standziele_li 0;
BA_ "GenSigSendType" SG_ 588 SWA_Standziele_re 0;
BA_ "GenSigSendType" SG_ 588 SWA_Status 0;
BA_ "Fehlerwert" SG_ 588 SWA_Status 3;
BA_ "GenSigSendType" SG_ 588 SWA_Status_KuFu 0;
BA_ "Fehlerwert" SG_ 588 SWA_Status_KuFu 3;
BA_ "GenSigSendType" SG_ 588 SWA_Status_System 0;
BA_ "Fehlerwert" SG_ 588 SWA_Status_System 3;
BA_ "GenSigSendType" SG_ 588 SWA_Warnstufe_Assist_li 0;
BA_ "GenSigSendType" SG_ 588 SWA_Warnstufe_Assist_re 0;
BA_ "GenSigSendType" SG_ 589 SWA_Infostufe_SWA_li 0;
BA_ "GenSigSendType" SG_ 589 SWA_Infostufe_SWA_re 0;
BA_ "GenSigSendType" SG_ 589 SWA_Kolonne_li 0;
BA_ "GenSigSendType" SG_ 589 SWA_Kolonne_mi 0;
BA_ "GenSigSendType" SG_ 589 SWA_Kolonne_re 0;
BA_ "GenSigSendType" SG_ 589 SWA_Obj_01_Breite 0;
BA_ "GenSigStartValue" SG_ 589 SWA_Obj_01_Breite 127;
BA_ "GenSigSendType" SG_ 589 SWA_Obj_01_Existenzwahrsch 0;
BA_ "GenSigStartValue" SG_ 589 SWA_Obj_01_Existenzwahrsch 127;
BA_ "GenSigSendType" SG_ 589 SWA_Obj_01_Gemessen 0;
BA_ "GenSigSendType" SG_ 589 SWA_Obj_01_GeschwRelX 0;
BA_ "GenSigStartValue" SG_ 589 SWA_Obj_01_GeschwRelX 511;
BA_ "GenSigSendType" SG_ 589 SWA_Obj_01_GeschwRelY 0;
BA_ "GenSigStartValue" SG_ 589 SWA_Obj_01_GeschwRelY 511;
BA_ "GenSigSendType" SG_ 589 SWA_Obj_01_ID 0;
BA_ "GenSigStartValue" SG_ 589 SWA_Obj_01_ID 31;
BA_ "GenSigSwitchedByIgnition" SG_ 589 SWA_Obj_01_ID 0;
BA_ "GenSigSendType" SG_ 589 SWA_Obj_01_Laenge 0;
BA_ "GenSigStartValue" SG_ 589 SWA_Obj_01_Laenge 127;
BA_ "GenSigSendType" SG_ 589 SWA_Obj_01_Objektklasse 0;
BA_ "GenSigStartValue" SG_ 589 SWA_Obj_01_Objektklasse 15;
BA_ "GenSigSendType" SG_ 589 SWA_Obj_01_PositionX 0;
BA_ "GenSigStartValue" SG_ 589 SWA_Obj_01_PositionX 511;
BA_ "GenSigSendType" SG_ 589 SWA_Obj_01_PositionY 0;
BA_ "GenSigStartValue" SG_ 589 SWA_Obj_01_PositionY 255;
BA_ "GenSigSendType" SG_ 589 SWA_Obj_01_ReferenzPkt 0;
BA_ "GenSigStartValue" SG_ 589 SWA_Obj_01_ReferenzPkt 15;
BA_ "GenSigSendType" SG_ 589 SWA_Obj_02_Breite 0;
BA_ "GenSigStartValue" SG_ 589 SWA_Obj_02_Breite 127;
BA_ "GenSigSendType" SG_ 589 SWA_Obj_02_Existenzwahrsch 0;
BA_ "GenSigStartValue" SG_ 589 SWA_Obj_02_Existenzwahrsch 127;
BA_ "GenSigSendType" SG_ 589 SWA_Obj_02_Gemessen 0;
BA_ "GenSigSendType" SG_ 589 SWA_Obj_02_GeschwRelX 0;
BA_ "GenSigStartValue" SG_ 589 SWA_Obj_02_GeschwRelX 511;
BA_ "GenSigSendType" SG_ 589 SWA_Obj_02_GeschwRelY 0;
BA_ "GenSigStartValue" SG_ 589 SWA_Obj_02_GeschwRelY 511;
BA_ "GenSigSendType" SG_ 589 SWA_Obj_02_ID 0;
BA_ "GenSigStartValue" SG_ 589 SWA_Obj_02_ID 31;
BA_ "GenSigSwitchedByIgnition" SG_ 589 SWA_Obj_02_ID 0;
BA_ "GenSigSendType" SG_ 589 SWA_Obj_02_Laenge 0;
BA_ "GenSigStartValue" SG_ 589 SWA_Obj_02_Laenge 127;
BA_ "GenSigSendType" SG_ 589 SWA_Obj_02_Objektklasse 0;
BA_ "GenSigStartValue" SG_ 589 SWA_Obj_02_Objektklasse 15;
BA_ "GenSigSendType" SG_ 589 SWA_Obj_02_PositionX 0;
BA_ "GenSigStartValue" SG_ 589 SWA_Obj_02_PositionX 511;
BA_ "GenSigSendType" SG_ 589 SWA_Obj_02_PositionY 0;
BA_ "GenSigStartValue" SG_ 589 SWA_Obj_02_PositionY 255;
BA_ "GenSigSendType" SG_ 589 SWA_Obj_02_ReferenzPkt 0;
BA_ "GenSigStartValue" SG_ 589 SWA_Obj_02_ReferenzPkt 15;
BA_ "GenSigSendType" SG_ 589 SWA_Obj_03_Breite 0;
BA_ "GenSigStartValue" SG_ 589 SWA_Obj_03_Breite 127;
BA_ "GenSigSendType" SG_ 589 SWA_Obj_03_Existenzwahrsch 0;
BA_ "GenSigStartValue" SG_ 589 SWA_Obj_03_Existenzwahrsch 127;
BA_ "GenSigSendType" SG_ 589 SWA_Obj_03_Gemessen 0;
BA_ "GenSigSendType" SG_ 589 SWA_Obj_03_GeschwRelX 0;
BA_ "GenSigStartValue" SG_ 589 SWA_Obj_03_GeschwRelX 511;
BA_ "GenSigSendType" SG_ 589 SWA_Obj_03_GeschwRelY 0;
BA_ "GenSigStartValue" SG_ 589 SWA_Obj_03_GeschwRelY 511;
BA_ "GenSigSendType" SG_ 589 SWA_Obj_03_ID 0;
BA_ "GenSigStartValue" SG_ 589 SWA_Obj_03_ID 31;
BA_ "GenSigSwitchedByIgnition" SG_ 589 SWA_Obj_03_ID 0;
BA_ "GenSigSendType" SG_ 589 SWA_Obj_03_Laenge 0;
BA_ "GenSigStartValue" SG_ 589 SWA_Obj_03_Laenge 127;
BA_ "GenSigSendType" SG_ 589 SWA_Obj_03_Objektklasse 0;
BA_ "GenSigStartValue" SG_ 589 SWA_Obj_03_Objektklasse 15;
BA_ "GenSigSendType" SG_ 589 SWA_Obj_03_PositionX 0;
BA_ "GenSigStartValue" SG_ 589 SWA_Obj_03_PositionX 511;
BA_ "GenSigSendType" SG_ 589 SWA_Obj_03_PositionY 0;
BA_ "GenSigStartValue" SG_ 589 SWA_Obj_03_PositionY 255;
BA_ "GenSigSendType" SG_ 589 SWA_Obj_03_ReferenzPkt 0;
BA_ "GenSigStartValue" SG_ 589 SWA_Obj_03_ReferenzPkt 15;
BA_ "GenSigSendType" SG_ 589 SWA_Obj_04_Breite 0;
BA_ "GenSigStartValue" SG_ 589 SWA_Obj_04_Breite 127;
BA_ "GenSigSendType" SG_ 589 SWA_Obj_04_Existenzwahrsch 0;
BA_ "GenSigStartValue" SG_ 589 SWA_Obj_04_Existenzwahrsch 127;
BA_ "GenSigSendType" SG_ 589 SWA_Obj_04_Gemessen 0;
BA_ "GenSigSendType" SG_ 589 SWA_Obj_04_GeschwRelX 0;
BA_ "GenSigStartValue" SG_ 589 SWA_Obj_04_GeschwRelX 511;
BA_ "GenSigSendType" SG_ 589 SWA_Obj_04_GeschwRelY 0;
BA_ "GenSigStartValue" SG_ 589 SWA_Obj_04_GeschwRelY 511;
BA_ "GenSigSendType" SG_ 589 SWA_Obj_04_ID 0;
BA_ "GenSigStartValue" SG_ 589 SWA_Obj_04_ID 31;
BA_ "GenSigSwitchedByIgnition" SG_ 589 SWA_Obj_04_ID 0;
BA_ "GenSigSendType" SG_ 589 SWA_Obj_04_Laenge 0;
BA_ "GenSigStartValue" SG_ 589 SWA_Obj_04_Laenge 127;
BA_ "GenSigSendType" SG_ 589 SWA_Obj_04_Objektklasse 0;
BA_ "GenSigStartValue" SG_ 589 SWA_Obj_04_Objektklasse 15;
BA_ "GenSigSendType" SG_ 589 SWA_Obj_04_PositionX 0;
BA_ "GenSigStartValue" SG_ 589 SWA_Obj_04_PositionX 511;
BA_ "GenSigSendType" SG_ 589 SWA_Obj_04_PositionY 0;
BA_ "GenSigStartValue" SG_ 589 SWA_Obj_04_PositionY 255;
BA_ "GenSigSendType" SG_ 589 SWA_Obj_04_ReferenzPkt 0;
BA_ "GenSigStartValue" SG_ 589 SWA_Obj_04_ReferenzPkt 15;
BA_ "GenSigSendType" SG_ 589 SWA_Obj_05_Breite 0;
BA_ "GenSigStartValue" SG_ 589 SWA_Obj_05_Breite 127;
BA_ "GenSigSendType" SG_ 589 SWA_Obj_05_Existenzwahrsch 0;
BA_ "GenSigStartValue" SG_ 589 SWA_Obj_05_Existenzwahrsch 127;
BA_ "GenSigSendType" SG_ 589 SWA_Obj_05_Gemessen 0;
BA_ "GenSigSendType" SG_ 589 SWA_Obj_05_GeschwRelX 0;
BA_ "GenSigStartValue" SG_ 589 SWA_Obj_05_GeschwRelX 511;
BA_ "GenSigSendType" SG_ 589 SWA_Obj_05_GeschwRelY 0;
BA_ "GenSigStartValue" SG_ 589 SWA_Obj_05_GeschwRelY 511;
BA_ "GenSigSendType" SG_ 589 SWA_Obj_05_ID 0;
BA_ "GenSigStartValue" SG_ 589 SWA_Obj_05_ID 31;
BA_ "GenSigSwitchedByIgnition" SG_ 589 SWA_Obj_05_ID 0;
BA_ "GenSigSendType" SG_ 589 SWA_Obj_05_Laenge 0;
BA_ "GenSigStartValue" SG_ 589 SWA_Obj_05_Laenge 127;
BA_ "GenSigSendType" SG_ 589 SWA_Obj_05_Objektklasse 0;
BA_ "GenSigStartValue" SG_ 589 SWA_Obj_05_Objektklasse 15;
BA_ "GenSigSendType" SG_ 589 SWA_Obj_05_PositionX 0;
BA_ "GenSigStartValue" SG_ 589 SWA_Obj_05_PositionX 511;
BA_ "GenSigSendType" SG_ 589 SWA_Obj_05_PositionY 0;
BA_ "GenSigStartValue" SG_ 589 SWA_Obj_05_PositionY 255;
BA_ "GenSigSendType" SG_ 589 SWA_Obj_05_ReferenzPkt 0;
BA_ "GenSigStartValue" SG_ 589 SWA_Obj_05_ReferenzPkt 15;
BA_ "GenSigSendType" SG_ 589 SWA_Obj_06_Breite 0;
BA_ "GenSigStartValue" SG_ 589 SWA_Obj_06_Breite 127;
BA_ "GenSigSendType" SG_ 589 SWA_Obj_06_Existenzwahrsch 0;
BA_ "GenSigStartValue" SG_ 589 SWA_Obj_06_Existenzwahrsch 127;
BA_ "GenSigSendType" SG_ 589 SWA_Obj_06_Gemessen 0;
BA_ "GenSigSendType" SG_ 589 SWA_Obj_06_GeschwRelX 0;
BA_ "GenSigStartValue" SG_ 589 SWA_Obj_06_GeschwRelX 511;
BA_ "GenSigSendType" SG_ 589 SWA_Obj_06_GeschwRelY 0;
BA_ "GenSigStartValue" SG_ 589 SWA_Obj_06_GeschwRelY 511;
BA_ "GenSigSendType" SG_ 589 SWA_Obj_06_ID 0;
BA_ "GenSigStartValue" SG_ 589 SWA_Obj_06_ID 31;
BA_ "GenSigSwitchedByIgnition" SG_ 589 SWA_Obj_06_ID 0;
BA_ "GenSigSendType" SG_ 589 SWA_Obj_06_Laenge 0;
BA_ "GenSigStartValue" SG_ 589 SWA_Obj_06_Laenge 127;
BA_ "GenSigSendType" SG_ 589 SWA_Obj_06_Objektklasse 0;
BA_ "GenSigStartValue" SG_ 589 SWA_Obj_06_Objektklasse 15;
BA_ "GenSigSendType" SG_ 589 SWA_Obj_06_PositionX 0;
BA_ "GenSigStartValue" SG_ 589 SWA_Obj_06_PositionX 511;
BA_ "GenSigSendType" SG_ 589 SWA_Obj_06_PositionY 0;
BA_ "GenSigStartValue" SG_ 589 SWA_Obj_06_PositionY 255;
BA_ "GenSigSendType" SG_ 589 SWA_Obj_06_ReferenzPkt 0;
BA_ "GenSigStartValue" SG_ 589 SWA_Obj_06_ReferenzPkt 15;
BA_ "GenSigSendType" SG_ 589 SWA_Obj_Kurvenradius 0;
BA_ "GenSigStartValue" SG_ 589 SWA_Obj_Kurvenradius 65535;
BA_ "GenSigSendType" SG_ 589 SWA_StrukturLinks_querAbstand 0;
BA_ "GenSigStartValue" SG_ 589 SWA_StrukturLinks_querAbstand 511;
BA_ "GenSigSendType" SG_ 589 SWA_StrukturLinks_Typ 0;
BA_ "GenSigSendType" SG_ 589 SWA_StrukturRechts_querAbstand 0;
BA_ "GenSigStartValue" SG_ 589 SWA_StrukturRechts_querAbstand 511;
BA_ "GenSigSendType" SG_ 589 SWA_StrukturRechts_Typ 0;
BA_ "GenSigSendType" SG_ 589 SWA_Umfeld_Zeitstempel 0;
BA_ "GenSigStartValue" SG_ 589 SWA_Umfeld_Zeitstempel 65535;
BA_ "GenSigSendType" SG_ 589 SWA_Umfeld_Zeitstempel_Status 0;
BA_ "GenSigStartValue" SG_ 589 SWA_Umfeld_Zeitstempel_Status 7;
BA_ "GenSigSendType" SG_ 589 SWA_Warnung_SWA_li 0;
BA_ "GenSigSendType" SG_ 589 SWA_Warnung_SWA_re 0;
BA_ "GenSigSendType" SG_ 2331595854 HR_IFA_Geschw_Faktor_li 0;
BA_ "GenSigStartValue" SG_ 2331595854 HR_IFA_Geschw_Faktor_li 126;
BA_ "Fehlerwert" SG_ 2331595854 HR_IFA_Geschw_Faktor_li 127;
BA_ "GenSigSendType" SG_ 2331595854 HR_IFA_Geschw_Faktor_re 0;
BA_ "GenSigStartValue" SG_ 2331595854 HR_IFA_Geschw_Faktor_re 126;
BA_ "Fehlerwert" SG_ 2331595854 HR_IFA_Geschw_Faktor_re 127;
BA_ "GenSigSendType" SG_ 2331595854 HR_IFA_Modus_li 0;
BA_ "GenSigSendType" SG_ 2331595854 HR_IFA_Modus_re 0;
BA_ "GenSigSendType" SG_ 1609 HUD_Aktiv 0;
BA_ "GenSigSwitchedByIgnition" SG_ 1609 HUD_Aktiv 0;
BA_ "GenSigSendType" SG_ 1609 HUD_Anzeigefehler_NV 0;
BA_ "GenSigSendType" SG_ 1609 HUD_FAS_Anzeige_Kombi 3;
BA_ "GenSigSwitchedByIgnition" SG_ 1609 HUD_FAS_Anzeige_Kombi 0;
BA_ "GenSigSendType" SG_ 1609 HUD_KDK_Anzeige_Kombi 3;
BA_ "GenSigSwitchedByIgnition" SG_ 1609 HUD_KDK_Anzeige_Kombi 0;
BA_ "GenSigSendType" SG_ 1609 HUD_MFL_RQ 3;
BA_ "GenSigSwitchedByIgnition" SG_ 1609 HUD_MFL_RQ 0;
BA_ "GenSigSendType" SG_ 1609 HUD_NV_in_Anzeige 3;
BA_ "GenSigSwitchedByIgnition" SG_ 1609 HUD_NV_in_Anzeige 0;
BA_ "GenSigSendType" SG_ 1609 HUD_PEA_Anzeige_Kombi 3;
BA_ "GenSigSwitchedByIgnition" SG_ 1609 HUD_PEA_Anzeige_Kombi 0;
BA_ "GenSigSendType" SG_ 1609 HUD_VZE_AIO_Anzeige_Kombi 3;
BA_ "GenSigSwitchedByIgnition" SG_ 1609 HUD_VZE_AIO_Anzeige_Kombi 0;
BA_ "GenSigSendType" SG_ 1609 HUD_VZE_in_Anzeige 3;
BA_ "GenSigSendType" SG_ 1452 HVEM_Energie_Klima_Vorgabe 0;
BA_ "GenSigStartValue" SG_ 1452 HVEM_Energie_Klima_Vorgabe 254;
BA_ "GenSigSwitchedByIgnition" SG_ 1452 HVEM_Energie_Klima_Vorgabe 0;
BA_ "Fehlerwert" SG_ 1452 HVEM_Energie_Klima_Vorgabe 255;
BA_ "GenSigSendType" SG_ 1452 HVEM_Energie_Klima_Vorgabe_HighR 0;
BA_ "GenSigStartValue" SG_ 1452 HVEM_Energie_Klima_Vorgabe_HighR 6;
BA_ "GenSigSwitchedByIgnition" SG_ 1452 HVEM_Energie_Klima_Vorgabe_HighR 0;
BA_ "Fehlerwert" SG_ 1452 HVEM_Energie_Klima_Vorgabe_HighR 7;
BA_ "GenSigSendType" SG_ 1452 HVEM_HV_Anf 0;
BA_ "GenSigSwitchedByIgnition" SG_ 1452 HVEM_HV_Anf 0;
BA_ "GenSigSendType" SG_ 1452 HVEM_HVK_Aktivitaet 0;
BA_ "GenSigStartValue" SG_ 1452 HVEM_HVK_Aktivitaet 2;
BA_ "GenSigSwitchedByIgnition" SG_ 1452 HVEM_HVK_Aktivitaet 0;
BA_ "GenSigSendType" SG_ 1452 HVEM_IstLeistungNA 0;
BA_ "GenSigStartValue" SG_ 1452 HVEM_IstLeistungNA 510;
BA_ "GenSigSwitchedByIgnition" SG_ 1452 HVEM_IstLeistungNA 0;
BA_ "Fehlerwert" SG_ 1452 HVEM_IstLeistungNA 511;
BA_ "GenSigSendType" SG_ 1452 HVEM_IstStrom_HVVerbraucher 0;
BA_ "GenSigStartValue" SG_ 1452 HVEM_IstStrom_HVVerbraucher 4094;
BA_ "GenSigSwitchedByIgnition" SG_ 1452 HVEM_IstStrom_HVVerbraucher 0;
BA_ "Fehlerwert" SG_ 1452 HVEM_IstStrom_HVVerbraucher 4095;
BA_ "GenSigSendType" SG_ 1452 HVEM_Leistung_Klima_Vorgabe 0;
BA_ "GenSigStartValue" SG_ 1452 HVEM_Leistung_Klima_Vorgabe 254;
BA_ "GenSigSwitchedByIgnition" SG_ 1452 HVEM_Leistung_Klima_Vorgabe 0;
BA_ "Fehlerwert" SG_ 1452 HVEM_Leistung_Klima_Vorgabe 255;
BA_ "GenSigSendType" SG_ 1452 HVEM_MO_MaxLeistungIgnoriert 0;
BA_ "GenSigSwitchedByIgnition" SG_ 1452 HVEM_MO_MaxLeistungIgnoriert 0;
BA_ "GenSigSendType" SG_ 1452 HVEM_Nutzbare_Energie 0;
BA_ "GenSigStartValue" SG_ 1452 HVEM_Nutzbare_Energie 2046;
BA_ "GenSigSwitchedByIgnition" SG_ 1452 HVEM_Nutzbare_Energie 0;
BA_ "Fehlerwert" SG_ 1452 HVEM_Nutzbare_Energie 2047;
BA_ "GenSigSendType" SG_ 1452 HVEM_NVEM_Leistungsvorgabe 0;
BA_ "GenSigStartValue" SG_ 1452 HVEM_NVEM_Leistungsvorgabe 126;
BA_ "GenSigSwitchedByIgnition" SG_ 1452 HVEM_NVEM_Leistungsvorgabe 0;
BA_ "Fehlerwert" SG_ 1452 HVEM_NVEM_Leistungsvorgabe 127;
BA_ "GenSigSendType" SG_ 1452 HVEM_Pruefpuls_Anf 0;
BA_ "GenSigStartValue" SG_ 1452 HVEM_Pruefpuls_Anf 3;
BA_ "GenSigSwitchedByIgnition" SG_ 1452 HVEM_Pruefpuls_Anf 0;
BA_ "GenSigSendType" SG_ 1283 HV_Bordnetz_aktiv 3;
BA_ "GenSigSwitchedByIgnition" SG_ 1283 HV_Bordnetz_aktiv 0;
BA_ "GenSigSendType" SG_ 1283 HV_Bordnetz_Fehler 3;
BA_ "GenSigSwitchedByIgnition" SG_ 1283 HV_Bordnetz_Fehler 0;
BA_ "Fehlerwert" SG_ 1283 HV_Bordnetz_Fehler 1;
BA_ "GenSigSendType" SG_ 1283 HVK_01_BZ 0;
BA_ "GenSigFuncType" SG_ 1283 HVK_01_BZ 1;
BA_ "GenSigSwitchedByIgnition" SG_ 1283 HVK_01_BZ 0;
BA_ "GenSigSendType" SG_ 1283 HVK_01_CRC 0;
BA_ "GenSigFuncType" SG_ 1283 HVK_01_CRC 2;
BA_ "GenSigSwitchedByIgnition" SG_ 1283 HVK_01_CRC 0;
BA_ "GenSigSendType" SG_ 1283 HVK_AktiveEntladung_Anf 3;
BA_ "GenSigSwitchedByIgnition" SG_ 1283 HVK_AktiveEntladung_Anf 0;
BA_ "GenSigSendType" SG_ 1283 HVK_BMS_Sollmodus 3;
BA_ "GenSigStartValue" SG_ 1283 HVK_BMS_Sollmodus 7;
BA_ "GenSigSwitchedByIgnition" SG_ 1283 HVK_BMS_Sollmodus 0;
BA_ "GenSigSendType" SG_ 1283 HVK_DCDC_Sollmodus 3;
BA_ "GenSigStartValue" SG_ 1283 HVK_DCDC_Sollmodus 7;
BA_ "GenSigSwitchedByIgnition" SG_ 1283 HVK_DCDC_Sollmodus 0;
BA_ "GenSigSendType" SG_ 1283 HVK_EKK_Sollmodus 3;
BA_ "GenSigStartValue" SG_ 1283 HVK_EKK_Sollmodus 7;
BA_ "GenSigSwitchedByIgnition" SG_ 1283 HVK_EKK_Sollmodus 0;
BA_ "GenSigSendType" SG_ 1283 HVK_Gesamtst_Spgfreiheit 0;
BA_ "GenSigSwitchedByIgnition" SG_ 1283 HVK_Gesamtst_Spgfreiheit 0;
BA_ "Fehlerwert" SG_ 1283 HVK_Gesamtst_Spgfreiheit 3;
BA_ "GenSigSendType" SG_ 1283 HVK_HV_Netz_Warnungen 3;
BA_ "GenSigSwitchedByIgnition" SG_ 1283 HVK_HV_Netz_Warnungen 0;
BA_ "GenSigSendType" SG_ 1283 HVK_HVEM_Freigabe 3;
BA_ "GenSigStartValue" SG_ 1283 HVK_HVEM_Freigabe 2;
BA_ "GenSigSwitchedByIgnition" SG_ 1283 HVK_HVEM_Freigabe 0;
BA_ "GenSigSendType" SG_ 1283 HVK_HVLM_Sollmodus 3;
BA_ "GenSigStartValue" SG_ 1283 HVK_HVLM_Sollmodus 7;
BA_ "GenSigSwitchedByIgnition" SG_ 1283 HVK_HVLM_Sollmodus 0;
BA_ "GenSigSendType" SG_ 1283 HVK_HVPTC_Sollmodus 3;
BA_ "GenSigStartValue" SG_ 1283 HVK_HVPTC_Sollmodus 7;
BA_ "GenSigSwitchedByIgnition" SG_ 1283 HVK_HVPTC_Sollmodus 0;
BA_ "GenSigSendType" SG_ 1283 HVK_Iso_Messung_Start 0;
BA_ "GenSigSwitchedByIgnition" SG_ 1283 HVK_Iso_Messung_Start 0;
BA_ "GenSigSendType" SG_ 1283 HVK_Istmodus_Anf 3;
BA_ "GenSigSwitchedByIgnition" SG_ 1283 HVK_Istmodus_Anf 0;
BA_ "GenSigSendType" SG_ 1283 HVK_Ladebereit 3;
BA_ "GenSigSwitchedByIgnition" SG_ 1283 HVK_Ladebereit 0;
BA_ "GenSigSendType" SG_ 1283 HVK_Notabschaltung_Anf 3;
BA_ "GenSigSwitchedByIgnition" SG_ 1283 HVK_Notabschaltung_Anf 0;
BA_ "GenSigSendType" SG_ 1283 HVK_PPulsFreigabe 0;
BA_ "GenSigStartValue" SG_ 1283 HVK_PPulsFreigabe 3;
BA_ "GenSigSwitchedByIgnition" SG_ 1283 HVK_PPulsFreigabe 0;
BA_ "GenSigSendType" SG_ 1283 HVK_TN1_Sollmodus 3;
BA_ "GenSigStartValue" SG_ 1283 HVK_TN1_Sollmodus 3;
BA_ "GenSigSwitchedByIgnition" SG_ 1283 HVK_TN1_Sollmodus 0;
BA_ "GenSigSendType" SG_ 1283 HVK_Vorladung_aktiv 3;
BA_ "GenSigSwitchedByIgnition" SG_ 1283 HVK_Vorladung_aktiv 0;
BA_ "GenSigSendType" SG_ 1428 HVLM_Anzeigetexte 0;
BA_ "GenSigSwitchedByIgnition" SG_ 1428 HVLM_Anzeigetexte 0;
BA_ "Fehlerwert" SG_ 1428 HVLM_Anzeigetexte 7;
BA_ "GenSigSendType" SG_ 1428 HVLM_Bat_Konditionierung_Anf 0;
BA_ "GenSigSwitchedByIgnition" SG_ 1428 HVLM_Bat_Konditionierung_Anf 0;
BA_ "GenSigSendType" SG_ 1428 HVLM_Bat_laden_aktiv 0;
BA_ "GenSigSwitchedByIgnition" SG_ 1428 HVLM_Bat_laden_aktiv 0;
BA_ "GenSigSendType" SG_ 1428 HVLM_Fehler_Ladestecker 0;
BA_ "GenSigSwitchedByIgnition" SG_ 1428 HVLM_Fehler_Ladestecker 0;
BA_ "Fehlerwert" SG_ 1428 HVLM_Fehler_Ladestecker 1;
BA_ "GenSigSendType" SG_ 1428 HVLM_Fehler_Verriegelung 0;
BA_ "GenSigSwitchedByIgnition" SG_ 1428 HVLM_Fehler_Verriegelung 0;
BA_ "Fehlerwert" SG_ 1428 HVLM_Fehler_Verriegelung 1;
BA_ "GenSigSendType" SG_ 1428 HVLM_FSH_Anf 0;
BA_ "GenSigSwitchedByIgnition" SG_ 1428 HVLM_FSH_Anf 0;
BA_ "GenSigSendType" SG_ 1428 HVLM_HSH_Anf 0;
BA_ "GenSigSwitchedByIgnition" SG_ 1428 HVLM_HSH_Anf 0;
BA_ "GenSigSendType" SG_ 1428 HVLM_HV_Anf 3;
BA_ "GenSigSwitchedByIgnition" SG_ 1428 HVLM_HV_Anf 0;
BA_ "GenSigSendType" SG_ 1428 HVLM_HVEM_MaxLeistung 0;
BA_ "GenSigStartValue" SG_ 1428 HVLM_HVEM_MaxLeistung 510;
BA_ "GenSigSwitchedByIgnition" SG_ 1428 HVLM_HVEM_MaxLeistung 0;
BA_ "Fehlerwert" SG_ 1428 HVLM_HVEM_MaxLeistung 511;
BA_ "GenSigSendType" SG_ 1428 HVLM_Klima_Temp 0;
BA_ "GenSigStartValue" SG_ 1428 HVLM_Klima_Temp 30;
BA_ "GenSigSwitchedByIgnition" SG_ 1428 HVLM_Klima_Temp 0;
BA_ "Fehlerwert" SG_ 1428 HVLM_Klima_Temp 31;
BA_ "GenSigSendType" SG_ 1428 HVLM_Ladeart 0;
BA_ "GenSigSwitchedByIgnition" SG_ 1428 HVLM_Ladeart 0;
BA_ "GenSigSendType" SG_ 1428 HVLM_Lademodus_HV_Bat 0;
BA_ "GenSigSwitchedByIgnition" SG_ 1428 HVLM_Lademodus_HV_Bat 0;
BA_ "GenSigSendType" SG_ 1428 HVLM_Ladesystemhinweise 0;
BA_ "GenSigSwitchedByIgnition" SG_ 1428 HVLM_Ladesystemhinweise 0;
BA_ "GenSigSendType" SG_ 1428 HVLM_Langzeit_Laden 0;
BA_ "GenSigSwitchedByIgnition" SG_ 1428 HVLM_Langzeit_Laden 0;
BA_ "Fehlerwert" SG_ 1428 HVLM_Langzeit_Laden 3;
BA_ "GenSigSendType" SG_ 1428 HVLM_Restladezeit_HV_Bat_02 0;
BA_ "GenSigStartValue" SG_ 1428 HVLM_Restladezeit_HV_Bat_02 510;
BA_ "GenSigSwitchedByIgnition" SG_ 1428 HVLM_Restladezeit_HV_Bat_02 0;
BA_ "Fehlerwert" SG_ 1428 HVLM_Restladezeit_HV_Bat_02 511;
BA_ "GenSigSendType" SG_ 1428 HVLM_Standklima_Timer_Status 3;
BA_ "GenSigSwitchedByIgnition" SG_ 1428 HVLM_Standklima_Timer_Status 0;
BA_ "GenSigSendType" SG_ 1428 HVLM_Status_Netz 0;
BA_ "GenSigSwitchedByIgnition" SG_ 1428 HVLM_Status_Netz 0;
BA_ "GenSigSendType" SG_ 1428 HVLM_Stecker_Status 0;
BA_ "GenSigSwitchedByIgnition" SG_ 1428 HVLM_Stecker_Status 0;
BA_ "GenSigSendType" SG_ 1428 HVLM_VK_Anf 0;
BA_ "GenSigSwitchedByIgnition" SG_ 1428 HVLM_VK_Anf 0;
BA_ "GenSigSendType" SG_ 1428 HVLM_VK_Modus 0;
BA_ "GenSigSwitchedByIgnition" SG_ 1428 HVLM_VK_Modus 0;
BA_ "Fehlerwert" SG_ 1428 HVLM_VK_Modus 3;
BA_ "GenSigSendType" SG_ 1428 HVLM_VK_STH_Einsatz 0;
BA_ "GenSigStartValue" SG_ 1428 HVLM_VK_STH_Einsatz 6;
BA_ "GenSigSwitchedByIgnition" SG_ 1428 HVLM_VK_STH_Einsatz 0;
BA_ "Fehlerwert" SG_ 1428 HVLM_VK_STH_Einsatz 7;
BA_ "GenSigSendType" SG_ 1428 HVLM_Warnmeldungen 3;
BA_ "GenSigSwitchedByIgnition" SG_ 1428 HVLM_Warnmeldungen 0;
BA_ "GenSigSwitchedByIgnition" SG_ 27 WFS_IMMO_ELV_CRC 0;
BA_ "GenSigSwitchedByIgnition" SG_ 27 WFS_IMMO_ELV_RND 0;
BA_ "GenSigSendType" SG_ 2583720728 Info_El_AuthTime_Req_Data 3;
BA_ "GenSigFuncType" SG_ 2583720728 Info_El_AuthTime_Req_Data 9;
BA_ "GenSigSwitchedByIgnition" SG_ 2583720728 Info_El_AuthTime_Req_Data 0;
BA_ "GenSigSendType" SG_ 2583851800 Info_El_AuthTime_Resp_Data 3;
BA_ "GenSigFuncType" SG_ 2583851800 Info_El_AuthTime_Resp_Data 9;
BA_ "GenSigSwitchedByIgnition" SG_ 2583851800 Info_El_AuthTime_Resp_Data 0;
BA_ "GenSigSendType" SG_ 1524 AMB_Charisma_FahrPr 3;
BA_ "GenSigSwitchedByIgnition" SG_ 1524 AMB_Charisma_FahrPr 0;
BA_ "GenSigSendType" SG_ 1524 AMB_Charisma_Status 3;
BA_ "GenSigSwitchedByIgnition" SG_ 1524 AMB_Charisma_Status 0;
BA_ "GenSigSendType" SG_ 1524 BCM1_DI_Rampe_Innenlicht 3;
BA_ "GenSigSwitchedByIgnition" SG_ 1524 BCM1_DI_Rampe_Innenlicht 0;
BA_ "GenSigSendType" SG_ 1524 BCM1_DI_Rampe_Leselicht 3;
BA_ "GenSigSwitchedByIgnition" SG_ 1524 BCM1_DI_Rampe_Leselicht 0;
BA_ "GenSigSendType" SG_ 1524 BCM1_Innenlicht_gedimmt_H 3;
BA_ "GenSigSwitchedByIgnition" SG_ 1524 BCM1_Innenlicht_gedimmt_H 0;
BA_ "GenSigSendType" SG_ 1524 BCM1_Innenlicht_gedimmt_V 3;
BA_ "GenSigSwitchedByIgnition" SG_ 1524 BCM1_Innenlicht_gedimmt_V 0;
BA_ "GenSigSendType" SG_ 1524 BCM1_Innenlicht_H 3;
BA_ "GenSigSwitchedByIgnition" SG_ 1524 BCM1_Innenlicht_H 0;
BA_ "GenSigSendType" SG_ 1524 BCM1_Innenlicht_V 3;
BA_ "GenSigSwitchedByIgnition" SG_ 1524 BCM1_Innenlicht_V 0;
BA_ "GenSigSendType" SG_ 1524 BCM1_Leselicht_Anf_hl 3;
BA_ "GenSigSwitchedByIgnition" SG_ 1524 BCM1_Leselicht_Anf_hl 0;
BA_ "GenSigSendType" SG_ 1524 BCM1_Leselicht_Anf_hr 3;
BA_ "GenSigSwitchedByIgnition" SG_ 1524 BCM1_Leselicht_Anf_hr 0;
BA_ "GenSigSendType" SG_ 1524 BCM1_Leselicht_Anf_vl 3;
BA_ "GenSigSwitchedByIgnition" SG_ 1524 BCM1_Leselicht_Anf_vl 0;
BA_ "GenSigSendType" SG_ 1524 BCM1_Leselicht_Anf_vr 3;
BA_ "GenSigSwitchedByIgnition" SG_ 1524 BCM1_Leselicht_Anf_vr 0;
BA_ "GenSigSendType" SG_ 1524 BCM1_Leuchten_Aus 3;
BA_ "GenSigSwitchedByIgnition" SG_ 1524 BCM1_Leuchten_Aus 0;
BA_ "GenSigSendType" SG_ 1524 IL_Bel_BFS_Ausstieg 3;
BA_ "GenSigSwitchedByIgnition" SG_ 1524 IL_Bel_BFS_Ausstieg 0;
BA_ "GenSigSendType" SG_ 1524 IL_Bel_FS_Ausstieg 3;
BA_ "GenSigSwitchedByIgnition" SG_ 1524 IL_Bel_FS_Ausstieg 0;
BA_ "GenSigSendType" SG_ 1524 IL_Bel_HBFS_Ausstieg 3;
BA_ "GenSigSwitchedByIgnition" SG_ 1524 IL_Bel_HBFS_Ausstieg 0;
BA_ "GenSigSendType" SG_ 1524 IL_Bel_HFS_Ausstieg 3;
BA_ "GenSigSwitchedByIgnition" SG_ 1524 IL_Bel_HFS_Ausstieg 0;
BA_ "GenSigSendType" SG_ 1524 IL_Dimmung_H_Tuerkontur 3;
BA_ "GenSigSwitchedByIgnition" SG_ 1524 IL_Dimmung_H_Tuerkontur 0;
BA_ "GenSigSendType" SG_ 1524 IL_Dimmung_Lautspr 3;
BA_ "GenSigSwitchedByIgnition" SG_ 1524 IL_Dimmung_Lautspr 0;
BA_ "GenSigSendType" SG_ 1524 IL_Dimmung_Tuerinnengriff 3;
BA_ "GenSigSwitchedByIgnition" SG_ 1524 IL_Dimmung_Tuerinnengriff 0;
BA_ "GenSigSendType" SG_ 1524 IL_Dimmung_Umfeldbel 3;
BA_ "GenSigSwitchedByIgnition" SG_ 1524 IL_Dimmung_Umfeldbel 0;
BA_ "GenSigSendType" SG_ 1524 IL_Dimmung_V_Tuerkontur 3;
BA_ "GenSigSwitchedByIgnition" SG_ 1524 IL_Dimmung_V_Tuerkontur 0;
BA_ "GenSigSendType" SG_ 1524 IL_Innenlicht_aktiv 3;
BA_ "GenSigSwitchedByIgnition" SG_ 1524 IL_Innenlicht_aktiv 0;
BA_ "GenSigSendType" SG_ 1524 IL_Klemme_30G_aktiv 3;
BA_ "GenSigSwitchedByIgnition" SG_ 1524 IL_Klemme_30G_aktiv 0;
BA_ "GenSigSendType" SG_ 2527679583 IPA_02_BZ 0;
BA_ "GenSigFuncType" SG_ 2527679583 IPA_02_BZ 1;
BA_ "GenSigSwitchedByIgnition" SG_ 2527679583 IPA_02_BZ 0;
BA_ "GenSigSendType" SG_ 2527679583 IPA_02_CRC 0;
BA_ "GenSigFuncType" SG_ 2527679583 IPA_02_CRC 2;
BA_ "GenSigSwitchedByIgnition" SG_ 2527679583 IPA_02_CRC 0;
BA_ "GenSigActiveRepetitions" SG_ 2527679583 IPA_Akustik_PL_gefunden 5;
BA_ "GenSigSendType" SG_ 2527679583 IPA_Akustik_PL_gefunden 4;
BA_ "GenSigActiveRepetitions" SG_ 2527679583 IPA_Anf_Meldungen 5;
BA_ "GenSigSendType" SG_ 2527679583 IPA_Anf_Meldungen 4;
BA_ "GenSigSwitchedByIgnition" SG_ 2527679583 IPA_Anf_Meldungen 0;
BA_ "GenSigActiveRepetitions" SG_ 2527679583 IPA_PL_Anzeige_links 5;
BA_ "GenSigSendType" SG_ 2527679583 IPA_PL_Anzeige_links 4;
BA_ "GenSigActiveRepetitions" SG_ 2527679583 IPA_PL_Anzeige_rechts 5;
BA_ "GenSigSendType" SG_ 2527679583 IPA_PL_Anzeige_rechts 4;
BA_ "GenSigActiveRepetitions" SG_ 2527679583 Parken_aktives_System_02 5;
BA_ "GenSigSendType" SG_ 2527679583 Parken_aktives_System_02 4;
BA_ "GenSigSwitchedByIgnition" SG_ 2527679583 Parken_aktives_System_02 0;
BA_ "GenSigActiveRepetitions" SG_ 2527679583 Parken_Aktivierungslicht_Anf 5;
BA_ "GenSigSendType" SG_ 2527679583 Parken_Aktivierungslicht_Anf 4;
BA_ "GenSigSwitchedByIgnition" SG_ 2527679583 Parken_Aktivierungslicht_Anf 0;
BA_ "GenSigActiveRepetitions" SG_ 2527679583 Parken_Bestaetigungsblinken_Anf 5;
BA_ "GenSigSendType" SG_ 2527679583 Parken_Bestaetigungsblinken_Anf 4;
BA_ "GenSigSwitchedByIgnition" SG_ 2527679583 Parken_Bestaetigungsblinken_Anf 0;
BA_ "GenSigActiveRepetitions" SG_ 2527679583 Parken_Blinker_li_Anf 5;
BA_ "GenSigSendType" SG_ 2527679583 Parken_Blinker_li_Anf 4;
BA_ "GenSigSwitchedByIgnition" SG_ 2527679583 Parken_Blinker_li_Anf 0;
BA_ "GenSigActiveRepetitions" SG_ 2527679583 Parken_Blinker_re_Anf 5;
BA_ "GenSigSendType" SG_ 2527679583 Parken_Blinker_re_Anf 4;
BA_ "GenSigSwitchedByIgnition" SG_ 2527679583 Parken_Blinker_re_Anf 0;
BA_ "GenSigActiveRepetitions" SG_ 2527679583 Parken_Fahrbereitschaftlicht_Anf 5;
BA_ "GenSigSendType" SG_ 2527679583 Parken_Fahrbereitschaftlicht_Anf 4;
BA_ "GenSigActiveRepetitions" SG_ 2527679583 Parken_Fahrerhinweise_Anf 5;
BA_ "GenSigSendType" SG_ 2527679583 Parken_Fahrerhinweise_Anf 4;
BA_ "GenSigSwitchedByIgnition" SG_ 2527679583 Parken_Fahrerhinweise_Anf 0;
BA_ "GenSigActiveRepetitions" SG_ 2527679583 Parken_Fahrtrichtungslicht_Anf 5;
BA_ "GenSigSendType" SG_ 2527679583 Parken_Fahrtrichtungslicht_Anf 4;
BA_ "GenSigActiveRepetitions" SG_ 2527679583 Parken_FFB_LED_Anf 5;
BA_ "GenSigSendType" SG_ 2527679583 Parken_FFB_LED_Anf 4;
BA_ "GenSigActiveRepetitions" SG_ 2527679583 Parken_Lichtnachlauf_Anf 5;
BA_ "GenSigSendType" SG_ 2527679583 Parken_Lichtnachlauf_Anf 4;
BA_ "GenSigActiveRepetitions" SG_ 2527679583 Parken_Lichtsteuerung_Anf 5;
BA_ "GenSigSendType" SG_ 2527679583 Parken_Lichtsteuerung_Anf 4;
BA_ "GenSigSwitchedByIgnition" SG_ 2527679583 Parken_Lichtsteuerung_Anf 0;
BA_ "GenSigActiveRepetitions" SG_ 2527679583 Parken_Schluesselsuche_Anf 5;
BA_ "GenSigSendType" SG_ 2527679583 Parken_Schluesselsuche_Anf 4;
BA_ "GenSigActiveRepetitions" SG_ 2527679583 Parken_Seitenspiegel_Anf 5;
BA_ "GenSigSendType" SG_ 2527679583 Parken_Seitenspiegel_Anf 4;
BA_ "GenSigActiveRepetitions" SG_ 2527679583 Parken_Wegfahrsperren_Anf 5;
BA_ "GenSigSendType" SG_ 2527679583 Parken_Wegfahrsperren_Anf 4;
BA_ "GenSigActiveRepetitions" SG_ 2527679583 Parken_ZR_Sondermodus_Anf 5;
BA_ "GenSigSendType" SG_ 2527679583 Parken_ZR_Sondermodus_Anf 4;
BA_ "GenSigSwitchedByIgnition" SG_ 2527679583 Parken_ZR_Sondermodus_Anf 0;
BA_ "GenSigActiveRepetitions" SG_ 2527679583 Parken_ZV_Schliessen 5;
BA_ "GenSigSendType" SG_ 2527679583 Parken_ZV_Schliessen 4;
BA_ "GenSigSendType" SG_ 1841 ISO_ELV_Req_Data 3;
BA_ "GenSigFuncType" SG_ 1841 ISO_ELV_Req_Data 9;
BA_ "GenSigSwitchedByIgnition" SG_ 1841 ISO_ELV_Req_Data 0;
BA_ "GenSigSendType" SG_ 1947 ISO_ELV_Resp_Data 3;
BA_ "GenSigFuncType" SG_ 1947 ISO_ELV_Resp_Data 9;
BA_ "GenSigSwitchedByIgnition" SG_ 1947 ISO_ELV_Resp_Data 0;
BA_ "GenSigSendType" SG_ 1792 ISO_ALL_01_Req_Data 3;
BA_ "GenSigFuncType" SG_ 1792 ISO_ALL_01_Req_Data 9;
BA_ "GenSigSwitchedByIgnition" SG_ 1792 ISO_ALL_01_Req_Data 0;
BA_ "GenSigSendType" SG_ 1819 ISO_HUD_Req_Data 3;
BA_ "GenSigFuncType" SG_ 1819 ISO_HUD_Req_Data 9;
BA_ "GenSigSwitchedByIgnition" SG_ 1819 ISO_HUD_Req_Data 0;
BA_ "GenSigSendType" SG_ 1925 ISO_HUD_Resp_Data 3;
BA_ "GenSigFuncType" SG_ 1925 ISO_HUD_Resp_Data 9;
BA_ "GenSigSwitchedByIgnition" SG_ 1925 ISO_HUD_Resp_Data 0;
BA_ "GenSigSendType" SG_ 1812 ISO_Kombi_Req_Data 3;
BA_ "GenSigFuncType" SG_ 1812 ISO_Kombi_Req_Data 9;
BA_ "GenSigSwitchedByIgnition" SG_ 1812 ISO_Kombi_Req_Data 0;
BA_ "GenSigSendType" SG_ 1918 ISO_Kombi_Resp_Data 3;
BA_ "GenSigFuncType" SG_ 1918 ISO_Kombi_Resp_Data 9;
BA_ "GenSigSwitchedByIgnition" SG_ 1918 ISO_Kombi_Resp_Data 0;
BA_ "GenSigSendType" SG_ 1836 ISO_MFG_Req_Data 3;
BA_ "GenSigFuncType" SG_ 1836 ISO_MFG_Req_Data 9;
BA_ "GenSigSwitchedByIgnition" SG_ 1836 ISO_MFG_Req_Data 0;
BA_ "GenSigSendType" SG_ 1942 ISO_MFG_Resp_Data 3;
BA_ "GenSigFuncType" SG_ 1942 ISO_MFG_Resp_Data 9;
BA_ "GenSigSwitchedByIgnition" SG_ 1942 ISO_MFG_Resp_Data 0;
BA_ "GenSigSendType" SG_ 1839 ISO_SFA_Req_Data 3;
BA_ "GenSigFuncType" SG_ 1839 ISO_SFA_Req_Data 9;
BA_ "GenSigSwitchedByIgnition" SG_ 1839 ISO_SFA_Req_Data 0;
BA_ "GenSigSendType" SG_ 1945 ISO_SFA_Resp_Data 3;
BA_ "GenSigFuncType" SG_ 1945 ISO_SFA_Resp_Data 9;
BA_ "GenSigSwitchedByIgnition" SG_ 1945 ISO_SFA_Resp_Data 0;
BA_ "GenSigSendType" SG_ 1905 ISO_TCO_Req_Data 3;
BA_ "GenSigFuncType" SG_ 1905 ISO_TCO_Req_Data 9;
BA_ "GenSigSwitchedByIgnition" SG_ 1905 ISO_TCO_Req_Data 0;
BA_ "GenSigSendType" SG_ 2011 ISO_TCO_Resp_Data 3;
BA_ "GenSigFuncType" SG_ 2011 ISO_TCO_Resp_Data 9;
BA_ "GenSigSwitchedByIgnition" SG_ 2011 ISO_TCO_Resp_Data 0;
BA_ "GenSigSendType" SG_ 2549874849 ISOx_Bedienteil_Req_Data 3;
BA_ "GenSigFuncType" SG_ 2549874849 ISOx_Bedienteil_Req_Data 9;
BA_ "GenSigSwitchedByIgnition" SG_ 2549874849 ISOx_Bedienteil_Req_Data 0;
BA_ "GenSigSendType" SG_ 2550005921 ISOx_Bedienteil_Resp_Data 3;
BA_ "GenSigFuncType" SG_ 2550005921 ISOx_Bedienteil_Resp_Data 9;
BA_ "GenSigSwitchedByIgnition" SG_ 2550005921 ISOx_Bedienteil_Resp_Data 0;
BA_ "GenSigSendType" SG_ 2621440049 ISOx_ELV_Req_FD_Data 3;
BA_ "GenSigFuncType" SG_ 2621440049 ISOx_ELV_Req_FD_Data 9;
BA_ "GenSigSwitchedByIgnition" SG_ 2621440049 ISOx_ELV_Req_FD_Data 0;
BA_ "GenSigSendType" SG_ 2621571121 ISOx_ELV_Resp_FD_Data 3;
BA_ "GenSigFuncType" SG_ 2621571121 ISOx_ELV_Resp_FD_Data 9;
BA_ "GenSigSwitchedByIgnition" SG_ 2621571121 ISOx_ELV_Resp_FD_Data 0;
BA_ "GenSigSendType" SG_ 2621505536 ISOx_Funkt_Req_All_FD_Data 3;
BA_ "GenSigFuncType" SG_ 2621505536 ISOx_Funkt_Req_All_FD_Data 9;
BA_ "GenSigSwitchedByIgnition" SG_ 2621505536 ISOx_Funkt_Req_All_FD_Data 0;
BA_ "GenSigSendType" SG_ 2621440027 ISOx_HUD_Req_FD_Data 3;
BA_ "GenSigFuncType" SG_ 2621440027 ISOx_HUD_Req_FD_Data 9;
BA_ "GenSigSwitchedByIgnition" SG_ 2621440027 ISOx_HUD_Req_FD_Data 0;
BA_ "GenSigSendType" SG_ 2621571099 ISOx_HUD_Resp_FD_Data 3;
BA_ "GenSigFuncType" SG_ 2621571099 ISOx_HUD_Resp_FD_Data 9;
BA_ "GenSigSwitchedByIgnition" SG_ 2621571099 ISOx_HUD_Resp_FD_Data 0;
BA_ "GenSigSendType" SG_ 2621440020 ISOx_Kombi_Req_FD_Data 3;
BA_ "GenSigFuncType" SG_ 2621440020 ISOx_Kombi_Req_FD_Data 9;
BA_ "GenSigSwitchedByIgnition" SG_ 2621440020 ISOx_Kombi_Req_FD_Data 0;
BA_ "GenSigSendType" SG_ 2621571092 ISOx_Kombi_Resp_FD_Data 3;
BA_ "GenSigFuncType" SG_ 2621571092 ISOx_Kombi_Resp_FD_Data 9;
BA_ "GenSigSwitchedByIgnition" SG_ 2621571092 ISOx_Kombi_Resp_FD_Data 0;
BA_ "GenSigSendType" SG_ 2549874852 ISOx_LSH_Req_Data 3;
BA_ "GenSigFuncType" SG_ 2549874852 ISOx_LSH_Req_Data 9;
BA_ "GenSigSwitchedByIgnition" SG_ 2549874852 ISOx_LSH_Req_Data 0;
BA_ "GenSigSendType" SG_ 2550005924 ISOx_LSH_Resp_Data 3;
BA_ "GenSigFuncType" SG_ 2550005924 ISOx_LSH_Resp_Data 9;
BA_ "GenSigSwitchedByIgnition" SG_ 2550005924 ISOx_LSH_Resp_Data 0;
BA_ "GenSigSendType" SG_ 2621440044 ISOx_MFG_Req_FD_Data 3;
BA_ "GenSigFuncType" SG_ 2621440044 ISOx_MFG_Req_FD_Data 9;
BA_ "GenSigSwitchedByIgnition" SG_ 2621440044 ISOx_MFG_Req_FD_Data 0;
BA_ "GenSigSendType" SG_ 2621571116 ISOx_MFG_Resp_FD_Data 3;
BA_ "GenSigFuncType" SG_ 2621571116 ISOx_MFG_Resp_FD_Data 9;
BA_ "GenSigSwitchedByIgnition" SG_ 2621571116 ISOx_MFG_Resp_FD_Data 0;
BA_ "GenSigSendType" SG_ 2621440113 ISOx_TCO_Req_FD_Data 3;
BA_ "GenSigFuncType" SG_ 2621440113 ISOx_TCO_Req_FD_Data 9;
BA_ "GenSigSwitchedByIgnition" SG_ 2621440113 ISOx_TCO_Req_FD_Data 0;
BA_ "GenSigSendType" SG_ 2621571185 ISOx_TCO_Resp_FD_Data 3;
BA_ "GenSigFuncType" SG_ 2621571185 ISOx_TCO_Resp_FD_Data 9;
BA_ "GenSigSwitchedByIgnition" SG_ 2621571185 ISOx_TCO_Resp_FD_Data 0;
BA_ "GenSigSendType" SG_ 2550398990 ISOx_TRE_2_Req_Data 3;
BA_ "GenSigFuncType" SG_ 2550398990 ISOx_TRE_2_Req_Data 9;
BA_ "GenSigSwitchedByIgnition" SG_ 2550398990 ISOx_TRE_2_Req_Data 0;
BA_ "GenSigSendType" SG_ 2550530062 ISOx_TRE_2_Resp_Data 3;
BA_ "GenSigFuncType" SG_ 2550530062 ISOx_TRE_2_Resp_Data 9;
BA_ "GenSigSwitchedByIgnition" SG_ 2550530062 ISOx_TRE_2_Resp_Data 0;
BA_REL_ "GenSigTimeoutTime" BU_SG_REL_ ELV SG_ 173 GE_Fahrstufe 500;
BA_REL_ "GenSigTimeoutTime" BU_SG_REL_ HUD SG_ 299 GRA_Tip_Setzen 500;
BA_REL_ "GenSigTimeoutTime" BU_SG_REL_ HUD SG_ 299 GRA_Tip_Hoch 500;
BA_REL_ "GenSigTimeoutTime" BU_SG_REL_ HUD SG_ 299 GRA_Tip_Runter 500;
BA_REL_ "GenSigTimeoutTime" BU_SG_REL_ HUD SG_ 299 GRA_Tip_Wiederaufnahme 500;
BA_REL_ "GenSigTimeoutTime" BU_SG_REL_ HUD SG_ 588 ASW_Ton_Richtung_HL 500;
BA_REL_ "GenSigTimeoutTime" BU_SG_REL_ HUD SG_ 588 ASW_Ton_Richtung_HR 500;
BA_REL_ "GenSigTimeoutTime" BU_SG_REL_ HUD SG_ 588 HRE_Anzeigetexte 500;
BA_REL_ "GenSigTimeoutTime" BU_SG_REL_ HUD SG_ 2527679583 IPA_PL_Anzeige_links 5000;
BA_REL_ "GenSigTimeoutTime" BU_SG_REL_ HUD SG_ 2527679583 IPA_PL_Anzeige_rechts 5000;
BA_REL_ "GenSigTimeoutTime" BU_SG_REL_ Kombi SG_ 988 ESP_07_alt 500;
BA_REL_ "GenSigTimeoutTime" BU_SG_REL_ Kombi SG_ 988 TSK_06_alt 500;
BA_REL_ "GenSigTimeoutTime" BU_SG_REL_ Kombi SG_ 988 TSK_Hauptschalter_GRA_ACC 500;
BA_REL_ "GenSigTimeoutTime" BU_SG_REL_ Kombi SG_ 988 ESP_Rollenmodus_Deaktivieren 500;
BA_REL_ "GenSigTimeoutTime" BU_SG_REL_ Kombi SG_ 1002 Getriebe_14_alt 2000;
BA_REL_ "GenSigTimeoutTime" BU_SG_REL_ Kombi SG_ 1002 GE_Sumpftemperatur 2000;
BA_REL_ "GenSigTimeoutTime" BU_SG_REL_ Kombi SG_ 1003 EFF_Verbrauch_STH 1000;
BA_REL_ "GenSigTimeoutTime" BU_SG_REL_ Kombi SG_ 884 GNSS_Ortung_2D_Geschw_ue_Grund 5000;
BA_REL_ "GenSigTimeoutTime" BU_SG_REL_ Kombi SG_ 886 GNSS_Ortung_Guete_Geschwindigk 5000;
BA_REL_ "GenSigTimeoutTime" BU_SG_REL_ Kombi SG_ 891 GNSS_UTC_Zeit 5000;
BA_REL_ "GenSigTimeoutTime" BU_SG_REL_ Kombi SG_ 891 GNSS_Nachrichtenpaket_ID5 5000;
BA_REL_ "GenSigTimeoutTime" BU_SG_REL_ Kombi SG_ 1343 GNSS_Nachrichtenpaket_ID7 5000;
BA_REL_ "GenSigTimeoutTime" BU_SG_REL_ Kombi SG_ 1343 GNSS_V_Geschw_2D 5000;
BA_REL_ "GenSigTimeoutTime" BU_SG_REL_ Kombi SG_ 1343 GNSS_V_Geschw_2D_Guete95 5000;
BA_REL_ "GenSigTimeoutTime" BU_SG_REL_ Kombi SG_ 1343 GNSS_V_Geschw_Vertikal 5000;
BA_REL_ "GenSigTimeoutTime" BU_SG_REL_ Kombi SG_ 1343 GNSS_V_Geschw_Vertikal_Guete95 5000;
BA_REL_ "GenSigTimeoutTime" BU_SG_REL_ Kombi SG_ 1343 GNSS_V_FIX_Typ 5000;
BA_REL_ "GenSigTimeoutTime" BU_SG_REL_ Kombi SG_ 1343 GNSS_V_Latenz_vollstaendig 5000;
BA_REL_ "GenSigTimeoutTime" BU_SG_REL_ Kombi SG_ 1343 GNSS_V_Daten_Veraltet 5000;
BA_REL_ "GenSigTimeoutTime" BU_SG_REL_ Kombi SG_ 588 SWA_Status_KuFu 500;
BA_REL_ "GenSigTimeoutTime" BU_SG_REL_ Kombi SG_ 588 SWA_Anzeigen 500;
BA_REL_ "GenSigTimeoutTime" BU_SG_REL_ Kombi SG_ 588 SWA_Sta_aktiv 500;
BA_REL_ "GenSigTimeoutTime" BU_SG_REL_ Kombi SG_ 588 SWA_Sta_passiv 500;
BA_REL_ "GenSigTimeoutTime" BU_SG_REL_ Kombi SG_ 588 ASW_Kombitexte 500;
BA_REL_ "GenSigTimeoutTime" BU_SG_REL_ Kombi SG_ 588 HRE_Anzeigetexte 500;
BA_REL_ "GenSigTimeoutTime" BU_SG_REL_ Kombi SG_ 588 Heckradar_Kombitexte 500;
BA_REL_ "GenSigTimeoutTime" BU_SG_REL_ Kombi SG_ 588 RCTA_Kombitexte 500;
BA_REL_ "GenSigTimeoutTime" BU_SG_REL_ Kombi SG_ 589 SWA_Infostufe_SWA_li 500;
BA_REL_ "GenSigTimeoutTime" BU_SG_REL_ Kombi SG_ 589 SWA_Infostufe_SWA_re 500;
BA_REL_ "GenSigTimeoutTime" BU_SG_REL_ Kombi SG_ 589 SWA_Warnung_SWA_li 500;
BA_REL_ "GenSigTimeoutTime" BU_SG_REL_ Kombi SG_ 589 SWA_Warnung_SWA_re 500;
BA_REL_ "GenSigTimeoutTime" BU_SG_REL_ Kombi SG_ 2331595854 HR_IFA_Geschw_Faktor_li 500;
BA_REL_ "GenSigTimeoutTime" BU_SG_REL_ Kombi SG_ 2331595854 HR_IFA_Geschw_Faktor_re 500;
BA_REL_ "GenSigTimeoutTime" BU_SG_REL_ Kombi SG_ 2331595854 HR_IFA_Modus_li 500;
BA_REL_ "GenSigTimeoutTime" BU_SG_REL_ Kombi SG_ 2331595854 HR_IFA_Modus_re 500;
BA_REL_ "GenSigTimeoutTime" BU_SG_REL_ Kombi SG_ 1609 HUD_MFL_RQ 5000;
BA_REL_ "GenSigTimeoutTime" BU_SG_REL_ Kombi SG_ 1283 HVK_HV_Netz_Warnungen 1000;
BA_REL_ "GenSigTimeoutTime" BU_SG_REL_ Kombi SG_ 1283 HVK_Gesamtst_Spgfreiheit 1000;
BA_REL_ "GenSigTimeoutTime" BU_SG_REL_ Kombi SG_ 1428 HVLM_Warnmeldungen 5000;
BA_REL_ "GenSigTimeoutTime" BU_SG_REL_ Kombi SG_ 1428 HVLM_Restladezeit_HV_Bat_02 5000;
BA_REL_ "GenSigTimeoutTime" BU_SG_REL_ Kombi SG_ 1428 HVLM_Anzeigetexte 5000;
BA_REL_ "GenSigTimeoutTime" BU_SG_REL_ Kombi SG_ 1428 HVLM_Bat_laden_aktiv 5000;
BA_REL_ "GenSigTimeoutTime" BU_SG_REL_ Kombi SG_ 1428 HVLM_Ladeart 5000;
BA_REL_ "GenSigTimeoutTime" BU_SG_REL_ Kombi SG_ 1428 HVLM_Stecker_Status 5000;
BA_REL_ "GenSigTimeoutTime" BU_SG_REL_ Kombi SG_ 2527679583 IPA_PL_Anzeige_links 5000;
BA_REL_ "GenSigTimeoutTime" BU_SG_REL_ Kombi SG_ 2527679583 IPA_PL_Anzeige_rechts 5000;
BA_REL_ "GenSigTimeoutTime" BU_SG_REL_ Kombi SG_ 2527679583 Parken_aktives_System_02 5000;
BA_REL_ "GenSigTimeoutTime" BU_SG_REL_ Kombi SG_ 2527679583 IPA_Akustik_PL_gefunden 5000;
BA_REL_ "GenSigTimeoutTime" BU_SG_REL_ Kombi SG_ 2527679583 IPA_Anf_Meldungen 5000;
VAL_ 988 Motor_12_alt 0 "aktuell" 1 "veraltet" ;
VAL_ 988 ESP_07_alt 0 "aktuell" 1 "veraltet" ;
VAL_ 988 Getriebe_11_alt 0 "aktuell" 1 "veraltet" ;
VAL_ 988 Getriebe_13_alt 0 "aktuell" 1 "veraltet" ;
VAL_ 988 Getriebe_17_alt 0 "aktuell" 1 "veraltet" ;
VAL_ 988 TSK_06_alt 0 "aktuell" 1 "veraltet" ;
VAL_ 988 Getriebe_14_alt 0 "aktuell" 1 "veraltet" ;
VAL_ 988 ESP_50_alt 0 "aktuell" 1 "veraltet" ;
VAL_ 988 MO_QBit_Drehzahl_01 0 "gueltiger_Wert" 1 "Ersatz_Init_oder_Fehlerwert" ;
VAL_ 988 MKE_Texte 0 "keine_Anzeige" 1 "Warnstufe_1" 2 "Warnstufe_2" ;
VAL_ 988 MKE_Stufe 0 "deaktiviert" 1 "nicht_verfügbar" 2 "Stufe_1" 3 "Stufe_2" 4 "Stufe_3" 5 "Stufe_4" 6 "reserviert" 7 "reserviert" ;
VAL_ 988 TSK_Hauptschalter_GRA_ACC 0 "Init" 1 "Aus" 2 "Ein" 3 "Fehler" ;
VAL_ 988 TSK_Status 0 "Hauptschalter_aus" 1 "Init" 2 "passiv" 3 "aktiv" 4 "Uebertreten" 5 "brake_only_Mode" 6 "reversibel_aus" 7 "irreversibel_aus" ;
VAL_ 988 EPB_Schalterposition 0 "keine Fahreranforderung" 1 "Fahreranforderung Öffnen" 2 "Fahreranforderung Schließen" 3 "Fehler" ;
VAL_ 988 GE_LaunchControl 0 "inaktiv" 1 "aktiv" ;
VAL_ 988 GE_Fahrstufe 0 "Zwischenstellung" 1 "Init" 5 "Position_P" 6 "Position_R" 7 "Position_N" 8 "Position_D" 9 "Position_S" 10 "Effizienz" 13 "Tipp_in_S" 14 "Tipp_in_D" 15 "Fehler" ;
VAL_ 988 GE_Ursache_Fahrstufe_N 0 "Fahrstufe_N_mit_Fahrerwunsch" 1 "Fahrstufe_N_ohne_Fahrerwunsch" ;
VAL_ 988 GE_Notlauf 0 "kein Notlauf / Init" 1 "Getriebe im Notlauf" ;
VAL_ 988 ESP_Rollenmodus_Deaktivieren 0 "keine_Aenderung" 1 "Abbruch" ;
VAL_ 988 GE_Freilauf_Status 0 "Freilauf_inaktiv_aber_moeglich" 1 "Freilauf_aktiv" 2 "Freilauf_nicht_moegl_1Verhinderer" 3 "Freilauf_nicht_moegl_gr_1Verhinderer" 7 "Fehler" ;
VAL_ 988 GE_Sperr_Info_WFS 0 "nicht_gesperrt" 1 "gesperrt" ;
VAL_ 988 TSK_Limiter_ausgewaehlt 0 "kein_Limiter_ausgewaehlt" 1 "Limiter_ausgewaehlt" ;
VAL_ 988 GE_Veto_Rollfaehigkeit 0 "kein_Veto__Rollfaehigkeit_moegl" 1 "Veto__Rollfaehigkeit_nicht_moegl" ;
VAL_ 988 EPB_Status_02 0 "offen" 1 "geschlossen_Parken" 2 "teilgespannt_Halten" 3 "im_Lauf_oeffnen" 4 "im_Lauf_schliessen" 5 "tbd" 6 "Init" 7 "unbekannt" ;
VAL_ 988 ACC_Status_ACC 0 "ACC_OFF_Hauptschalter_aus" 1 "ACC_INIT" 2 "ACC_STANDBY" 3 "ACC_AKTIV_regelt" 4 "ACC_OVERRIDE" 5 "ACC_Abschaltreaktion" 6 "reversibler_Fehler_im_ACC_System" 7 "irreversibler_Fehler_im_ACC_System" ;
VAL_ 988 ACC_18_alt 0 "aktuell" 1 "veraltet" ;
VAL_ 988 Bel_DiETa_Mode2 0 "LED_Aus" 1 "LED_Ein" 2 "LED_blinken" 3 "Fehler" ;
VAL_ 1002 ESP_05_alt 0 "aktuell" 1 "veraltet" ;
VAL_ 1002 Getriebe_14_alt 0 "aktuell" 1 "veraltet" ;
VAL_ 1002 Motor_11_alt 0 "aktuell" 1 "veraltet" ;
VAL_ 1002 Motor_20_alt 0 "aktuell" 1 "veraltet" ;
VAL_ 1002 EBKV_03_alt 0 "aktuell" 1 "veraltet" ;
VAL_ 1002 AWV_03_alt 0 "aktuell" 1 "veraltet" ;
VAL_ 1002 AWV_Verz_Freigabe 0 "Verzoegerung_nicht_freigeben" 1 "Verzoegerung_freigeben" ;
VAL_ 1002 AWV_Verz_Anf 1023 "keine_Anforderung" ;
VAL_ 1002 Bel_DiETa_Mode 0 "LED_Aus" 1 "LED_Ein" 2 "LED_blinken" 3 "Fehler" ;
VAL_ 1002 PaCo_DiETa_LED 0 "LED_Inactive" 1 "LED_Active" 2 "LED_Flashing" 3 "Error" ;
VAL_ 1002 RTM_Warnstatus 0 "keine_Warnung" 1 "Warnstufe_ChNational" 2 "reserviert" 3 "reserviert" ;
VAL_ 1002 EBKV_Fahrer_bremst 0 "Fahrer_bremst_nicht_selbst" 1 "Fahrer_will_selbst_bremsen" ;
VAL_ 1002 AWV_Zielobjekttyp 0 "Unbekannt" 1 "Fussgaenger" 2 "Zweirad" 3 "PKW" 4 "LKW" 5 "reserviert" 6 "reserviert" 7 "reserviert" 8 "reserviert" 9 "reserviert" 10 "reserviert" 11 "reserviert" 12 "reserviert" 13 "reserviert" 14 "kein_relevantes_Obj" 15 "init" ;
VAL_ 1002 ESP_Bremsdruck 1023 "Fehler" ;
VAL_ 1002 MO_Mom_Ist_Summe 1022 "Init" ;
VAL_ 1002 MO_Fahrpedalrohwert_01 255 "Fehler" ;
VAL_ 1002 GE_Sumpftemperatur 255 "Fehler" ;
VAL_ 1003 LH_EPS_02_alt 0 "aktuell" 1 "veraltet" ;
VAL_ 1003 LIN_2_alt 0 "aktuell" 1 "veraltet" ;
VAL_ 1003 Parkhilfe_01_alt 0 "aktuell" 1 "veraltet" ;
VAL_ 1003 Motor_20_alt 0 "aktuell" 1 "veraltet" ;
VAL_ 1003 LR_HZG_01_alt 0 "aktuell" 1 "veraltet" ;
VAL_ 1003 Areaview_01_alt 0 "aktuell" 1 "veraltet" ;
VAL_ 1003 EBKV_03_alt 0 "aktuell" 1 "veraltet" ;
VAL_ 1003 ESP_50_alt 0 "aktuell" 1 "veraltet" ;
VAL_ 1003 EPS_Lastinfo 254 "Init" 255 "Fehler" ;
VAL_ 1003 EFF_Verbrauch_STH 127 "Fehler" ;
VAL_ 1003 LR_HZG_Taster_on_off 0 "nicht_betaetigt" 1 "betaetigt" ;
VAL_ 1003 LR_HZG_Temp_Sensor 253 "KS_Plus__Unterbrechung" 254 "Init" 255 "Tempsensor_fehlerhaft__KS_GND" ;
VAL_ 1003 MFL_Signalhorn 0 "nicht_betaetigt" 1 "betaetigt" ;
VAL_ 1003 EBKV_Fahrer_bremst 0 "Fahrer_bremst_nicht_selbst" 1 "Fahrer_will_selbst_bremsen" ;
VAL_ 1003 PH_Stoermeldung 0 "keine_Anzeige_kein_Gong" 1 "Textmeldung_PDC_hinten_gestoert_mit_Gong" 2 "Textmeldung_PDC_hinten_gestoert_ohne_Gong" 3 "Textmeldung_PDC_vorn_gestoert_mit_Gong" 4 "Textmeldung_PDC_vorn_gestoert_ohne_Gong" 5 "Textmeldung_PDC_gestoert_mit_Gong" 6 "Textmeldung_PDC_gestoert_ohne_Gong" 7 "Textmeldung_PDC_seitlich_gestoert_mit_Gong" 8 "Textmeldung_PDC_seitlich_gestoert_ohne_Gong" ;
VAL_ 1003 MO_temporaere_Fahrerabwesenheit 0 "nicht_erkannt" 1 "erkannt" ;
VAL_ 1003 AV_Umfeldbeleuchtung_Anf 0 "nicht_angefordert" 1 "angefordert" ;
VAL_ 1003 MO_Fahrpedalrohwert_01 255 "Fehler" ;
VAL_ 1003 LR_HZG_Konfiguration 0 "Init" 1 "Parametersatz_1" 2 "Parametersatz_2" 3 "Parametersatz_3" 4 "Parametersatz_4" 5 "Parametersatz_5" 6 "Parametersatz_6" 7 "Parametersatz_7" ;
VAL_ 1003 EBKV_QBit_Fahrer_bremst 0 "gueltiger_Wert" 1 "Ersatz_Init_oder_Fehlerwert" ;
VAL_ 1003 MO_QBit_Fahrpedalwerte_01 0 "gueltiger_Wert" 1 "Ersatz_Init_oder_Fehlerwert" ;
VAL_ 1003 ESP_QBit_Bremsdruck 0 "gueltiger_Wert" 1 "Ersatz_Init_oder_Fehlerwert" ;
VAL_ 1003 ESP_Bremsdruck 1023 "Fehler" ;
VAL_ 173 GE_Fahrstufe 0 "Zwischenstellung" 1 "Init" 5 "Position_P" 6 "Position_R" 7 "Position_N" 8 "Position_D" 9 "Position_S" 10 "Effizienz" 13 "Tipp_in_S" 14 "Tipp_in_D" 15 "Fehler" ;
VAL_ 173 GE_Ursache_Fahrstufe_N 0 "Fahrstufe_N_mit_Fahrerwunsch" 1 "Fahrstufe_N_ohne_Fahrerwunsch" ;
VAL_ 884 GNSS_Ortung_Latenz 1022 "Init" 1023 "Fehler" ;
VAL_ 884 GNSS_Ortung_Ausrichtung 4094 "Init" 4095 "Fehler" ;
VAL_ 884 GNSS_Ortung_2D_Geschw_ue_Grund 510 "Init" 511 "Fehler" ;
VAL_ 884 GNSS_Ortung_Noerdliche_Geschw 1022 "Init" 1023 "Fehler" ;
VAL_ 884 GNSS_Ortung_Oestliche_Geschw 1022 "Init" 1023 "Fehler" ;
VAL_ 884 GNSS_Ortung_Vertikale_Geschw 1022 "Init" 1023 "Fehler" ;
VAL_ 886 GNSS_Ortung_GDOP 510 "Init" 511 "Fehler" ;
VAL_ 886 GNSS_Ortung_PDOP 510 "Init" 511 "Fehler" ;
VAL_ 886 GNSS_Ortung_HDOP 510 "Init" 511 "Fehler" ;
VAL_ 886 GNSS_Ortung_VDOP 510 "Init" 511 "Fehler" ;
VAL_ 886 GNSS_Ortung_Guete_Geschwindigk 62 "Init" 63 "Fehler" ;
VAL_ 886 GNSS_Ortung_Guete_Ausrichtung 62 "Init" 63 "Fehler" ;
VAL_ 886 GNSS_Ortung_Guete_horizontal 254 "Init" 255 "Fehler" ;
VAL_ 886 GNSS_Ortung_Guete_vertikal 62 "Init" 63 "Fehler" ;
VAL_ 891 GNSS_UTC_Zeit 0 "Init" ;
VAL_ 891 GNSS_Empfaenger_Status 0 "Backup_Mode" 1 "Live" ;
VAL_ 891 GNSS_GPS_in_Nutzung 0 "unbenutzt" 1 "benutzt" ;
VAL_ 891 GNSS_GLONASS_in_Nutzung 0 "unbenutzt" 1 "benutzt" ;
VAL_ 891 GNSS_Empfangbare_Satelliten 0 "Init" 31 "31_oder_mehr" ;
VAL_ 891 GNSS_Sichtbare_Satelliten 0 "Init" 31 "31_oder_mehr" ;
VAL_ 891 GNSS_Genutzte_Satelliten 0 "Init" 31 "31_oder_mehr" ;
VAL_ 1343 GNSS_V_Geschw_2D 16381 "hoeher_als_163" 16382 "Init" 16383 "Fehler" ;
VAL_ 1343 GNSS_V_Geschw_2D_Guete95 1022 "Init" 1023 "Fehler" ;
VAL_ 1343 GNSS_V_Geschw_Vertikal 32764 "hoeher_als_163" 32765 "kleiner_als_minus_163" 32766 "Init" 32767 "Fehler" ;
VAL_ 1343 GNSS_V_Geschw_Vertikal_Guete95 1022 "Init" 1023 "Fehler" ;
VAL_ 1343 GNSS_V_FIX_Typ 0 "Init" 1 "No_Fix" 2 "2D_Fix" 3 "3D_Fix" ;
VAL_ 1343 GNSS_V_Latenz_vollstaendig 1022 "Init" 1023 "Fehler" ;
VAL_ 1343 GNSS_V_Daten_Veraltet 0 "Veraltet" 1 "Neu" ;
VAL_ 299 GRA_Hauptschalter 0 "Aus_Taster_nicht_betaetigt" 1 "Ein_Taster_betaetigt" ;
VAL_ 299 GRA_Abbrechen 0 "nicht_betaetigt" 1 "betaetigt" ;
VAL_ 299 GRA_Typ_Hauptschalter 0 "gerasteter_Lenkstockschalter" 1 "getasteter_Lenkstockschalter" ;
VAL_ 299 GRA_Limiter 0 "nicht_betaetigt" 1 "betaetigt" ;
VAL_ 299 GRA_Tip_Setzen 0 "nicht_betaetigt" 1 "betaetigt" ;
VAL_ 299 GRA_Tip_Hoch 0 "nicht_betaetigt" 1 "betaetigt" ;
VAL_ 299 GRA_Tip_Runter 0 "nicht_betaetigt" 1 "betaetigt" ;
VAL_ 299 GRA_Tip_Wiederaufnahme 0 "nicht_betaetigt" 1 "betaetigt" ;
VAL_ 299 GRA_Verstellung_Zeitluecke 0 "Taste_nicht_betaetigt" 1 "Dist_minus_1" 2 "Dist_plus_1" 3 "Dist_Toggle" ;
VAL_ 299 GRA_Codierung 0 "kein_Hebel" 1 "GRA_Hebel" 2 "ACC_Hebel" 3 "Limiter_Only" ;
VAL_ 299 GRA_Fehler 0 "kein_Fehler" 1 "Fehler" ;
VAL_ 299 GRA_LIM_Taste_verfuegbar 0 "Limiter_Taste_nicht_vorhanden" 1 "Limiter_Taste_vorhanden" ;
VAL_ 299 GRA_Tip_Stufe_2 0 "Tip_Stufe_1_keine_Betaetigung" 1 "Tip_Stufe_2" ;
VAL_ 299 GRA_Typ_Bedienteil 0 "Init" 1 "4_Positions_Bedienteil" 2 "6_Positions_Bedienteil" 3 "8_Positions_Bedienteil" 4 "PAG_5_Positions_Bedienteil" 5 "VW_MFL_Gen2" 6 "VW_MFL_Gen3" 7 "PAG_DX1_Bedienteil" ;
VAL_ 299 GRA_TravelAssist 0 "nicht_betaetigt" 1 "betaetigt" ;
VAL_ 299 GRA_PIT_Limiter 0 "nicht_betaetigt" 1 "betaetigt" ;
VAL_ 1410 HD_Endstellung_oben 1 "HD in Endstellung oben (offen)" ;
VAL_ 1410 HD_Endstellung_unten 0 "Init" 1 "HD in Endstellung unten (geschlossen)" ;
VAL_ 1410 HD_Bewegung_auf 0 "Init" 1 "HD in Bewegung auf" ;
VAL_ 1410 HD_Bewegung_zu 0 "Init" 1 "HD in Bewegung zu" ;
VAL_ 1410 HD_Innentaster_betaetigt 0 "HD_Innentaster_nicht_betaetigt" 1 "HD_Innentaster_betaetigt" ;
VAL_ 1410 HD_Kupp_Ma_aktiv 1 "Kupplung 1 ein" ;
VAL_ 1410 HD_Kupp_Sl_aktiv 1 "Kupplung 2 aktiv" ;
VAL_ 1410 HD_UeKB_erkannt 0 "Init" 1 "Einklemmschutz aktiv" ;
VAL_ 1410 HD_SG_MA_KD_Fehler 0 "SG_funktionsfaehig" 1 "SG_defekt" ;
VAL_ 1410 HD_SG_SL_KD_Fehler 0 "SG_funktionsfaehig" 1 "SG_defekt" ;
VAL_ 1410 HD_Taster_defekt 0 "Taster_funktionsfähig" 1 "Taster defekt" ;
VAL_ 1410 HD_Rueckmeld_prog 0 "keine Rueckmeldung" 1 "Rueckmeldung zur Programmierung Endstellung aktiv" ;
VAL_ 1410 HD_Verriegelungstaster_betaetigt 0 "Taster_nicht_betaetigt" 1 "Taster_betaetigt" ;
VAL_ 1410 HD_Verr_Taster_betaetigt_inv 0 "Taster_betaetigt" 1 "Taster_nicht_betaetigt" ;
VAL_ 1410 HD_ZZH_Schalter_S3 0 "nicht_betaetigt" 1 "betaetigt" ;
VAL_ 1410 HDSG_Anf_Umluftklappe 0 "aus" 1 "an" ;
VAL_ 588 SWA_LED_Hell_BFS 126 "Init" 127 "Fehler" ;
VAL_ 588 SWA_LED_Hell_FS 126 "Init" 127 "Fehler" ;
VAL_ 588 SWA_LED_Ausgabemodus_BFS 0 "LED_aus" 1 "Infostufe" 2 "Warnstufe" 3 "Aufpruefen_SWAABAHeck_ASW" 4 "Aufpruefen_SWAABAHeck" 5 "Demolauf" ;
VAL_ 588 SWA_LED_Ausgabemodus_FS 0 "LED_aus" 1 "Infostufe" 2 "Warnstufe" 3 "Aufpruefen_SWAABAHeck_ASW" 4 "Aufpruefen_SWAABAHeck" 5 "Demolauf" ;
VAL_ 588 SWA_Status 0 "aus" 1 "passiv" 2 "aktiv" 3 "Fehler" ;
VAL_ 588 ASW_Ton_Richtung_VL 0 "kein_Warnton" 1 "Warnton" ;
VAL_ 588 ASW_Ton_Richtung_VR 0 "kein_Warnton" 1 "Warnton" ;
VAL_ 588 ASW_Ton_Richtung_HL 0 "kein_Warnton" 1 "Warnton" ;
VAL_ 588 ASW_Ton_Richtung_HR 0 "kein_Warnton" 1 "Warnton" ;
VAL_ 588 SWA_Status_System 0 "aus" 1 "passiv" 2 "aktiv" 3 "Fehler" ;
VAL_ 588 SWA_Brightness_Mode_FPM 0 "Init" 1 "No_error" 2 "Trailer_active" 3 "Muted_by_driver" 4 "Blind" 5 "not_selectable" 6 "not_available" 7 "Privacy_Mode" 8 "No_License" 9 "License_expired" 14 "Temporary_error" 15 "Fehler" ;
VAL_ 588 SWA_Status_KuFu 0 "aus" 1 "passiv" 2 "aktiv" 3 "Fehler" ;
VAL_ 588 SWA_Infostufe_Assist_li 0 "keine_Infostufe" 1 "Infostufe_aktiv" ;
VAL_ 588 SWA_Infostufe_Assist_re 0 "keine_Infostufe" 1 "Infostufe_aktiv" ;
VAL_ 588 SWA_Warnstufe_Assist_li 0 "keine_Warnstufe" 1 "Warnstufe_aktiv" ;
VAL_ 588 SWA_Warnstufe_Assist_re 0 "keine_Warnstufe" 1 "Warnstufe_aktiv" ;
VAL_ 588 SWA_Modus_System 0 "nicht_verfuegbar" 1 "verfuegbar" 2 "Anhaengerbetrieb" 3 "eingeschraenkte_Sensorsicht" 4 "keine_Sensorsicht" 5 "reserved" 6 "temporaerer_Fehler" 7 "dauerhafter_Fehler" ;
VAL_ 588 SWA_Kombiausgabe 0 "Keine_Anzeige" 1 "zur_Zeit_nicht_verfuegbar" 2 "Systemfehler" 3 "Sensor_blockiert" 4 "Anhaengerbetrb_nicht_verfuegbar" 5 "Sensor_teilweise_blockiert" ;
VAL_ 588 ASW_Kombiausgabe 0 "Keine_Anzeige" 1 "zur_Zeit_nicht_verfuegbar" 2 "Systemfehler" 3 "Sensor_blockiert" 4 "Anhaengerbetrb_nicht_verfuegbar" ;
VAL_ 588 SWA_Kombiwarnung 0 "Keine_Warnung" 1 "Akustik_Warnung" ;
VAL_ 588 ASW_Ausgabemodus_HBFS 0 "keine_Ausgabe" 1 "Infostufe" 2 "Infostufe_ohne_Tueraktion" 3 "Warnstufe_ohne_Ton" 4 "Warnstufe_mit_Ton" 5 "Aufpruefen" ;
VAL_ 588 ASW_Ausgabemodus_HFS 0 "keine_Ausgabe" 1 "Infostufe" 2 "Infostufe_ohne_Tueraktion" 3 "Warnstufe_ohne_Ton" 4 "Warnstufe_mit_Ton" 5 "Aufpruefen" ;
VAL_ 588 ASW_Akustik_Einstellung 0 "Aus" 1 "Ein" ;
VAL_ 588 SWA_Anzeigen 0 "keine_Anzeige" 1 "Text_1_SWA_zurzeit_nicht_verfuegbar" 2 "Text_2_SWA_Systemstoerung" 3 "Text_3_SWA_zurzeit_nicht_verfuegbar_Keine_Sensorsicht" 4 "Text_4_SWA_zurzeit_nicht_verfuegbar_Anhaengerbetrieb" 5 "Text_5_SWA_Eskalation" 6 "Text_6_SWA_eingeschränkt" ;
VAL_ 588 SWA_Blindheit_erkannt 0 "nicht erkannt" 1 "erkannt" ;
VAL_ 588 SWA_rel_Nichtverf 0 "verfuegbar" 1 "nicht verfuegbar" ;
VAL_ 588 SWA_rel_Fehler 0 "kein Fehler" 1 "Fehler" ;
VAL_ 588 SWA_Sta_aktiv 0 "Aus" 1 "Ein" ;
VAL_ 588 SWA_Sta_passiv 0 "Aus" 1 "Ein" ;
VAL_ 588 SWA_FT_RueckLED 0 "inaktiv" 1 "aktiv" ;
VAL_ 588 ASW_Status 0 "Passiv" 1 "Aktiv" 2 "Fehler" 3 "AUS" ;
VAL_ 588 SWA_Standziele_li 0 "Abstand i.O." 1 "Abstand zu gering" ;
VAL_ 588 ASW_Ausgabemodus_BFS 0 "keine_Ausgabe" 1 "Infostufe" 2 "Infostufe_ohne_Tueraktion" 3 "Warnstufe_ohne_Ton" 4 "Warnstufe_mit_Ton" 5 "Aufpruefen" ;
VAL_ 588 ASW_Warnung_FS 0 "inaktiv" 1 "aktiv" ;
VAL_ 588 ASW_Warnung_BFS 0 "inaktiv" 1 "aktiv" ;
VAL_ 588 ASW_Kombitexte 0 "keine Anzeige.    //    Prio 5" 1 "Text_1_ASW_zur_Zeit_nicht_verfuegbar_und_Akustik    //    Prio 2" 2 "Text_2_ASW_Systemfehler_und_Akustik    //    Prio 1" 3 "Text_3_ASW_Sensor_blockiert_und_Akustik    //    Prio 3" 4 "Text_4_ASW_im_Anhaengerbetrieb_nicht_verfuegbar_und_Akustik    //    Prio 4" 5 "Text_5_ASW_Warnung_FS_und_Akustik" 6 "Text_6_ASW_Warnung_BFS_und_Akustik" 7 "Text_7_ASW_aus" ;
VAL_ 588 ASW_Modus 0 "kein_Fehler_KL15" 1 "kein_Fehler_KL30" 2 "reserve" 3 "Anhaengerbetrieb" 4 "Init_nicht_codiert" 5 "keine_Sensorsicht_blindheit" 6 "Zur_zeit_nicht_verfuegbar_temp_Fehler" 7 "Systemstoerung_dauer_fehler" ;
VAL_ 588 SWA_Modus 0 "kein_Fehler_verfuegbar" 1 "kein_Fehler_eingeschr_Reichweite" 2 "reserve" 3 "Anhaengerbetrieb" 4 "Init_nicht_codiert" 5 "keine_Sensorsicht_blindheit" 6 "Zur_zeit_nicht_verfuegbar_temp_Fehler" 7 "Systemstoerung_dauer_fehler" ;
VAL_ 588 SWA_Standziele_re 0 "Abstand i.O." 1 "Abstand zu gering" ;
VAL_ 588 ASW_Ausgabemodus_FS 0 "keine_Ausgabe" 1 "Infostufe" 2 "Infostufe_ohne_Tueraktion" 3 "Warnstufe_ohne_Ton" 4 "Warnstufe_mit_Ton" 5 "Aufpruefen" ;
VAL_ 588 HRE_Anzeigetexte 0 "keine_Anzeige" 1 "BSD_RTA_zZt_nicht_verfuegbar" 2 "BSD_RTA_Systemfehler" 3 "BSD_RTA_Sensor_blockiert" 4 "BSD_RTA_Anhaengerbetrieb" 5 "RTA_Warnung" 6 "BSD_Warnung" 7 "Fahreruebernahme_Notbremsung" 8 "RTA_nicht_verfuegbar" 9 "BSD_RTA_ASW_zZt_nicht_verfuegbar" 10 "BSD_RTA_ASW_Systemfehler" 11 "BSD_RTA_ASW_Sensor_blockiert" 12 "BSD_RTA_ASW_Anhaengerbetrieb" ;
VAL_ 588 SWA_Blindheitsverdacht 0 "kein_Blindheitsverdacht_erkannt" 1 "Blindheitsverdacht_erkannt" ;
VAL_ 588 Heckradar_Kombitexte 0 "keine Anzeige.    //    Prio 5" 1 "Text_1_SWA_und_ASW_zur_Zeit_nicht_verfuegbar_und_Akustik    //    Prio 2" 2 "Text_2_SWA_und_ASW_Systemfehler_und_Akustik    //    Prio 1" 3 "Text_3_SWA_und_ASW_Sensor_blockiert_und_Akustik    //    Prio 3" 4 "Text_4_SWA_und_ASW_im_Anhaengerbetrieb_nicht_verfuegbar_und_Akustik    //    Prio 4" 5 "Text_1_SWA_und_RCTA_zur_Zeit_nicht_verfuegbar_und_Akustik // Prio 2" 6 "Text_2_SWA_und_RCTA_Systemfehler_und_Akustik // Prio 1" 7 "		Text_3_SWA_und_RCTA_Sensor_blockiert_und_Akustik // Prio 3" 8 "Text_4_SWA_und_RCTA_im_Anhaengerbetrieb_nicht_verfuegbar_und_Akustik // Prio 4" 9 "Text_1_ASW_und_RCTA_zur_Zeit_nicht_verfuegbar_und_Akustik // Prio 2" 10 "Text_2_ASW_und_RCTA_Systemfehler_und_Akustik // Prio 1" 11 "Text_3_ASW_und_RCTA_Sensor_blockiert_und_Akustik // Prio 3" 12 "Text_4_ASW_und_RCTA_im_Anhaengerbetrieb_nicht_verfuegbar_und_Akustik // Prio 4" 13 "Text_1_SWA_und_ASW_und_RCTA_zur_Zeit_nicht_verfuegbar_und_Akustik // Prio 2" 14 "Text_2_SWA_und_ASW_und_RCTA_Systemfehler_und_Akustik // Prio 1" 15 "Text_3_SWA_und_ASW_und_RCTA_Sensor_blockiert_und_Akustik // Prio 3" 16 "Text_4_SWA_und_ASW_und_RCTA_im_Anhaengerbetrieb_nicht_verfuegbar_und_Akustik // Prio 4" 17 "reserviert" 18 "reserviert" 19 "reserviert" 20 "reserviert" 21 "reserviert" 22 "reserviert" 23 "reserviert" 24 "reserviert" 25 "reserviert" 26 "reserviert" 27 "reserviert" 28 "reserviert" 29 "reserviert" ;
VAL_ 588 RCTA_Kombitexte 0 "keine_Anzeige" 1 "RCTA_zur_Zeit_nicht_verfuegbar" 2 "RCTA_Systemfehler" 3 "RCTA_Sensor_blockiert" 4 "RCTA_im_Anhaengerbetrieb" 5 "RTA_Warnung" 6 "Fahreruebernahme_Notbremsung" 7 "Eingeschraenkt_verfuegbar_ESCaus" ;
VAL_ 589 SWA_StrukturLinks_querAbstand 511 "Init" ;
VAL_ 589 SWA_StrukturLinks_Typ 0 "inaktiv" 1 "durchgehend_baulich" 2 "verkettet_baulich" 3 "unregelmaessig_oder_unbekannt" 4 "punktfoermig" 5 "verdeckt" 6 "frei" ;
VAL_ 589 SWA_Umfeld_Zeitstempel_Status 0 "reserved" 1 "Zeitstempel_PLT_synchro" 2 "Zeitstempel_Datenalter" 3 "reserved" 4 "Fehler_Sync_fehlerhaft" 5 "reserved" 6 "reserved" 7 "init" ;
VAL_ 589 SWA_Kolonne_li 0 "zwei_oder_weniger_Fahrzeuge_auf_der_Spur" 1 "mehr_als_zwei_Fahrzeuge_auf_der_Spur" ;
VAL_ 589 SWA_Kolonne_mi 0 "zwei_oder_weniger_Fahrzeuge_auf_der_Spur" 1 "mehr_als_zwei_Fahrzeuge_auf_der_Spur" ;
VAL_ 589 SWA_Kolonne_re 0 "zwei_oder_weniger_Fahrzeuge_auf_der_Spur" 1 "mehr_als_zwei_Fahrzeuge_auf_der_Spur" ;
VAL_ 589 SWA_Infostufe_SWA_li 0 "keine_Aktion" 1 "Aktion" ;
VAL_ 589 SWA_Infostufe_SWA_re 0 "keine_Aktion" 1 "Aktion" ;
VAL_ 589 SWA_Warnung_SWA_li 0 "keine Warnung" 1 "Warnung aktiv" ;
VAL_ 589 SWA_Warnung_SWA_re 0 "keine Warnung" 1 "Warnung aktiv" ;
VAL_ 589 SWA_Obj_Kurvenradius 65535 "Init" ;
VAL_ 589 SWA_StrukturRechts_querAbstand 511 "Init" ;
VAL_ 589 SWA_StrukturRechts_Typ 0 "inaktiv" 1 "durchgehend_baulich" 2 "verkettet_baulich" 3 "unregelmaessig_oder_unbekannt" 4 "punktfoermig" 5 "verdeckt" 6 "frei" ;
VAL_ 589 SWA_Obj_01_Gemessen 0 "ObjektpositionY_geschaetzt" 1 "ObjektpositionY_bestaetigt" ;
VAL_ 589 SWA_Obj_01_ID 0 "kein_Objekt_enthalten" 31 "Init" ;
VAL_ 589 SWA_Obj_02_Gemessen 0 "ObjektpositionY_geschaetzt" 1 "ObjektpositionY_bestaetigt" ;
VAL_ 589 SWA_Obj_02_ID 0 "kein_Objekt_enthalten" 31 "Init" ;
VAL_ 589 SWA_Obj_03_Gemessen 0 "ObjektpositionY_geschaetzt" 1 "ObjektpositionY_bestaetigt" ;
VAL_ 589 SWA_Obj_03_ID 0 "kein_Objekt_enthalten" 31 "Init" ;
VAL_ 589 SWA_Obj_04_Gemessen 0 "ObjektpositionY_geschaetzt" 1 "ObjektpositionY_bestaetigt" ;
VAL_ 589 SWA_Obj_04_ID 0 "kein_Objekt_enthalten" 31 "Init" ;
VAL_ 589 SWA_Obj_05_Gemessen 0 "ObjektpositionY_geschaetzt" 1 "ObjektpositionY_bestaetigt" ;
VAL_ 589 SWA_Obj_05_ID 0 "kein_Objekt_enthalten" 31 "Init" ;
VAL_ 589 SWA_Obj_06_Gemessen 0 "ObjektpositionY_geschaetzt" 1 "ObjektpositionY_bestaetigt" ;
VAL_ 589 SWA_Obj_06_ID 0 "kein_Objekt_enthalten" 31 "Init" ;
VAL_ 589 SWA_Obj_01_GeschwRelX 511 "Init" ;
VAL_ 589 SWA_Obj_01_Breite 127 "Init" ;
VAL_ 589 SWA_Obj_01_GeschwRelY 511 "Init" ;
VAL_ 589 SWA_Obj_01_Existenzwahrsch 127 "Init" ;
VAL_ 589 SWA_Obj_01_Objektklasse 0 "unbekannt" 1 "dynamisch" 2 "VRU" 3 "Fussgaenger" 4 "Fussgaengergruppe" 5 "Radfahrer" 6 "Motorrad" 7 "PKW" 8 "mindestens_Vierrad" 9 "LKW" 10 "Zweirad" 11 "Tier" 12 "mindestens_Zweirad" 13 "Objektcluster" 15 "Init" ;
VAL_ 589 SWA_Obj_01_ReferenzPkt 0 "unbekannt" 1 "vorne_links" 2 "vorne_mitte" 3 "vorne_rechts" 4 "mitte_rechts" 5 "hinten_rechts" 6 "hinten_mitte" 7 "hinten_links" 8 "mitte_links" 9 "objekt_mitte" 15 "Init" ;
VAL_ 589 SWA_Obj_01_PositionX 511 "Init" ;
VAL_ 589 SWA_Obj_01_Laenge 127 "Init" ;
VAL_ 589 SWA_Obj_01_PositionY 255 "Init" ;
VAL_ 589 SWA_Obj_02_GeschwRelX 511 "Init" ;
VAL_ 589 SWA_Obj_02_Breite 127 "Init" ;
VAL_ 589 SWA_Obj_02_GeschwRelY 511 "Init" ;
VAL_ 589 SWA_Obj_02_Existenzwahrsch 127 "Init" ;
VAL_ 589 SWA_Obj_02_Objektklasse 0 "unbekannt" 1 "dynamisch" 2 "VRU" 3 "Fussgaenger" 4 "Fussgaengergruppe" 5 "Radfahrer" 6 "Motorrad" 7 "PKW" 8 "mindestens_Vierrad" 9 "LKW" 10 "Zweirad" 11 "Tier" 12 "mindestens_Zweirad" 13 "Objektcluster" 15 "Init" ;
VAL_ 589 SWA_Obj_02_ReferenzPkt 0 "unbekannt" 1 "vorne_links" 2 "vorne_mitte" 3 "vorne_rechts" 4 "mitte_rechts" 5 "hinten_rechts" 6 "hinten_mitte" 7 "hinten_links" 8 "mitte_links" 9 "objekt_mitte" 15 "Init" ;
VAL_ 589 SWA_Obj_02_PositionX 511 "Init" ;
VAL_ 589 SWA_Obj_02_Laenge 127 "Init" ;
VAL_ 589 SWA_Obj_02_PositionY 255 "Init" ;
VAL_ 589 SWA_Obj_03_GeschwRelX 511 "Init" ;
VAL_ 589 SWA_Obj_03_Breite 127 "Init" ;
VAL_ 589 SWA_Obj_03_GeschwRelY 511 "Init" ;
VAL_ 589 SWA_Obj_03_Existenzwahrsch 127 "Init" ;
VAL_ 589 SWA_Obj_03_Objektklasse 0 "unbekannt" 1 "dynamisch" 2 "VRU" 3 "Fussgaenger" 4 "Fussgaengergruppe" 5 "Radfahrer" 6 "Motorrad" 7 "PKW" 8 "mindestens_Vierrad" 9 "LKW" 10 "Zweirad" 11 "Tier" 12 "mindestens_Zweirad" 13 "Objektcluster" 15 "Init" ;
VAL_ 589 SWA_Obj_03_ReferenzPkt 0 "unbekannt" 1 "vorne_links" 2 "vorne_mitte" 3 "vorne_rechts" 4 "mitte_rechts" 5 "hinten_rechts" 6 "hinten_mitte" 7 "hinten_links" 8 "mitte_links" 9 "objekt_mitte" 15 "Init" ;
VAL_ 589 SWA_Obj_03_PositionX 511 "Init" ;
VAL_ 589 SWA_Obj_03_Laenge 127 "Init" ;
VAL_ 589 SWA_Obj_03_PositionY 255 "Init" ;
VAL_ 589 SWA_Obj_04_GeschwRelX 511 "Init" ;
VAL_ 589 SWA_Obj_04_Breite 127 "Init" ;
VAL_ 589 SWA_Obj_04_GeschwRelY 511 "Init" ;
VAL_ 589 SWA_Obj_04_Existenzwahrsch 127 "Init" ;
VAL_ 589 SWA_Obj_04_Objektklasse 0 "unbekannt" 1 "dynamisch" 2 "VRU" 3 "Fussgaenger" 4 "Fussgaengergruppe" 5 "Radfahrer" 6 "Motorrad" 7 "PKW" 8 "mindestens_Vierrad" 9 "LKW" 10 "Zweirad" 11 "Tier" 12 "mindestens_Zweirad" 13 "Objektcluster" 15 "Init" ;
VAL_ 589 SWA_Obj_04_ReferenzPkt 0 "unbekannt" 1 "vorne_links" 2 "vorne_mitte" 3 "vorne_rechts" 4 "mitte_rechts" 5 "hinten_rechts" 6 "hinten_mitte" 7 "hinten_links" 8 "mitte_links" 9 "objekt_mitte" 15 "Init" ;
VAL_ 589 SWA_Obj_04_PositionX 511 "Init" ;
VAL_ 589 SWA_Obj_04_Laenge 127 "Init" ;
VAL_ 589 SWA_Obj_04_PositionY 255 "Init" ;
VAL_ 589 SWA_Obj_05_GeschwRelX 511 "Init" ;
VAL_ 589 SWA_Obj_05_Breite 127 "Init" ;
VAL_ 589 SWA_Obj_05_GeschwRelY 511 "Init" ;
VAL_ 589 SWA_Obj_05_Existenzwahrsch 127 "Init" ;
VAL_ 589 SWA_Obj_05_Objektklasse 0 "unbekannt" 1 "dynamisch" 2 "VRU" 3 "Fussgaenger" 4 "Fussgaengergruppe" 5 "Radfahrer" 6 "Motorrad" 7 "PKW" 8 "mindestens_Vierrad" 9 "LKW" 10 "Zweirad" 11 "Tier" 12 "mindestens_Zweirad" 13 "Objektcluster" 15 "Init" ;
VAL_ 589 SWA_Obj_05_ReferenzPkt 0 "unbekannt" 1 "vorne_links" 2 "vorne_mitte" 3 "vorne_rechts" 4 "mitte_rechts" 5 "hinten_rechts" 6 "hinten_mitte" 7 "hinten_links" 8 "mitte_links" 9 "objekt_mitte" 15 "Init" ;
VAL_ 589 SWA_Obj_05_PositionX 511 "Init" ;
VAL_ 589 SWA_Obj_05_Laenge 127 "Init" ;
VAL_ 589 SWA_Obj_05_PositionY 255 "Init" ;
VAL_ 589 SWA_Obj_06_GeschwRelX 511 "Init" ;
VAL_ 589 SWA_Obj_06_Breite 127 "Init" ;
VAL_ 589 SWA_Obj_06_GeschwRelY 511 "Init" ;
VAL_ 589 SWA_Obj_06_Existenzwahrsch 127 "Init" ;
VAL_ 589 SWA_Obj_06_Objektklasse 0 "unbekannt" 1 "dynamisch" 2 "VRU" 3 "Fussgaenger" 4 "Fussgaengergruppe" 5 "Radfahrer" 6 "Motorrad" 7 "PKW" 8 "mindestens_Vierrad" 9 "LKW" 10 "Zweirad" 11 "Tier" 12 "mindestens_Zweirad" 13 "Objektcluster" 15 "Init" ;
VAL_ 589 SWA_Obj_06_ReferenzPkt 0 "unbekannt" 1 "vorne_links" 2 "vorne_mitte" 3 "vorne_rechts" 4 "mitte_rechts" 5 "hinten_rechts" 6 "hinten_mitte" 7 "hinten_links" 8 "mitte_links" 9 "objekt_mitte" 15 "Init" ;
VAL_ 589 SWA_Obj_06_PositionX 511 "Init" ;
VAL_ 589 SWA_Obj_06_Laenge 127 "Init" ;
VAL_ 589 SWA_Obj_06_PositionY 255 "Init" ;
VAL_ 2331595854 HR_IFA_Geschw_Faktor_li 126 "Init" 127 "Fehler" ;
VAL_ 2331595854 HR_IFA_Geschw_Faktor_re 126 "Init" 127 "Fehler" ;
VAL_ 2331595854 HR_IFA_Modus_li 0 "Aus" 1 "Infostufe" 2 "Warnstufe" 3 "reserved" ;
VAL_ 2331595854 HR_IFA_Modus_re 0 "Aus" 1 "Infostufe" 2 "Warnstufe" 3 "reserved" ;
VAL_ 1609 HUD_Aktiv 0 "HUD_aus_Init" 1 "HUD_aktiv" ;
VAL_ 1609 HUD_Anzeigefehler_NV 0 "kein_Fehler" 1 "Anzeigefehler" ;
VAL_ 1609 HUD_NV_in_Anzeige 0 "NV_nicht_in_Anzeige" 1 "NV_in_Anzeige" ;
VAL_ 1609 HUD_VZE_in_Anzeige 0 "VZE_nicht_in_Anzeige" 1 "VZE_in_Anzeige" ;
VAL_ 1609 HUD_FAS_Anzeige_Kombi 0 "Init" 1 "FAS_im_Kombi_Anzeigen" 2 "FAS_im_Kombi_Ausblenden" ;
VAL_ 1609 HUD_KDK_Anzeige_Kombi 0 "Init" 1 "KDK_im_Kombi_Anzeigen" 2 "KDK_im_Kombi_Ausblenden" ;
VAL_ 1609 HUD_PEA_Anzeige_Kombi 0 "Init" 1 "PEA_im_Kombi_Anzeigen" 2 "PEA_im_Kombi_Ausblenden" ;
VAL_ 1609 HUD_VZE_AIO_Anzeige_Kombi 0 "Init" 1 "VZE_AIO_im_Kombi_Anzeigen" 2 "VZE_AIO_im_Kombi_Ausblenden" ;
VAL_ 1609 HUD_MFL_RQ 0 "Init" 1 "Focus_request" 2 "Focus_release" ;
VAL_ 1452 HVEM_IstStrom_HVVerbraucher 4094 "Init" 4095 "Fehler" ;
VAL_ 1452 HVEM_Energie_Klima_Vorgabe_HighR 6 "Init" 7 "Fehler" ;
VAL_ 1452 HVEM_IstLeistungNA 510 "Init" 511 "Fehler" ;
VAL_ 1452 HVEM_Leistung_Klima_Vorgabe 254 "Init" 255 "Fehler" ;
VAL_ 1452 HVEM_Nutzbare_Energie 2045 "Max" 2046 "Init" 2047 "Fehler" ;
VAL_ 1452 HVEM_Energie_Klima_Vorgabe 254 "Init" 255 "Fehler" ;
VAL_ 1452 HVEM_HVK_Aktivitaet 0 "keine_Aktivitaet" 1 "Aktivitaet" 2 "Init" ;
VAL_ 1452 HVEM_Pruefpuls_Anf 0 "Keine_Anforderung" 1 "Anforderung" 2 "Reserved" 3 "Init" ;
VAL_ 1452 HVEM_NVEM_Leistungsvorgabe 126 "Init" 127 "Fehler" ;
VAL_ 1452 HVEM_HV_Anf 0 "keine_Anforderung" 1 "HV_angefordert" ;
VAL_ 1452 HVEM_MO_MaxLeistungIgnoriert 0 "Max_Leistung_nicht_ignoriert" 1 "Max_Leistung_ignoriert" ;
VAL_ 1283 HVK_Istmodus_Anf 0 "nicht_angefordert" 1 "angefordert" ;
VAL_ 1283 HVK_TN1_Sollmodus 0 "HV_Off" 1 "HV_On" 2 "reserviert" 3 "Initialisierung" ;
VAL_ 1283 HVK_Vorladung_aktiv 0 "Vorladung_nicht_aktiv" 1 "Vorladung_aktiv" ;
VAL_ 1283 HVK_BMS_Sollmodus 0 "HV_Off" 1 "HV_On" 3 "AC_Laden_erw" 4 "AC_Laden" 6 "DC_Laden" 7 "Init" ;
VAL_ 1283 HVK_DCDC_Sollmodus 0 "Standby" 1 "HV_On_Vorladen" 2 "Tiefsetzen" 3 "Hochsetzen" 4 "Pruefpuls_12V" 6 "Pruefpuls_DC_Laden" 7 "Initialisierung" ;
VAL_ 1283 HVK_EKK_Sollmodus 0 "Keine_Freigabe" 1 "Freigabe" 2 "Freigabe_ausgesetzt" 7 "Init" ;
VAL_ 1283 HVK_HVPTC_Sollmodus 0 "Keine_Freigabe" 1 "Freigabe" 2 "Freigabe_ausgesetzt" 7 "Init" ;
VAL_ 1283 HVK_HVLM_Sollmodus 0 "keine_Freigabe" 1 "Freigabe_Lademanager" 2 "Vorladung_AC_Pfad" 7 "Init" ;
VAL_ 1283 HVK_HV_Netz_Warnungen 0 "Keine_Warnung" 1 "Warntext_HV_Netz_Anf" 2 "Fehlertext_HV_Netz_Anf" 3 "Warnung_Kein_Wiederstart_moeglich" ;
VAL_ 1283 HV_Bordnetz_aktiv 0 "inaktiv" 1 "aktiv" ;
VAL_ 1283 HV_Bordnetz_Fehler 0 "kein_Fehler" 1 "Fehler" ;
VAL_ 1283 HVK_Gesamtst_Spgfreiheit 0 "Funktion_Init__ohne_Funktion" 1 "HV_System_spannungsfrei" 2 "HV_System_nicht_spannungsfrei" 3 "Fehler" ;
VAL_ 1283 HVK_AktiveEntladung_Anf 0 "nicht_angefordert" 1 "angefordert" ;
VAL_ 1283 HVK_HVEM_Freigabe 0 "keine_Freigabe" 1 "Freigabe" 2 "Init" ;
VAL_ 1283 HVK_Notabschaltung_Anf 0 "keine_Anforderung_Notabschaltung" 1 "Anforderung_Notabschaltung" 2 "Reserve" 3 "Init" ;
VAL_ 1283 HVK_Iso_Messung_Start 0 "keine_Messung" 1 "Messung_HV_Netz_1" 2 "Messung_HV_Netz_2" 4 "deaktiviert" ;
VAL_ 1283 HVK_Ladebereit 0 "Init_oder_nicht_Ladebereit" 1 "AC_Ladebereit" 2 "DC_Ladebereit" 3 "AC_und_DC_Ladebereit" 4 "Induktiv_Ladebereit" 5 "AC_und_Induktiv_Ladebereit" 6 "DC_und_Induktiv_Ladebereit" 7 "AC_DC_und_Induktiv_Ladebereit" ;
VAL_ 1283 HVK_PPulsFreigabe 0 "keine_Freigabe" 1 "Freigabe" 2 "Reserve" 3 "Init" ;
VAL_ 1428 HVLM_Warnmeldungen 0 "keine_Anzeige" 1 "Nachladewarnung_Batterieschutz" 2 "Vollst_Laden_nicht_moeglich" 3 "Ladeverlaengerung_Notladen" 4 "Fehler_Ladedose_Sensor_Temp" 5 "Fehler_Steckerverriegelung" 6 "Fehler_Ladesaeule" 7 "Hinweis_Ladestecker_Temp" 8 "Hinweis_Notentriegeln" 9 "Hinweis_Temperatur_niedrig" 10 "Hinweis_laden_klimatisieren" 11 "Fehler_kein_PnC_verfuegbar_Fzg" 12 "Fehler_kein_PnC_verfuegbar_LS" 13 "reserve" 14 "reserve" 15 "reserve" 16 "reserve" 17 "reserve" 18 "reserve" 19 "reserve" 20 "reserve" 21 "reserve" ;
VAL_ 1428 HVLM_Restladezeit_HV_Bat_02 510 "Init" 511 "Fehler" ;
VAL_ 1428 HVLM_Lademodus_HV_Bat 0 "Sofortlademodus" 1 "zeitversetztes_Laden" ;
VAL_ 1428 HVLM_VK_STH_Einsatz 0 "Verbrennerstandheizung verbieten" 1 "Automatik (Verbrennerstandheizung erlauben)" 2 "Verbrennerstandheizung erzwingen" 3 "reserviert" 4 "reserviert" 5 "reserviert" 6 "Init" 7 "Fehler" ;
VAL_ 1428 HVLM_Anzeigetexte 0 "keine_Anzeige" 1 "Klappe_hinten_offen" 2 "Klappe_vorn_offen" 3 "Klappe_hinten_und_vorn_offen" 4 "oeffnen_nicht_moeglich" 5 "Stoerung_Ladeklappe" 7 "Fehler" ;
VAL_ 1428 HVLM_Bat_laden_aktiv 0 "inaktiv" 1 "aktiv" ;
VAL_ 1428 HVLM_HVEM_MaxLeistung 510 "Init" 511 "Fehler" ;
VAL_ 1428 HVLM_Standklima_Timer_Status 0 "Standklimatimer_nicht_aktiv" 1 "Standklimatimer_aktiv" ;
VAL_ 1428 HVLM_Fehler_Ladestecker 0 "kein_Fehler" 1 "Fehler" ;
VAL_ 1428 HVLM_Fehler_Verriegelung 0 "kein_Fehler" 1 "Fehler" ;
VAL_ 1428 HVLM_Ladeart 0 "keine_Auswahl" 1 "AC_Laden" 2 "DC_Laden" 3 "Konditionierung" ;
VAL_ 1428 HVLM_Status_Netz 0 "Fzg_nicht_am_Netz" 1 "Fzg_ist_am_Stromnetz" ;
VAL_ 1428 HVLM_HV_Anf 0 "keine_Anforderung" 1 "Laden_angefordert" 2 "Batteriekonditionierung_angefordert" 3 "Standklimatisierung_angefordert" ;
VAL_ 1428 HVLM_VK_Anf 0 "nicht_angefordert" 1 "angefordert" ;
VAL_ 1428 HVLM_Ladesystemhinweise 0 "kein_Hinweis" 1 "Ladesystem_defekt" 2 "Ladesaeule_inkompatibel" 3 "DC_Laden_nicht_moeglich" ;
VAL_ 1428 HVLM_VK_Modus 0 "keine Vorkonditionierung" 1 "Sofort-Konditionierung" 2 "zeitversetzte Konditionierung" 3 "Fehler" ;
VAL_ 1428 HVLM_Stecker_Status 0 "Init" 1 "kein_Stecker_gesteckt" 2 "Stecker_erkannt_nicht_verriegelt" 3 "Stecker_erkannt_und_verriegelt" ;
VAL_ 1428 HVLM_Langzeit_Laden 0 "keine_Anforderung" 1 "Anforderung_Reduzierung_Batterie_SOC_auf_Stufe_1" 2 "Anforderung_Reduzierung_Batterie_SOC_auf_Stufe_2" 3 "Fehler" ;
VAL_ 1428 HVLM_Klima_Temp 29 "VW_high_30C" 30 "Init" 31 "Fehler" ;
VAL_ 1428 HVLM_HSH_Anf 0 "keine_Anforderung" 1 "Heckscheibenheizung_Anf" ;
VAL_ 1428 HVLM_Bat_Konditionierung_Anf 0 "keine_Anforderung" 1 "HV_Bat_Konditionierung_Anf" ;
VAL_ 1428 HVLM_FSH_Anf 0 "keine_Anforderung" 1 "Frontscheibenheizung_Anf" ;
VAL_ 27 WFS_IMMO_ELV_RND 0 "Init" ;
VAL_ 1524 IL_Bel_FS_Ausstieg 0 "inaktiv" 1 "aktiv" ;
VAL_ 1524 IL_Bel_BFS_Ausstieg 0 "inaktiv" 1 "aktiv" ;
VAL_ 1524 IL_Bel_HFS_Ausstieg 0 "inaktiv" 1 "aktiv" ;
VAL_ 1524 IL_Bel_HBFS_Ausstieg 0 "inaktiv" 1 "aktiv" ;
VAL_ 1524 BCM1_Innenlicht_gedimmt_V 0 "100% Innenlicht" 1 "gedimmtes Innenlicht" ;
VAL_ 1524 BCM1_Innenlicht_gedimmt_H 0 "100% Innenlicht" 1 "gedimmtes Innenlicht" ;
VAL_ 1524 IL_Innenlicht_aktiv 0 "Innenlicht inaktiv" 1 "Innenlicht aktiv" ;
VAL_ 1524 IL_Klemme_30G_aktiv 0 "Kl_30G_abgeschaltet" 1 "eingeschaltet" ;
VAL_ 1524 BCM1_DI_Rampe_Innenlicht 0 "Dimmrampe 0" 1 "Dimmrampe 1" ;
VAL_ 1524 BCM1_DI_Rampe_Leselicht 0 "Dimmrampe 0" 1 "Dimmrampe 1" ;
VAL_ 1524 BCM1_Innenlicht_H 0 "Aus" 1 "Ein" ;
VAL_ 1524 BCM1_Innenlicht_V 0 "Aus" 1 "Ein" ;
VAL_ 1524 BCM1_Leselicht_Anf_hl 0 "Aus" 1 "Ein" ;
VAL_ 1524 BCM1_Leselicht_Anf_hr 0 "Aus" 1 "Ein" ;
VAL_ 1524 BCM1_Leselicht_Anf_vl 0 "Aus" 1 "Ein" ;
VAL_ 1524 BCM1_Leselicht_Anf_vr 0 "Aus" 1 "Ein" ;
VAL_ 1524 BCM1_Leuchten_Aus 0 "keine Aenderung" 1 "Aus" ;
VAL_ 1524 AMB_Charisma_FahrPr 0 "keine_Funktion" 1 "Programm_1" 2 "Programm_2" 3 "Programm_3" 4 "Programm_4" 5 "Programm_5" 6 "Programm_6" 7 "Programm_7" 8 "Programm_8" 9 "Programm_9" 10 "Programm_10" 11 "Programm_11" 12 "Programm_12" 13 "Programm_13" 14 "Programm_14" 15 "Programm_15" ;
VAL_ 1524 AMB_Charisma_Status 0 "Init" 1 "verfuegbar" 2 "nicht_verfuegbar" 3 "asynchron_durch_Fahrerwunsch" ;
VAL_ 2527679583 IPA_PL_Anzeige_links 0 "keine_PL_erkannt" 1 "links_Quer" 2 "links_Laengs" 3 "reserviert" ;
VAL_ 2527679583 IPA_PL_Anzeige_rechts 0 "keine_PL_erkannt" 1 "rechts_Quer" 2 "rechts_Laengs" 3 "reserviert" ;
VAL_ 2527679583 Parken_Seitenspiegel_Anf 0 "Keine_Anforderung" 1 "Seitenspiegel_anklappen" 2 "Seitenspiegel_abklappen" ;
VAL_ 2527679583 Parken_ZV_Schliessen 0 "Keine_Anforderung" 1 "ZV_verriegeln" 2 "ZV_safen" ;
VAL_ 2527679583 Parken_aktives_System_02 0 "Init" 1 "Keine_Aktivitaet" 2 "RPA" 3 "IPA" 4 "MA" 5 "TP" 6 "rTP" 7 "AAA" 8 "rAAA" 9 "ARA_1" 10 "PLA" 11 "RBF" 12 "PHP" 13 "RA" ;
VAL_ 2527679583 Parken_ZR_Sondermodus_Anf 0 "Init" 1 "Keine_Anforderung" 2 "Anforderung_Sondermodus" ;
VAL_ 2527679583 Parken_Schluesselsuche_Anf 0 "keine_Anforderung" 1 "Anforderung_Schluesselsuche" ;
VAL_ 2527679583 Parken_FFB_LED_Anf 0 "keine_Anforderung" 1 "Abbruch_Fehler" 2 "Bereit_OK" 3 "Beendet" ;
VAL_ 2527679583 Parken_Wegfahrsperren_Anf 0 "keine_Anforderung" 1 "Anforderung_Fahreruebernahme" 2 "Anforderung_Fahreruebergabe" ;
VAL_ 2527679583 Parken_Aktivierungslicht_Anf 0 "keine_Anforderung" 1 "Aktivierungslicht" ;
VAL_ 2527679583 Parken_Fahrtrichtungslicht_Anf 0 "keine_Anforderung" 1 "Vorwaerts" 2 "Rueckwaerts" ;
VAL_ 2527679583 Parken_Lichtnachlauf_Anf 0 "keine_Anforderung" 1 "Anforderung_Lichtnachlauf" ;
VAL_ 2527679583 IPA_Akustik_PL_gefunden 0 "keinen_Ton_ausgeben" 1 "Ton_ausgeben" ;
VAL_ 2527679583 Parken_Blinker_li_Anf 0 "keine_Anforderung" 1 "Blinker_links_aktivieren" ;
VAL_ 2527679583 Parken_Blinker_re_Anf 0 "keine_Anforderung" 1 "Blinker_rechts_aktivieren" ;
VAL_ 2527679583 Parken_Fahrerhinweise_Anf 0 "keine_Anforderung" 1 "Fahrerhinweise_anzeigen" ;
VAL_ 2527679583 Parken_Bestaetigungsblinken_Anf 0 "keine_Anforderung" 1 "Erfolgsblinken_Einparken" 2 "Abbruchsblinken" 3 "Erfolgsblinken_Ausparken" ;
VAL_ 2527679583 Parken_Fahrbereitschaftlicht_Anf 0 "keine_Anforderung" 1 "Fahrbereitschaftslicht" ;
VAL_ 2527679583 Parken_Lichtsteuerung_Anf 0 "keine_Anforderung" 1 "Automatik_Lichtmodus_aktivieren" ;
VAL_ 2527679583 IPA_Anf_Meldungen 0 "keine Meldung" 1 "beendet" 2 "Fahrinf_Bremse_FT_betaetigen" 3 "Suche_fortsetzen_ESC_Eingriff" 4 "n_a_temp_ESC_deaktiviert" 5 "n_a_temp_Anhaengerbetrieb" 6 "Suche_Zeitlimit_ueberschritten" 7 "Undefined" 8 "Fahrinf_PaLueSu_aufschalten" 9 "RPARemoteWunschAbgebrochen" 10 "IPAGeschwindigkeitReduzieren" 11 "IPARPAAktivierung2" 12 "AP_nicht_moeglich" 13 "RPAGarageStart" 14 "n_a_temp_Tuer_Heckklappe_offen" 15 "Stby_Tuer_Heckklappe_schliessen" 16 "PP_aktiv_nur_aussen_bedienbar" 17 "RPAUebergabe2" 18 "n_a_Offroad_Modus" 19 "PP_Schluessel_oder_App_bedienen" 20 "RPAUebergabe1" 21 "PP_Schluessel_bedienen" 22 "IPAAbbruchSuchfahrt" 23 "Systemstoerung_Service" 24 "n_a_temp_Sensorsicht" 25 "IPAAbbruchSuchfahrtLadestecke" 26 "IPAPausierenWeiterfahrt" 27 "n_a_temp_FAS_aktiv" 28 "PP_BT_unterbrochen" 29 "Hindernis_in_Fahrtrichtung" 30 "IPAAusparkenBlinker" 31 "RPAUebernahme" 32 "Suche_Rangierflaeche_zu_klein" 33 "n_a_temp_Drive_Select" 34 "IPAAktivierung1" 35 "Fahrinf_Fahrtrichtungswechsel" 36 "RPARemoteWunsch" 37 "GP_Fzgposition_vor_Garage" 38 "GP_RT_Garage_oeffnen" 39 "GP_Kein_Zuparken" 40 "Suche_Fahrinfo_beachten" 41 "GP_Fzgposition_freie_Parkflaeche" 42 "GP_n_a_temp_Laser" 43 "Geschwindigkeitsueberschreitung" 44 "Fahrinf_Weiter_vorfahren" 45 "RPAAktivierung1" 46 "Fahrinf_Anhalten" 47 "GP_AP_nicht_moeglich_Fahrweg" 48 "PP_Gang_Schluesselauthentifizier" 49 "Fahrhinweis_FT_betaetigen" 50 "PP_aktiv_Hinweis_FUEN" 128 "Disclaimer_LP_rechts" 129 "Disclaimer_LP_links" 130 "Disclaimer_RQ_rechts" 131 "Disclaimer_RQ_links" 132 "Disclaimer_VQ_rechts" 133 "Disclaimer_VQ_links" 134 "Disclaimer_AP_rechts" 135 "Disclaimer_AP_links" 136 "IPARPAAktivierung3" 137 "IPAAbbruchLenkeingriff" 138 "IPAAbbruchAnhaenger" 139 "IPARPAAktivierung4" 140 "IPAAbbruchZeitlimit" 141 "IPAFahrzeugAusgeparkt" 142 "IPAFahrzeugEingeparkt" 143 "IPAPausieren" 144 "IPAAbbruchESC" 145 "Stby_Verkehr_erkannt" 146 "MAAbbruchLenkeingriff" 147 "IPAAbbruchSchaltung" 148 "IPAAbbruchParklueckeKlein" 149 "IPABordsteinheber2" 150 "IPAAbbruchSensorsicht" 151 "Beendet_Stoerung_Fzgverbindung" 152 "Beendet_selbst_bremsen" 153 "IPAAbbruchFahrdynamischerEing" 154 "IPAAbbruchFalscheBewegungsric" 155 "IPAAbbruchDiETaSchliesskreuz" 156 "IPAPausierenHindernis" 157 "FUEN_moeglich" 158 "IPABordsteinheber4" 159 "IPAAbbruchOffroadModus" 160 "IPABordsteinheber5" 161 "PP_Fehler_Schluesselautorisier" 162 "IPABordsteinheber6" 163 "IPABordsteinheber7" 164 "Stby_FT_oder_RT_betaetigen" 165 "Stby_Hindernis_Richtungswechsel" 166 "Stby_erhoehter_Fahrwiderstand" 167 "Abbruch_EPB_aktiviert" 168 "Abbruch_MO_nicht_bereit" 169 "IPAAbbruchPDC" 170 "Abbruch_Gurtschloss_gesteckt" 171 "IPAAbbruchGeschwindigkeitHoch" 172 "IPAPausierenTueren" 173 "IPAAbbruchNotstopp" 174 "IPAAbbruchFahrerabwesenheit" 175 "IPAAbbruchSystempartner" 176 "PosOK_Lenkrad_loslassen_Bremse" 177 "PosOK_Lenkrad_loslassen_FT" 178 "Wiederaufnahme_FT_betaetigen" 179 "IPABordsteinheber9" 180 "IPAAbbruchKlemme15Aus" 181 "IPABordsteinheber8" 192 "TPA_aborted_deviated_from_trajec" 193 "TPA_aborted_limited_visibility" 194 "TPA_aborted_localization_failure" 195 "TPA_aborted_System_error" 196 "TPA_aborted_TPA_canceled" 197 "TPA_unavlbl_localization_failure" 198 "TPA_unavlbl_limited_visibility" 199 "TPA_unavlbl_System_error" 200 "TPA_temp_unavailable" 201 "rTPA_nicht_verfuegbar_TPA_bis_ZP" 202 "TPA_PP_belegt_TPA_Altern" 203 "TPA_PP_belegt_IPA_0_Altern" 204 "TPA_PP_belegt_IPA_1_Altern" 205 "TPA_PP_belegt_IPA_mehr_Altern" 206 "TPA_ausgerichtetes_Parken_aktiv" 207 "TPA_Ausparken_eingeschraenkt" ;
